VERSION ""

NS_ :

BS_:

BU_: Dummy_PCE EBOOST_OBD_PCE EOCM2cp_K2_PCE EPSb_PCE SDM_PCE EBCM_PCE EPSa_PCE CMMb_PCE CMMa_PCE CGM3b_PCE ADIMa_PCE

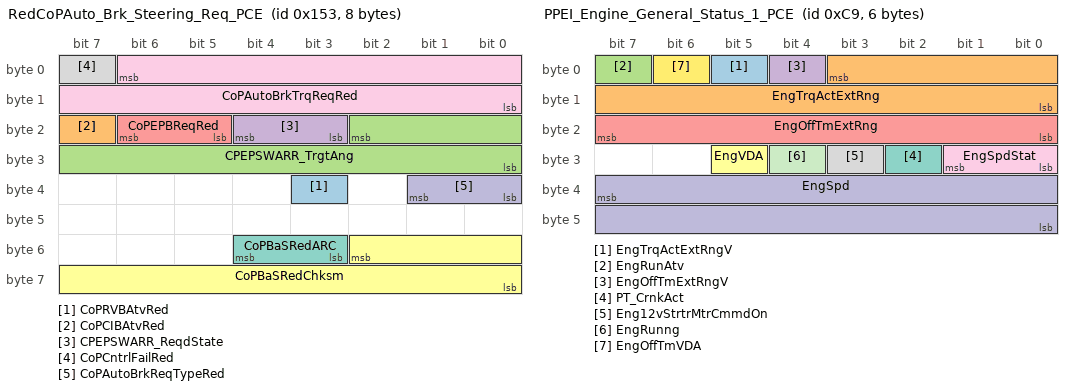
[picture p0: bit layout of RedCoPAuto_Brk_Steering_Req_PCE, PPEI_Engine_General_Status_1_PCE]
BO_ 339 RedCoPAuto_Brk_Steering_Req_PCE: 8 EOCM2cp_K2_PCE
 SG_ CoPRVBAtvRed : 35|1@0+ (1,0) [0|1] ""  ADIMa_PCE,EBOOST_OBD_PCE,EBCM_PCE
 SG_ CoPCIBAtvRed : 23|1@0+ (1,0) [0|1] ""  ADIMa_PCE,EBOOST_OBD_PCE,EBCM_PCE
 SG_ CPEPSWARR_TrgtAng : 18|11@0- (1,0) [-1024|1023] "deg"  ADIMa_PCE,EBOOST_OBD_PCE,EBCM_PCE
 SG_ CPEPSWARR_ReqdState : 20|2@0+ (1,0) [0|3] ""  ADIMa_PCE,EBOOST_OBD_PCE,EBCM_PCE
 SG_ CoPEPBReqRed : 22|2@0+ (1,0) [0|3] ""  ADIMa_PCE,EBOOST_OBD_PCE,EBCM_PCE
 SG_ CoPBaSRedChksm : 50|11@0+ (1,0) [0|2047] ""  ADIMa_PCE,EBOOST_OBD_PCE,EBCM_PCE
 SG_ CoPBaSRedARC : 52|2@0+ (1,0) [0|3] ""  ADIMa_PCE,EBOOST_OBD_PCE,EBCM_PCE
 SG_ CoPCntrlFailRed : 7|1@0+ (1,0) [0|1] ""  ADIMa_PCE,EBOOST_OBD_PCE,EBCM_PCE
 SG_ CoPAutoBrkTrqReqRed : 6|15@0+ (2,-65534) [-65534|0] "Nm"  ADIMa_PCE,EBOOST_OBD_PCE,EBCM_PCE
 SG_ CoPAutoBrkReqTypeRed : 33|2@0+ (1,0) [0|3] ""  ADIMa_PCE,EBOOST_OBD_PCE,EBCM_PCE

BO_ 201 PPEI_Engine_General_Status_1_PCE: 6 EBCM_PCE
 SG_ EngTrqActExtRngV : 5|1@0+ (1,0) [0|1] "" Vector__XXX
 SG_ EngTrqActExtRng : 3|12@0+ (0.5,-848) [-848|1199.5] "Nm" Vector__XXX
 SG_ EngRunAtv : 7|1@0+ (1,0) [0|1] ""  SDM_PCE
 SG_ EngOffTmExtRngV : 4|1@0+ (1,0) [0|1] "" Vector__XXX
 SG_ EngOffTmExtRng : 23|8@0+ (4,0) [0|1020] "min" Vector__XXX
 SG_ EngVDA : 29|1@0+ (1,0) [0|1] "" Vector__XXX
 SG_ PT_CrnkAct : 26|1@0+ (1,0) [0|1] "" Vector__XXX
 SG_ Eng12vStrtrMtrCmmdOn : 27|1@0+ (1,0) [0|1] "" Vector__XXX
 SG_ EngSpdStat : 25|2@0+ (1,0) [0|3] "" Vector__XXX
 SG_ EngSpd : 39|16@0+ (0.25,0) [0|16383.75] "rpm" Vector__XXX
 SG_ EngRunng : 28|1@0+ (1,0) [0|1] "" Vector__XXX
 SG_ EngOffTmVDA : 6|1@0+ (1,0) [0|1] "" Vector__XXX

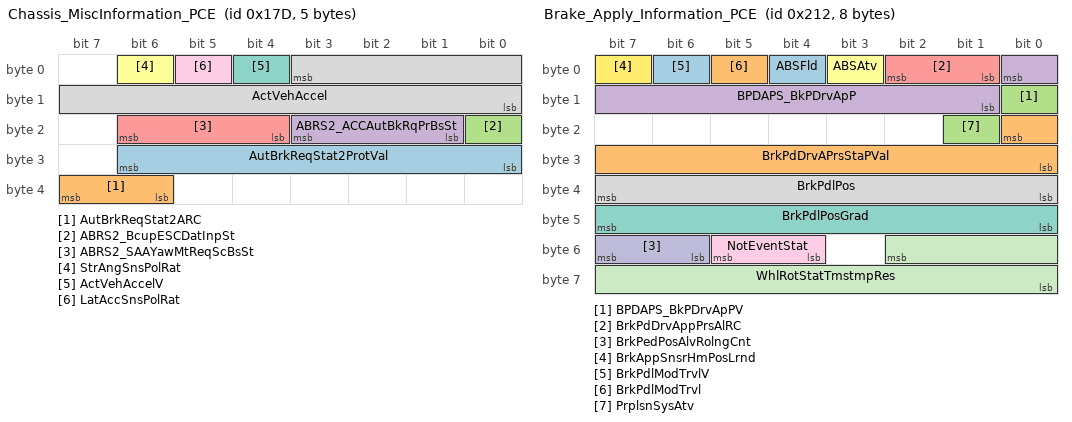
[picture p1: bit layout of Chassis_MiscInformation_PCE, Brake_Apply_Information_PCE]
BO_ 381 Chassis_MiscInformation_PCE: 5 EBCM_PCE
 SG_ AutBrkReqStat2ProtVal : 30|7@0+ (1,0) [0|127] "" Vector__XXX
 SG_ AutBrkReqStat2ARC : 39|2@0+ (1,0) [0|3] "" Vector__XXX
 SG_ ABRS2_BcupESCDatInpSt : 16|1@0+ (1,0) [0|1] "" Vector__XXX
 SG_ ABRS2_ACCAutBkRqPrBsSt : 19|3@0+ (1,0) [0|7] "" Vector__XXX
 SG_ ABRS2_SAAYawMtReqScBsSt : 22|3@0+ (1,0) [0|7] "" Vector__XXX
 SG_ StrAngSnsPolRat : 6|1@0+ (1,0) [0|1] ""  Dummy_PCE
 SG_ ActVehAccelV : 4|1@0+ (1,0) [0|1] "" Vector__XXX
 SG_ ActVehAccel : 3|12@0- (0.01,0) [-20.48|20.47] "m/s^2" Vector__XXX
 SG_ LatAccSnsPolRat : 5|1@0+ (1,0) [0|1] ""  Dummy_PCE

BO_ 530 Brake_Apply_Information_PCE: 8 EBCM_PCE
 SG_ ABSFld : 4|1@0+ (1,0) [0|1] ""  SDM_PCE,EBOOST_OBD_PCE
 SG_ BrkPdDrvAPrsStaPVal : 16|9@0+ (1,0) [0|511] ""  EBOOST_OBD_PCE
 SG_ BPDAPS_BkPDrvApPV : 8|1@0+ (1,0) [0|1] ""  EBOOST_OBD_PCE
 SG_ BPDAPS_BkPDrvApP : 0|8@0+ (75,0) [0|19125] "kPa"  EBOOST_OBD_PCE
 SG_ BrkPdDrvAppPrsAlRC : 2|2@0+ (1,0) [0|3] ""  EBOOST_OBD_PCE
 SG_ ABSAtv : 3|1@0+ (1,0) [0|1] ""  SDM_PCE,EBOOST_OBD_PCE
 SG_ BrkPdlPosGrad : 47|8@0- (40,0) [-5120|5080] "%/s"  EBOOST_OBD_PCE
 SG_ BrkPdlPos : 39|8@0+ (0.392157,0) [0|100.000035] "% full"  EBOOST_OBD_PCE
 SG_ NotEventStat : 53|2@0+ (1,0) [0|3] ""  EBOOST_OBD_PCE
 SG_ BrkPedPosAlvRolngCnt : 55|2@0+ (1,0) [0|3] ""  EBOOST_OBD_PCE
 SG_ WhlRotStatTmstmpRes : 50|11@0+ (0.002,0) [0|4.094] "uSec"  EBOOST_OBD_PCE
 SG_ BrkAppSnsrHmPosLrnd : 7|1@0+ (1,0) [0|1] ""  EBOOST_OBD_PCE
 SG_ BrkPdlModTrvlV : 6|1@0+ (1,0) [0|1] ""  EBOOST_OBD_PCE
 SG_ BrkPdlModTrvl : 5|1@0+ (1,0) [0|1] ""  EBOOST_OBD_PCE
 SG_ PrplsnSysAtv : 17|1@0+ (1,0) [0|1] ""  EBOOST_OBD_PCE,CGM3b_PCE

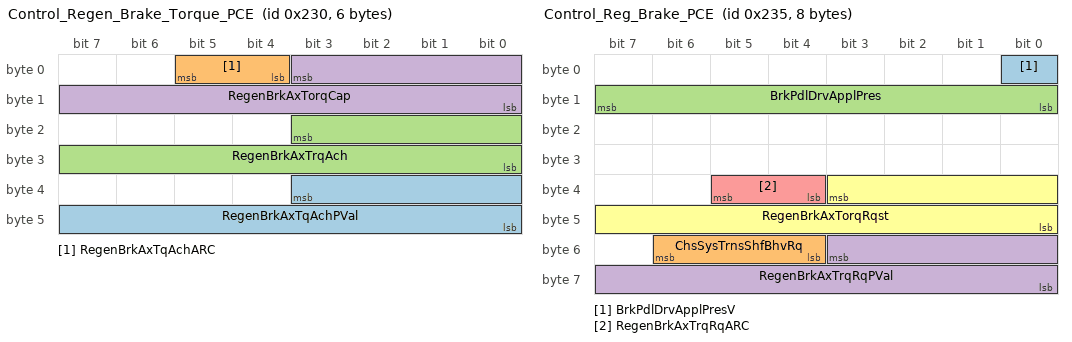
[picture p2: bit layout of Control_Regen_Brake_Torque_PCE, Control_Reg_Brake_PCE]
BO_ 560 Control_Regen_Brake_Torque_PCE: 6 CGM3b_PCE
 SG_ RegenBrkAxTqAchPVal : 35|12@0+ (1,0) [0|4095] ""  EBCM_PCE
 SG_ RegenBrkAxTqAchARC : 5|2@0+ (1,0) [0|3] ""  EBCM_PCE
 SG_ RegenBrkAxTrqAch : 19|12@0+ (2,0) [0|8190] "Nm"  EBCM_PCE
 SG_ RegenBrkAxTorqCap : 3|12@0+ (2,0) [0|8190] "Nm"  EBCM_PCE

BO_ 603 USDT_Req_to_CMM_PCE: 8 CGM3b_PCE
 SG_ DgnInf : 7|64@0+ (1,0) [0|1.84467440737096E+019] ""  CMMa_PCE

BO_ 565 Control_Reg_Brake_PCE: 8 EBCM_PCE
 SG_ BrkPdlDrvApplPresV : 0|1@0+ (1,0) [0|1] ""  ADIMa_PCE,CGM3b_PCE
 SG_ ChsSysTrnsShfBhvRq : 54|3@0+ (1,0) [0|7] ""  ADIMa_PCE,CGM3b_PCE
 SG_ BrkPdlDrvApplPres : 15|8@0+ (75,0) [0|19125] "kPa"  ADIMa_PCE,CGM3b_PCE
 SG_ RegenBrkAxTrqRqPVal : 51|12@0+ (1,0) [0|4095] ""  ADIMa_PCE,CGM3b_PCE
 SG_ RegenBrkAxTrqRqARC : 37|2@0+ (1,0) [0|3] ""  ADIMa_PCE,CGM3b_PCE
 SG_ RegenBrkAxTorqRqst : 35|12@0+ (2,0) [0|8190] "Nm"  ADIMa_PCE,CGM3b_PCE

BO_ 1347 UUDT_Resp_From_EBCM_PCE: 8 EBCM_PCE
 SG_ DgnInf_CE543 : 7|64@0+ (1,0) [0|1.84467440737096E+019] ""  CGM3b_PCE

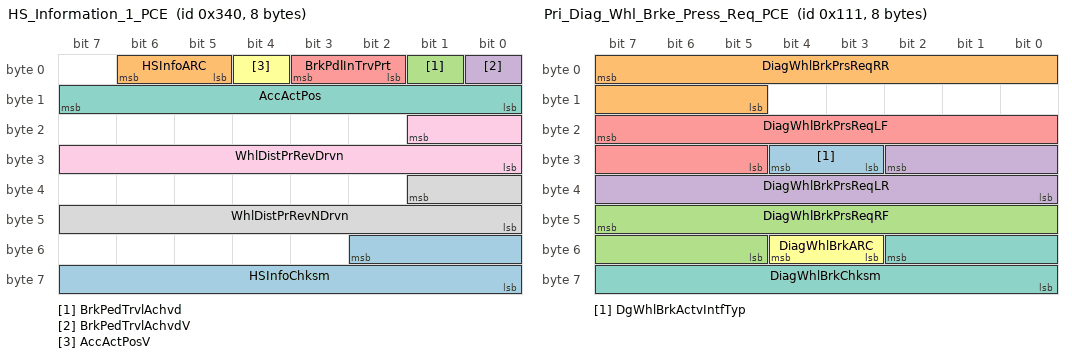
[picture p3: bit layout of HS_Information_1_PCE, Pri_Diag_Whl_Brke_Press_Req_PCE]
BO_ 832 HS_Information_1_PCE: 8 EBCM_PCE
 SG_ HSInfoChksm : 50|11@0+ (1,0) [0|2047] "" Vector__XXX
 SG_ HSInfoARC : 6|2@0+ (1,0) [0|3] "" Vector__XXX
 SG_ BrkPedTrvlAchvd : 1|1@0+ (1,0) [0|1] ""  SDM_PCE
 SG_ BrkPedTrvlAchvdV : 0|1@0+ (1,0) [0|1] ""  SDM_PCE
 SG_ BrkPdlInTrvPrt : 3|2@0+ (1,0) [0|3] "" Vector__XXX
 SG_ AccActPosV : 4|1@0+ (1,0) [0|1] "" Vector__XXX
 SG_ AccActPos : 15|8@0+ (0.392157,0) [0|100.000035] "%" Vector__XXX
 SG_ WhlDistPrRevNDrvn : 33|10@0+ (3,800) [800|3869] "mm"  SDM_PCE
 SG_ WhlDistPrRevDrvn : 17|10@0+ (3,800) [800|3869] "mm"  SDM_PCE

BO_ 1622 USDT_Resp_From_CMMb_PCE: 8 CMMb_PCE
 SG_ DgnInf : 7|64@0+ (1,0) [0|1.84467440737096E+019] ""  CGM3b_PCE

BO_ 1351 UUDT_Resp_From_SDM_PCE: 8 SDM_PCE
 SG_ DgnInf_CE547 : 7|64@0+ (1,0) [0|1.84467440737096E+019] ""  CGM3b_PCE

BO_ 1346 UUDT_Resp_From_EPSa_PCE: 8 EPSa_PCE
 SG_ DgnInf_CE542 : 7|64@0+ (1,0) [0|1.84467440737096E+019] ""  CGM3b_PCE

BO_ 1607 USDT_Resp_From_SDM_PCE: 8 SDM_PCE
 SG_ DgnInf : 7|64@0+ (1,0) [0|1.84467440737096E+019] ""  CGM3b_PCE

BO_ 1602 USDT_Resp_From_EPSa_PCE: 8 EPSa_PCE
 SG_ DgnInf : 7|64@0+ (1,0) [0|1.84467440737096E+019] ""  CGM3b_PCE

BO_ 273 Pri_Diag_Whl_Brke_Press_Req_PCE: 8 ADIMa_PCE
 SG_ DgWhlBrkActvIntfTyp : 28|2@0+ (1,0) [0|3] ""  EBCM_PCE
 SG_ DiagWhlBrkPrsReqRR : 7|11@0+ (10,0) [0|20470] "Kpa"  EBCM_PCE
 SG_ DiagWhlBrkPrsReqRF : 47|11@0+ (10,0) [0|20470] "Kpa"  EBCM_PCE
 SG_ DiagWhlBrkPrsReqLR : 26|11@0+ (10,0) [0|20470] "Kpa"  EBCM_PCE
 SG_ DiagWhlBrkPrsReqLF : 23|11@0+ (10,0) [0|20470] "Kpa"  EBCM_PCE
 SG_ DiagWhlBrkARC : 52|2@0+ (1,0) [0|3] ""  EBCM_PCE
 SG_ DiagWhlBrkChksm : 50|11@0+ (1,0) [0|2047] ""  EBCM_PCE

BO_ 598 USDT_Req_to_CMMb_PCE: 8 CGM3b_PCE
 SG_ DgnInf : 7|64@0+ (1,0) [0|1.84467440737096E+019] ""  CMMb_PCE

BO_ 1352 UUDT_Resp_From_EPSb_PCE: 8 EPSb_PCE
 SG_ DgnInf_CE548 : 7|64@0+ (1,0) [0|1.84467440737096E+019] ""  CGM3b_PCE

BO_ 578 USDT_Req_to_EPSa_PCE: 8 CGM3b_PCE
 SG_ DgnInf : 7|64@0+ (1,0) [0|1.84467440737096E+019] ""  EPSa_PCE

BO_ 579 USDT_Req_to_EBCM_PCE: 8 CGM3b_PCE
 SG_ DgnInf : 7|64@0+ (1,0) [0|1.84467440737096E+019] ""  EBCM_PCE

BO_ 1364 UUDT_Resp_From_EBoost_PCE: 8 EBOOST_OBD_PCE
 SG_ DgnInf_CE554 : 7|64@0+ (1,0) [0|1.84467440737096E+019] ""  CGM3b_PCE

BO_ 1355 UUDT_Resp_From_EOCM2cp_K2_PCE: 8 EOCM2cp_K2_PCE
 SG_ DgnInf_CE54B : 7|64@0+ (1,0) [0|1.84467440737096E+019] ""  CGM3b_PCE

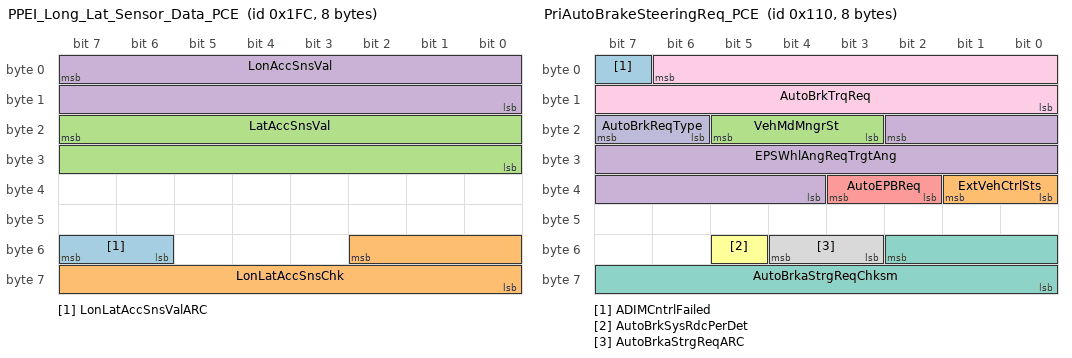
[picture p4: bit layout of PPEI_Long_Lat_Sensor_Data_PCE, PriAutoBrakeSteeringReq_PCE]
BO_ 508 PPEI_Long_Lat_Sensor_Data_PCE: 8 SDM_PCE
 SG_ LonLatAccSnsValARC : 55|2@0+ (1,0) [0|3] ""  EBCM_PCE,EBOOST_OBD_PCE
 SG_ LonLatAccSnsChk : 50|11@0+ (1,0) [0|2047] ""  EBCM_PCE,EBOOST_OBD_PCE
 SG_ LatAccSnsVal : 23|16@0- (0.00012207,0) [-3.99998976|3.99986769] "g's"  EBCM_PCE,EBOOST_OBD_PCE
 SG_ LonAccSnsVal : 7|16@0- (0.00012207,0) [-3.99998976|3.99986769] "g's"  EBCM_PCE,EBOOST_OBD_PCE

BO_ 1603 USDT_Resp_From_EBCM_PCE: 8 EBCM_PCE
 SG_ DgnInf : 7|64@0+ (1,0) [0|1.84467440737096E+019] ""  CGM3b_PCE

BO_ 272 PriAutoBrakeSteeringReq_PCE: 8 ADIMa_PCE
 SG_ ADIMCntrlFailed : 7|1@0+ (1,0) [0|1] ""  SDM_PCE,EOCM2cp_K2_PCE,EPSb_PCE,EPSa_PCE,EBOOST_OBD_PCE,EBCM_PCE
 SG_ ExtVehCtrlSts : 33|2@0+ (1,0) [0|2] ""  EBOOST_OBD_PCE,EBCM_PCE
 SG_ VehMdMngrSt : 21|3@0+ (1,0) [0|7] ""  EPSb_PCE,SDM_PCE,EOCM2cp_K2_PCE,EPSa_PCE,EBOOST_OBD_PCE,EBCM_PCE
 SG_ EPSWhlAngReqTrgtAng : 18|15@0- (0.0625,0) [-1024|1023.9375] "Deg"  EPSb_PCE,SDM_PCE,EPSa_PCE,EBOOST_OBD_PCE,EBCM_PCE
 SG_ AutoEPBReq : 35|2@0+ (1,0) [0|3] ""  EPSb_PCE,SDM_PCE,EPSa_PCE,EBOOST_OBD_PCE,EBCM_PCE
 SG_ AutoBrkSysRdcPerDet : 53|1@0+ (1,0) [0|1] ""  EBCM_PCE,EBOOST_OBD_PCE
 SG_ AutoBrkaStrgReqChksm : 50|11@0+ (1,0) [0|2047] ""  EPSb_PCE,SDM_PCE,EPSa_PCE,EBOOST_OBD_PCE,EBCM_PCE
 SG_ AutoBrkaStrgReqARC : 52|2@0+ (1,0) [0|3] ""  EPSb_PCE,SDM_PCE,EPSa_PCE,EBOOST_OBD_PCE,EBCM_PCE
 SG_ AutoBrkTrqReq : 6|15@0+ (2,-65534) [-65534|0] "Nm"  EPSb_PCE,SDM_PCE,EPSa_PCE,EBOOST_OBD_PCE,EBCM_PCE
 SG_ AutoBrkReqType : 23|2@0+ (1,0) [0|3] ""  EPSb_PCE,SDM_PCE,EPSa_PCE,EBOOST_OBD_PCE,EBCM_PCE

BO_ 583 USDT_Req_to_SDM_PCE: 8 CGM3b_PCE
 SG_ DgnInf : 7|64@0+ (1,0) [0|1.84467440737096E+019] ""  SDM_PCE

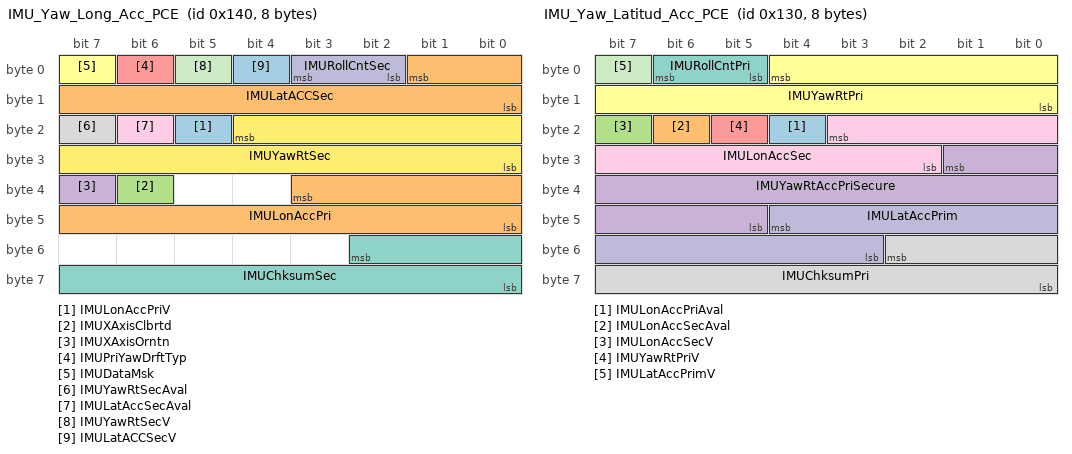
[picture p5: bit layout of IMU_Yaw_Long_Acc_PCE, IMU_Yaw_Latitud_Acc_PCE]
BO_ 320 IMU_Yaw_Long_Acc_PCE: 8 SDM_PCE
 SG_ IMULonAccPriV : 21|1@0+ (1,0) [0|1] ""  EOCM2cp_K2_PCE,CGM3b_PCE,EBCM_PCE,EBOOST_OBD_PCE
 SG_ IMULonAccPri : 35|12@0- (0.015625,0) [-32|31.984375] "m/s^2"  CGM3b_PCE,EOCM2cp_K2_PCE,EBCM_PCE,EBOOST_OBD_PCE
 SG_ IMUXAxisClbrtd : 38|1@0+ (1,0) [0|1] ""  EOCM2cp_K2_PCE,CGM3b_PCE,EBCM_PCE,EBOOST_OBD_PCE
 SG_ IMUXAxisOrntn : 39|1@0+ (1,0) [0|1] ""  EOCM2cp_K2_PCE,CGM3b_PCE,EBCM_PCE,EBOOST_OBD_PCE
 SG_ IMUPriYawDrftTyp : 6|1@0+ (1,0) [0|1] ""  EOCM2cp_K2_PCE,CGM3b_PCE,EBCM_PCE,EBOOST_OBD_PCE
 SG_ IMUDataMsk : 7|1@0+ (1,0) [0|1] ""  CGM3b_PCE,EOCM2cp_K2_PCE,EBCM_PCE,EBOOST_OBD_PCE
 SG_ IMUChksumSec : 50|11@0+ (1,0) [0|2047] ""  CGM3b_PCE,EOCM2cp_K2_PCE,EBOOST_OBD_PCE,EBCM_PCE
 SG_ IMUYawRtSecAval : 23|1@0+ (1,0) [0|1] ""  EOCM2cp_K2_PCE,CGM3b_PCE,EBOOST_OBD_PCE,EBCM_PCE
 SG_ IMULatAccSecAval : 22|1@0+ (1,0) [0|1] ""  CGM3b_PCE,EOCM2cp_K2_PCE,EBOOST_OBD_PCE,EBCM_PCE
 SG_ IMURollCntSec : 3|2@0+ (1,0) [0|3] ""  EOCM2cp_K2_PCE,CGM3b_PCE,EBOOST_OBD_PCE,EBCM_PCE
 SG_ IMUYawRtSecV : 5|1@0+ (1,0) [0|1] ""  EOCM2cp_K2_PCE,CGM3b_PCE,EBOOST_OBD_PCE,EBCM_PCE
 SG_ IMUYawRtSec : 20|13@0- (0.024,0) [-98.304|98.28] "deg/sec"  EOCM2cp_K2_PCE,CGM3b_PCE,EBOOST_OBD_PCE,EBCM_PCE
 SG_ IMULatACCSecV : 4|1@0+ (1,0) [0|1] ""  CGM3b_PCE,EOCM2cp_K2_PCE,EBOOST_OBD_PCE,EBCM_PCE
 SG_ IMULatACCSec : 1|10@0- (0.0625,0) [-32|31.9375] "m/s^2"  CGM3b_PCE,EOCM2cp_K2_PCE,EBOOST_OBD_PCE,EBCM_PCE

BO_ 304 IMU_Yaw_Latitud_Acc_PCE: 8 SDM_PCE
 SG_ IMULonAccPriAval : 20|1@0+ (1,0) [0|1] ""  CGM3b_PCE,EOCM2cp_K2_PCE,EBCM_PCE,EBOOST_OBD_PCE
 SG_ IMULonAccSecAval : 22|1@0+ (1,0) [0|1] ""  CGM3b_PCE,EOCM2cp_K2_PCE,EBCM_PCE,EBOOST_OBD_PCE
 SG_ IMULonAccSecV : 23|1@0+ (1,0) [0|1] ""  CGM3b_PCE,EOCM2cp_K2_PCE,EBCM_PCE,EBOOST_OBD_PCE
 SG_ IMUYawRtAccPriSecure : 25|13@0- (0.25,0) [-1024|1023.75] "deg/s^2"  CGM3b_PCE,EOCM2cp_K2_PCE,EBCM_PCE,EBOOST_OBD_PCE
 SG_ IMUYawRtPriV : 21|1@0+ (1,0) [0|1] ""  CGM3b_PCE,EOCM2cp_K2_PCE,EBOOST_OBD_PCE,EBCM_PCE
 SG_ IMUYawRtPri : 4|13@0- (0.024,0) [-98.304|98.28] "deg/sec"  CGM3b_PCE,EOCM2cp_K2_PCE,EBOOST_OBD_PCE,EBCM_PCE
 SG_ IMURollCntPri : 6|2@0+ (1,0) [0|3] ""  CGM3b_PCE,EOCM2cp_K2_PCE,EBOOST_OBD_PCE,EBCM_PCE
 SG_ IMUChksumPri : 50|11@0+ (1,0) [0|2047] ""  CGM3b_PCE,EOCM2cp_K2_PCE,EBOOST_OBD_PCE,EBCM_PCE
 SG_ IMULonAccSec : 19|10@0- (0.0625,0) [-32|31.9375] "m/s^2"  CGM3b_PCE,EOCM2cp_K2_PCE,EBCM_PCE,EBOOST_OBD_PCE
 SG_ IMULatAccPrim : 44|10@0- (0.0625,0) [-32|31.9375] "m/s^2"  CGM3b_PCE,EOCM2cp_K2_PCE,EBOOST_OBD_PCE,EBCM_PCE
 SG_ IMULatAccPrimV : 7|1@0+ (1,0) [0|1] ""  CGM3b_PCE,EOCM2cp_K2_PCE,EBOOST_OBD_PCE,EBCM_PCE

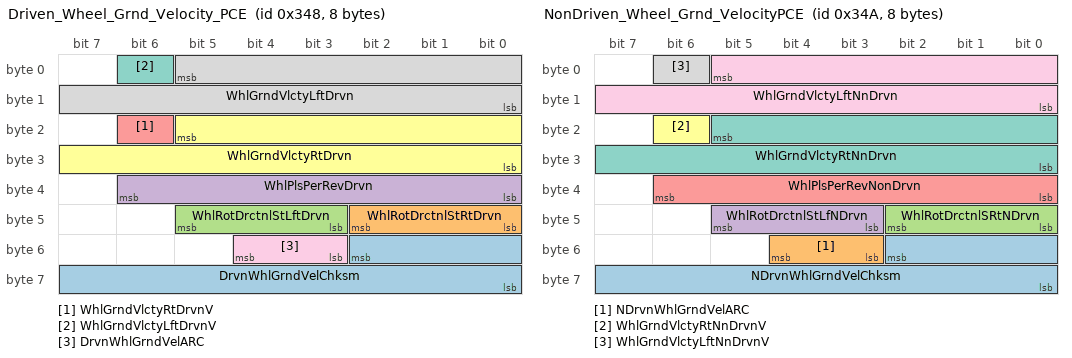
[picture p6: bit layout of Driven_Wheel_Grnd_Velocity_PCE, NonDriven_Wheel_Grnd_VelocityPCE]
BO_ 840 Driven_Wheel_Grnd_Velocity_PCE: 8 EBCM_PCE
 SG_ DrvnWhlGrndVelChksm : 50|11@0+ (1,0) [0|2047] ""  ADIMa_PCE,EPSb_PCE,EPSa_PCE,EBOOST_OBD_PCE
 SG_ WhlRotDrctnlStRtDrvn : 42|3@0+ (1,0) [0|7] ""  ADIMa_PCE,EBOOST_OBD_PCE,EOCM2cp_K2_PCE
 SG_ WhlRotDrctnlStLftDrvn : 45|3@0+ (1,0) [0|7] ""  ADIMa_PCE,EBOOST_OBD_PCE,EOCM2cp_K2_PCE
 SG_ WhlPlsPerRevDrvn : 38|7@0+ (1,0) [0|127] ""  ADIMa_PCE,EBOOST_OBD_PCE,EPSb_PCE,EPSa_PCE,EOCM2cp_K2_PCE
 SG_ WhlGrndVlctyRtDrvnV : 22|1@0+ (1,0) [0|1] ""  CGM3b_PCE,ADIMa_PCE,EBOOST_OBD_PCE,SDM_PCE,EPSb_PCE,EPSa_PCE,EOCM2cp_K2_PCE
 SG_ WhlGrndVlctyRtDrvn : 21|14@0+ (0.03125,0) [0|511.96875] "km / h"  CGM3b_PCE,ADIMa_PCE,EBOOST_OBD_PCE,SDM_PCE,EPSb_PCE,EPSa_PCE,EOCM2cp_K2_PCE
 SG_ WhlGrndVlctyLftDrvnV : 6|1@0+ (1,0) [0|1] ""  CGM3b_PCE,ADIMa_PCE,EBOOST_OBD_PCE,SDM_PCE,EPSb_PCE,EPSa_PCE,EOCM2cp_K2_PCE
 SG_ WhlGrndVlctyLftDrvn : 5|14@0+ (0.03125,0) [0|511.96875] "km / h"  CGM3b_PCE,ADIMa_PCE,EBOOST_OBD_PCE,SDM_PCE,EPSb_PCE,EPSa_PCE,EOCM2cp_K2_PCE
 SG_ DrvnWhlGrndVelARC : 52|2@0+ (1,0) [0|3] ""  ADIMa_PCE,EPSb_PCE,EPSa_PCE,EBOOST_OBD_PCE

BO_ 842 NonDriven_Wheel_Grnd_VelocityPCE: 8 EBCM_PCE
 SG_ NDrvnWhlGrndVelChksm : 50|11@0+ (1,0) [0|2047] ""  ADIMa_PCE,EPSb_PCE,EPSa_PCE,EBOOST_OBD_PCE
 SG_ NDrvnWhlGrndVelARC : 52|2@0+ (1,0) [0|3] ""  ADIMa_PCE,EPSb_PCE,EPSa_PCE,EBOOST_OBD_PCE
 SG_ WhlRotDrctnlSRtNDrvn : 42|3@0+ (1,0) [0|7] ""  ADIMa_PCE,EBOOST_OBD_PCE,EOCM2cp_K2_PCE
 SG_ WhlRotDrctnlStLfNDrvn : 45|3@0+ (1,0) [0|7] ""  ADIMa_PCE,EBOOST_OBD_PCE,EOCM2cp_K2_PCE
 SG_ WhlPlsPerRevNonDrvn : 38|7@0+ (1,0) [0|127] ""  ADIMa_PCE,EBOOST_OBD_PCE,EOCM2cp_K2_PCE,EPSb_PCE,EPSa_PCE
 SG_ WhlGrndVlctyRtNnDrvnV : 22|1@0+ (1,0) [0|1] ""  ADIMa_PCE,EBOOST_OBD_PCE,EOCM2cp_K2_PCE,SDM_PCE,EPSb_PCE,EPSa_PCE
 SG_ WhlGrndVlctyRtNnDrvn : 21|14@0+ (0.03125,0) [0|511.96875] "km / h"  ADIMa_PCE,EBOOST_OBD_PCE,EOCM2cp_K2_PCE,SDM_PCE,EPSb_PCE,EPSa_PCE
 SG_ WhlGrndVlctyLftNnDrvnV : 6|1@0+ (1,0) [0|1] ""  ADIMa_PCE,EBOOST_OBD_PCE,EOCM2cp_K2_PCE,SDM_PCE,EPSb_PCE,EPSa_PCE
 SG_ WhlGrndVlctyLftNnDrvn : 5|14@0+ (0.03125,0) [0|511.96875] "km / h"  ADIMa_PCE,EBOOST_OBD_PCE,EOCM2cp_K2_PCE,SDM_PCE,EPSb_PCE,EPSa_PCE

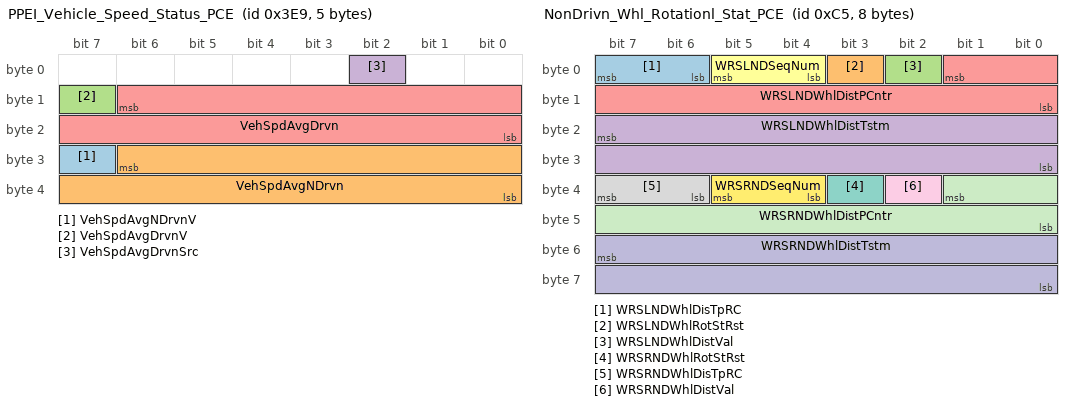
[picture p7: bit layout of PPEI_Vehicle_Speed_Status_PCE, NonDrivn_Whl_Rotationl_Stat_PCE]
BO_ 1001 PPEI_Vehicle_Speed_Status_PCE: 5 EBCM_PCE
 SG_ VehSpdAvgNDrvnV : 31|1@0+ (1,0) [0|1] ""  SDM_PCE,EPSb_PCE,EPSa_PCE
 SG_ VehSpdAvgNDrvn : 30|15@0+ (0.015625,0) [0|511.984375] "km / h"  SDM_PCE,EPSb_PCE,EPSa_PCE
 SG_ VehSpdAvgDrvnV : 15|1@0+ (1,0) [0|1] ""  SDM_PCE,EPSb_PCE,EPSa_PCE
 SG_ VehSpdAvgDrvnSrc : 2|1@0+ (1,0) [0|1] ""  EPSb_PCE,EPSa_PCE
 SG_ VehSpdAvgDrvn : 14|15@0+ (0.015625,0) [0|511.984375] "km / h"  SDM_PCE,EPSb_PCE,EPSa_PCE,CGM3b_PCE

BO_ 1608 USDT_Resp_From_EPSb_PCE: 8 EPSb_PCE
 SG_ DgnInf : 7|64@0+ (1,0) [0|1.84467440737096E+019] ""  CGM3b_PCE

BO_ 197 NonDrivn_Whl_Rotationl_Stat_PCE: 8 EBCM_PCE
 SG_ WRSLNDWhlDisTpRC : 7|2@0+ (1,0) [0|3] "counts"  ADIMa_PCE,CMMb_PCE,CMMa_PCE,CGM3b_PCE,SDM_PCE,EOCM2cp_K2_PCE
 SG_ WRSLNDWhlRotStRst : 3|1@0+ (1,0) [0|1] ""  ADIMa_PCE,CMMb_PCE,CMMa_PCE,CGM3b_PCE,SDM_PCE,EOCM2cp_K2_PCE
 SG_ WRSLNDWhlDistVal : 2|1@0+ (1,0) [0|1] ""  ADIMa_PCE,CMMb_PCE,CMMa_PCE,CGM3b_PCE,SDM_PCE,EOCM2cp_K2_PCE
 SG_ WRSLNDWhlDistTstm : 23|16@0+ (1,0) [0|65535] "counts"  ADIMa_PCE,CMMb_PCE,CMMa_PCE,CGM3b_PCE,SDM_PCE,EOCM2cp_K2_PCE
 SG_ WRSLNDWhlDistPCntr : 1|10@0+ (1,0) [0|1023] "counts"  ADIMa_PCE,CMMb_PCE,CMMa_PCE,CGM3b_PCE,SDM_PCE,EOCM2cp_K2_PCE
 SG_ WRSLNDSeqNum : 5|2@0+ (1,0) [0|3] "counts"  ADIMa_PCE,CMMb_PCE,CMMa_PCE,CGM3b_PCE,SDM_PCE,EOCM2cp_K2_PCE
 SG_ WRSRNDWhlRotStRst : 35|1@0+ (1,0) [0|1] ""  ADIMa_PCE,CMMb_PCE,CMMa_PCE,CGM3b_PCE,SDM_PCE,EOCM2cp_K2_PCE
 SG_ WRSRNDWhlDisTpRC : 39|2@0+ (1,0) [0|3] "counts"  ADIMa_PCE,CMMb_PCE,CMMa_PCE,CGM3b_PCE,SDM_PCE,EOCM2cp_K2_PCE
 SG_ WRSRNDWhlDistVal : 34|1@0+ (1,0) [0|1] ""  ADIMa_PCE,CMMb_PCE,CMMa_PCE,CGM3b_PCE,SDM_PCE,EOCM2cp_K2_PCE
 SG_ WRSRNDWhlDistTstm : 55|16@0+ (1,0) [0|65535] "counts"  ADIMa_PCE,CMMb_PCE,CMMa_PCE,CGM3b_PCE,SDM_PCE,EOCM2cp_K2_PCE
 SG_ WRSRNDWhlDistPCntr : 33|10@0+ (1,0) [0|1023] "counts"  ADIMa_PCE,CMMb_PCE,CMMa_PCE,CGM3b_PCE,SDM_PCE,EOCM2cp_K2_PCE
 SG_ WRSRNDSeqNum : 37|2@0+ (1,0) [0|3] "counts"  ADIMa_PCE,CMMb_PCE,CMMa_PCE,CGM3b_PCE,SDM_PCE,EOCM2cp_K2_PCE

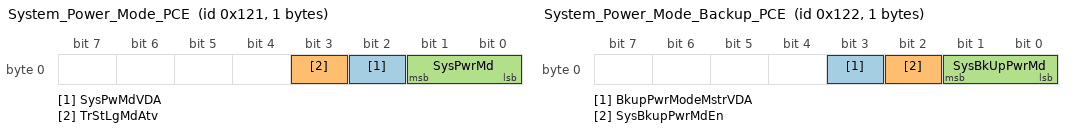
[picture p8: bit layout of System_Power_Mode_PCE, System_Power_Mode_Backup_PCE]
BO_ 289 System_Power_Mode_PCE: 1 EBCM_PCE
 SG_ SysPwMdVDA : 2|1@0+ (1,0) [0|1] ""  SDM_PCE,CGM3b_PCE,EBOOST_OBD_PCE
 SG_ TrStLgMdAtv : 3|1@0+ (1,0) [0|1] ""  EBOOST_OBD_PCE,CGM3b_PCE
 SG_ SysPwrMd : 1|2@0+ (1,0) [0|3] ""  CGM3b_PCE,EBOOST_OBD_PCE,SDM_PCE

BO_ 290 System_Power_Mode_Backup_PCE: 1 EBCM_PCE
 SG_ BkupPwrModeMstrVDA : 3|1@0+ (1,0) [0|1] ""  CGM3b_PCE,EBOOST_OBD_PCE,SDM_PCE
 SG_ SysBkupPwrMdEn : 2|1@0+ (1,0) [0|1] ""  CGM3b_PCE,EBOOST_OBD_PCE,SDM_PCE
 SG_ SysBkUpPwrMd : 1|2@0+ (1,0) [0|3] ""  EBOOST_OBD_PCE,SDM_PCE,CGM3b_PCE

BO_ 1371 UUDT_Resp_From_CMM_PCE: 8 CMMa_PCE
 SG_ DgnInf_CE55B : 7|64@0+ (1,0) [0|1.84467440737096E+019] ""  CGM3b_PCE

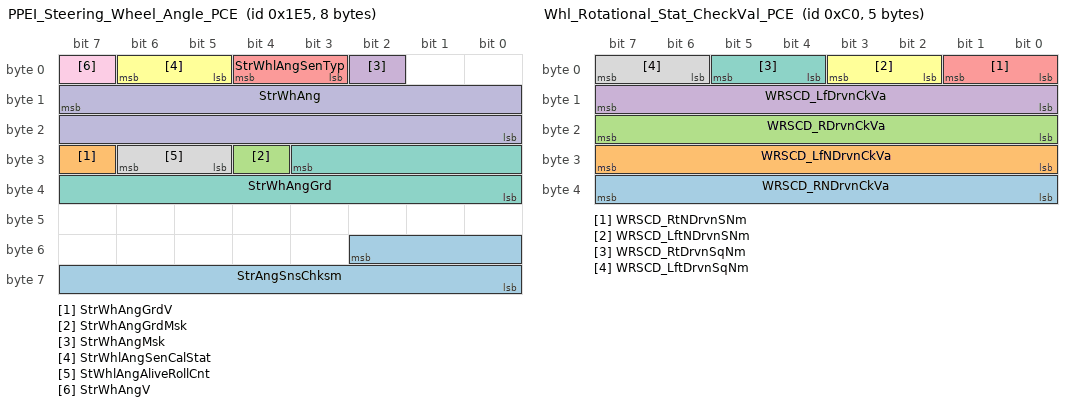
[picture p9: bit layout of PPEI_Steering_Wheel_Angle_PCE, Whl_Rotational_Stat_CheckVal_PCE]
BO_ 485 PPEI_Steering_Wheel_Angle_PCE: 8 EPSa_PCE
 SG_ StrAngSnsChksm : 50|11@0+ (1,0) [0|2047] ""  CMMb_PCE,CMMa_PCE,ADIMa_PCE,EOCM2cp_K2_PCE,CGM3b_PCE,EBCM_PCE
 SG_ StrWhAngGrdV : 31|1@0+ (1,0) [0|1] ""  CMMb_PCE,CMMa_PCE,ADIMa_PCE,SDM_PCE,EOCM2cp_K2_PCE,CGM3b_PCE,EBCM_PCE
 SG_ StrWhAngGrdMsk : 28|1@0+ (1,0) [0|1] ""  CMMb_PCE,CMMa_PCE,ADIMa_PCE,EOCM2cp_K2_PCE,CGM3b_PCE,EBCM_PCE
 SG_ StrWhAngMsk : 2|1@0+ (1,0) [0|1] ""  CMMb_PCE,CMMa_PCE,ADIMa_PCE,SDM_PCE,EOCM2cp_K2_PCE,CGM3b_PCE,EBCM_PCE
 SG_ StrWhlAngSenTyp : 4|2@0+ (1,0) [0|3] ""  CMMb_PCE,CMMa_PCE,ADIMa_PCE,EOCM2cp_K2_PCE,CGM3b_PCE,SDM_PCE,EBCM_PCE
 SG_ StrWhlAngSenCalStat : 6|2@0+ (1,0) [0|3] ""  CMMb_PCE,CMMa_PCE,ADIMa_PCE,EOCM2cp_K2_PCE,CGM3b_PCE,SDM_PCE,EBCM_PCE
 SG_ StrWhAngGrd : 27|12@0- (1,0) [-2048|2047] "deg/sec"  CMMb_PCE,CMMa_PCE,ADIMa_PCE,SDM_PCE,EOCM2cp_K2_PCE,CGM3b_PCE,EBCM_PCE
 SG_ StWhlAngAliveRollCnt : 30|2@0+ (1,0) [0|3] ""  CMMb_PCE,CMMa_PCE,ADIMa_PCE,EOCM2cp_K2_PCE,CGM3b_PCE,SDM_PCE,EBCM_PCE
 SG_ StrWhAngV : 7|1@0+ (1,0) [0|1] ""  CMMb_PCE,CMMa_PCE,ADIMa_PCE,EOCM2cp_K2_PCE,CGM3b_PCE,SDM_PCE,EBCM_PCE
 SG_ StrWhAng : 15|16@0- (0.0625,0) [-2048|2047.9375] "deg"  CMMb_PCE,CMMa_PCE,ADIMa_PCE,SDM_PCE,EOCM2cp_K2_PCE,CGM3b_PCE,EBCM_PCE

BO_ 192 Whl_Rotational_Stat_CheckVal_PCE: 5 EBCM_PCE
 SG_ WRSCD_RNDrvnCkVa : 39|8@0+ (1,0) [0|255] ""  CMMb_PCE,CMMa_PCE,EOCM2cp_K2_PCE
 SG_ WRSCD_LfNDrvnCkVa : 31|8@0+ (1,0) [0|255] ""  CMMb_PCE,CMMa_PCE,EOCM2cp_K2_PCE
 SG_ WRSCD_RDrvnCkVa : 23|8@0+ (1,0) [0|255] ""  CMMb_PCE,CMMa_PCE,EOCM2cp_K2_PCE
 SG_ WRSCD_LfDrvnCkVa : 15|8@0+ (1,0) [0|255] ""  CMMb_PCE,CMMa_PCE,EOCM2cp_K2_PCE
 SG_ WRSCD_RtNDrvnSNm : 1|2@0+ (1,0) [0|3] ""  CMMb_PCE,CMMa_PCE,EOCM2cp_K2_PCE
 SG_ WRSCD_LftNDrvnSNm : 3|2@0+ (1,0) [0|3] ""  CMMb_PCE,CMMa_PCE,EOCM2cp_K2_PCE
 SG_ WRSCD_RtDrvnSqNm : 5|2@0+ (1,0) [0|3] ""  CMMb_PCE,CMMa_PCE,EOCM2cp_K2_PCE
 SG_ WRSCD_LftDrvnSqNm : 7|2@0+ (1,0) [0|3] ""  CMMb_PCE,CMMa_PCE,EOCM2cp_K2_PCE

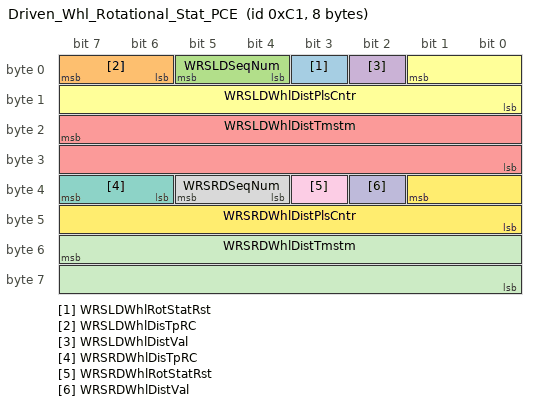
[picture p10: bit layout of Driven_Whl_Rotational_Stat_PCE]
BO_ 193 Driven_Whl_Rotational_Stat_PCE: 8 EBCM_PCE
 SG_ WRSLDWhlRotStatRst : 3|1@0+ (1,0) [0|1] ""  ADIMa_PCE,CMMb_PCE,CMMa_PCE,CGM3b_PCE,EOCM2cp_K2_PCE,SDM_PCE
 SG_ WRSLDWhlDisTpRC : 7|2@0+ (1,0) [0|3] "counts"  ADIMa_PCE,CMMb_PCE,CMMa_PCE,CGM3b_PCE,EOCM2cp_K2_PCE,SDM_PCE
 SG_ WRSLDSeqNum : 5|2@0+ (1,0) [0|3] "counts"  ADIMa_PCE,CMMb_PCE,CMMa_PCE,CGM3b_PCE,EOCM2cp_K2_PCE,SDM_PCE
 SG_ WRSLDWhlDistVal : 2|1@0+ (1,0) [0|1] ""  ADIMa_PCE,CMMb_PCE,CMMa_PCE,CGM3b_PCE,EOCM2cp_K2_PCE,SDM_PCE
 SG_ WRSLDWhlDistTmstm : 23|16@0+ (1,0) [0|65535] "counts"  ADIMa_PCE,CMMb_PCE,CMMa_PCE,CGM3b_PCE,EOCM2cp_K2_PCE,SDM_PCE
 SG_ WRSLDWhlDistPlsCntr : 1|10@0+ (1,0) [0|1023] "counts"  ADIMa_PCE,CMMb_PCE,CMMa_PCE,CGM3b_PCE,EOCM2cp_K2_PCE,SDM_PCE
 SG_ WRSRDWhlDisTpRC : 39|2@0+ (1,0) [0|3] "counts"  ADIMa_PCE,CMMb_PCE,CMMa_PCE,CGM3b_PCE,EOCM2cp_K2_PCE,SDM_PCE
 SG_ WRSRDSeqNum : 37|2@0+ (1,0) [0|3] "counts"  ADIMa_PCE,CMMb_PCE,CMMa_PCE,CGM3b_PCE,EOCM2cp_K2_PCE,SDM_PCE
 SG_ WRSRDWhlRotStatRst : 35|1@0+ (1,0) [0|1] ""  ADIMa_PCE,CMMb_PCE,CMMa_PCE,CGM3b_PCE,EOCM2cp_K2_PCE,SDM_PCE
 SG_ WRSRDWhlDistVal : 34|1@0+ (1,0) [0|1] ""  ADIMa_PCE,CMMb_PCE,CMMa_PCE,CGM3b_PCE,EOCM2cp_K2_PCE,SDM_PCE
 SG_ WRSRDWhlDistTmstm : 55|16@0+ (1,0) [0|65535] "counts"  ADIMa_PCE,CMMb_PCE,CMMa_PCE,CGM3b_PCE,EOCM2cp_K2_PCE,SDM_PCE
 SG_ WRSRDWhlDistPlsCntr : 33|10@0+ (1,0) [0|1023] "counts"  ADIMa_PCE,CMMb_PCE,CMMa_PCE,CGM3b_PCE,EOCM2cp_K2_PCE,SDM_PCE

BO_ 257 USDT_Req_to_All_PCE_ECUs_PCE: 8 CGM3b_PCE
 SG_ DgnInf : 7|64@0+ (1,0) [0|1.84467440737096E+019] ""  CMMb_PCE,EPSb_PCE,EOCM2cp_K2_PCE,EBOOST_OBD_PCE,EBCM_PCE,ADIMa_PCE,EPSa_PCE,CMMa_PCE,SDM_PCE

BO_ 1367 UUDT_Resp_From_ADIMa_PCE: 8 ADIMa_PCE
 SG_ DgnInf_CE557 : 7|64@0+ (1,0) [0|1.84467440737096E+019] ""  CGM3b_PCE

BO_ 599 USDT_Req_to_ADIMa_PCE: 8 CGM3b_PCE
 SG_ DgnInf : 7|64@0+ (1,0) [0|1.84467440737096E+019] ""  ADIMa_PCE

CM_ SG_ 201 EngRunAtv "Indication from powertrain that the engine is running (Has RPM > 0)";
CM_ SG_ 530 BrkPdlModTrvlV "Indicates that the brake pedal position has passed a threshold for brake torque management and some 2 channel Vehicle Dynamics Control systems.";
CM_ SG_ 530 BrkPdlModTrvl "Indicates that the brake pedal position has passed a threshold for brake torque management and some 2 channel Vehicle Dynamics Control systems.";
CM_ SG_ 304 IMULatAccPrim "Inertial Measurement Unit Lateral Acceleration Primary";
CM_ BO_ 197 "Application Is Tx ing this frame at the rate of 10 ms";
CM_ BO_ 485 "6443-Power Steering Indication On in this frame not used by GlobalA /JD";
CM_ BO_ 192 "Application Is Tx ing this frame at the rate of 10 ms";
CM_ BO_ 193 "Application Is Tx ing this frame at the rate of 10 ms";
BA_DEF_ SG_  "VNSigSLHSSharedDiagnostic" ENUM  "No","Yes";
BA_DEF_ SG_  "SignalType" STRING ;
BA_DEF_ SG_  "PacketOrder" INT 0 65535;
BA_DEF_ SG_  "SignalLongName" STRING ;
BA_DEF_ SG_  "GenSigStartValue" INT 0 65535;
BA_DEF_ SG_  "VNSigAllNodes" ENUM  "No","Yes";
BA_DEF_ SG_  "GenSigSendType" ENUM  "not used","not used","not used","not used","not used","not used","not used","NoSigSendType","not used","not used","OnAnyChange","OnChangeIfActive","OnDelta";
BA_DEF_ SG_  "GenSigSendOnInit" ENUM  "Not Initialized","Application","Handler";
BA_DEF_ BO_  "AppGenMsgCycleTime" INT 0 0;
BA_DEF_ BO_  "GenMsgILSupport" ENUM  "No","Yes";
BA_DEF_ BO_  "TpApplType" STRING ;
BA_DEF_ BO_  "Prio" INT 0 7;
BA_DEF_ BO_  "MessageSubnet" ENUM  "LS","HS","CE","PE","HV","FO","LE","HE2","PHS","PCE","DLCLS","DLCHS","DLCCE","DLCFO";
BA_DEF_ BO_  "GenMsgMandatoryToSupervision" ENUM  "No","Yes";
BA_DEF_ BO_  "DiagState" ENUM  "No","Yes";
BA_DEF_ BO_  "GenMsgDelayTime" INT 0 100000;
BA_DEF_ BO_  "GenMsgCycleTime" INT 0 100000;
BA_DEF_ BO_  "GenMsgSendType" ENUM  "cyclicX","spontanX","cyclicIfActiveX","spontanWithDelay","cyclicAndSpontanX","cyclicAndSpontanWithDelay","spontanWithRepitition","cyclicIfActiveAndSpontanWD";
BA_DEF_ BO_  "DiagResponse" ENUM  "No","Yes";
BA_DEF_ BO_  "DiagRequest" ENUM  "No","Yes";
BA_DEF_ BO_  "NmMessage" ENUM  "No","Yes";
BA_DEF_REL_ BU_SG_REL_  "GenSigSuprvRespComment" STRING ;
BA_DEF_REL_ BU_SG_REL_  "GenSigVBitResp" ENUM  "No","Yes";
BA_DEF_REL_ BU_SG_REL_  "GenSigVBitRespComment" STRING ;
BA_DEF_REL_ BU_SG_REL_  "GenSigVDAFailComment" STRING ;
BA_DEF_REL_ BU_SG_REL_  "GenSigVDAFailResp" ENUM  "No","Yes";
BA_DEF_REL_ BU_SG_REL_  "GenSigRxStartValue" STRING ;
BA_DEF_REL_ BU_SG_REL_  "GenSigSuprvResp" ENUM  "None","Notify App","Substitute Default";
BA_DEF_REL_ BU_SG_REL_  "GenSigTimeoutMsg" HEX 0 268435455;
BA_DEF_REL_ BU_SG_REL_  "GenSigTimeoutTime" INT 0 15000;
BA_DEF_DEF_  "VNSigSLHSSharedDiagnostic" "No";
BA_DEF_DEF_  "SignalType" "";
BA_DEF_DEF_  "PacketOrder" 0;
BA_DEF_DEF_  "SignalLongName" "";
BA_DEF_DEF_  "GenSigStartValue" 0;
BA_DEF_DEF_  "VNSigAllNodes" "No";
BA_DEF_DEF_  "GenSigSendType" "NoSigSendType";
BA_DEF_DEF_  "GenSigSendOnInit" "Not Initialized";
BA_DEF_DEF_  "AppGenMsgCycleTime" 0;
BA_DEF_DEF_  "GenMsgILSupport" "Yes";
BA_DEF_DEF_  "TpApplType" "";
BA_DEF_DEF_  "Prio" 4;
BA_DEF_DEF_  "MessageSubnet" "LS";
BA_DEF_DEF_  "GenMsgMandatoryToSupervision" "No";
BA_DEF_DEF_  "DiagState" "No";
BA_DEF_DEF_  "GenMsgDelayTime" 0;
BA_DEF_DEF_  "GenMsgCycleTime" 0;
BA_DEF_DEF_  "GenMsgSendType" "spontanX";
BA_DEF_DEF_  "DiagResponse" "No";
BA_DEF_DEF_  "DiagRequest" "No";
BA_DEF_DEF_  "NmMessage" "No";
BA_DEF_DEF_REL_ "GenSigSuprvRespComment" "";
BA_DEF_DEF_REL_ "GenSigVBitResp" "No";
BA_DEF_DEF_REL_ "GenSigVBitRespComment" "";
BA_DEF_DEF_REL_ "GenSigVDAFailComment" "";
BA_DEF_DEF_REL_ "GenSigVDAFailResp" "No";
BA_DEF_DEF_REL_ "GenSigRxStartValue" "";
BA_DEF_DEF_REL_ "GenSigSuprvResp" "None";
BA_DEF_DEF_REL_ "GenSigTimeoutMsg" 0;
BA_DEF_DEF_REL_ "GenSigTimeoutTime" 0;
BA_ "Prio" BO_ 339 0;
BA_ "MessageSubnet" BO_ 339 9;
BA_ "GenMsgCycleTime" BO_ 339 10;
BA_ "GenMsgSendType" BO_ 339 0;
BA_ "Prio" BO_ 201 0;
BA_ "MessageSubnet" BO_ 201 9;
BA_ "GenMsgCycleTime" BO_ 201 12;
BA_ "GenMsgSendType" BO_ 201 0;
BA_ "Prio" BO_ 381 0;
BA_ "MessageSubnet" BO_ 381 9;
BA_ "GenMsgCycleTime" BO_ 381 100;
BA_ "GenMsgSendType" BO_ 381 0;
BA_ "Prio" BO_ 530 0;
BA_ "MessageSubnet" BO_ 530 9;
BA_ "GenMsgCycleTime" BO_ 530 25;
BA_ "GenMsgSendType" BO_ 530 0;
BA_ "Prio" BO_ 560 0;
BA_ "MessageSubnet" BO_ 560 9;
BA_ "GenMsgCycleTime" BO_ 560 12;
BA_ "GenMsgSendType" BO_ 560 0;
BA_ "Prio" BO_ 603 0;
BA_ "MessageSubnet" BO_ 603 9;
BA_ "DiagRequest" BO_ 603 1;
BA_ "Prio" BO_ 565 0;
BA_ "MessageSubnet" BO_ 565 9;
BA_ "GenMsgCycleTime" BO_ 565 10;
BA_ "GenMsgSendType" BO_ 565 0;
BA_ "GenMsgILSupport" BO_ 1347 0;
BA_ "TpApplType" BO_ 1347 "DiagUUDTResponse";
BA_ "Prio" BO_ 1347 0;
BA_ "MessageSubnet" BO_ 1347 9;
BA_ "Prio" BO_ 832 0;
BA_ "MessageSubnet" BO_ 832 9;
BA_ "GenMsgCycleTime" BO_ 832 100;
BA_ "GenMsgSendType" BO_ 832 0;
BA_ "Prio" BO_ 1622 0;
BA_ "MessageSubnet" BO_ 1622 9;
BA_ "DiagResponse" BO_ 1622 1;
BA_ "GenMsgILSupport" BO_ 1351 0;
BA_ "TpApplType" BO_ 1351 "DiagUUDTResponse";
BA_ "Prio" BO_ 1351 0;
BA_ "MessageSubnet" BO_ 1351 9;
BA_ "GenMsgILSupport" BO_ 1346 0;
BA_ "TpApplType" BO_ 1346 "DiagUUDTResponse";
BA_ "Prio" BO_ 1346 0;
BA_ "MessageSubnet" BO_ 1346 9;
BA_ "GenMsgILSupport" BO_ 1607 0;
BA_ "Prio" BO_ 1607 0;
BA_ "MessageSubnet" BO_ 1607 9;
BA_ "DiagResponse" BO_ 1607 1;
BA_ "Prio" BO_ 1602 0;
BA_ "MessageSubnet" BO_ 1602 9;
BA_ "DiagResponse" BO_ 1602 1;
BA_ "Prio" BO_ 273 0;
BA_ "MessageSubnet" BO_ 273 9;
BA_ "GenMsgCycleTime" BO_ 273 10;
BA_ "GenMsgSendType" BO_ 273 0;
BA_ "Prio" BO_ 598 0;
BA_ "MessageSubnet" BO_ 598 9;
BA_ "DiagRequest" BO_ 598 1;
BA_ "GenMsgILSupport" BO_ 1352 0;
BA_ "TpApplType" BO_ 1352 "DiagUUDTResponse";
BA_ "Prio" BO_ 1352 0;
BA_ "MessageSubnet" BO_ 1352 9;
BA_ "Prio" BO_ 578 0;
BA_ "MessageSubnet" BO_ 578 9;
BA_ "DiagRequest" BO_ 578 1;
BA_ "Prio" BO_ 579 0;
BA_ "MessageSubnet" BO_ 579 9;
BA_ "DiagRequest" BO_ 579 1;
BA_ "GenMsgILSupport" BO_ 1364 0;
BA_ "TpApplType" BO_ 1364 "DiagUUDTResponse";
BA_ "Prio" BO_ 1364 0;
BA_ "MessageSubnet" BO_ 1364 9;
BA_ "GenMsgILSupport" BO_ 1355 0;
BA_ "TpApplType" BO_ 1355 "DiagUUDTResponse";
BA_ "Prio" BO_ 1355 0;
BA_ "MessageSubnet" BO_ 1355 9;
BA_ "Prio" BO_ 508 0;
BA_ "MessageSubnet" BO_ 508 9;
BA_ "GenMsgCycleTime" BO_ 508 50;
BA_ "GenMsgSendType" BO_ 508 0;
BA_ "Prio" BO_ 1603 0;
BA_ "MessageSubnet" BO_ 1603 9;
BA_ "DiagResponse" BO_ 1603 1;
BA_ "Prio" BO_ 272 0;
BA_ "MessageSubnet" BO_ 272 9;
BA_ "GenMsgCycleTime" BO_ 272 10;
BA_ "GenMsgSendType" BO_ 272 0;
BA_ "GenMsgILSupport" BO_ 583 0;
BA_ "Prio" BO_ 583 0;
BA_ "MessageSubnet" BO_ 583 9;
BA_ "DiagRequest" BO_ 583 1;
BA_ "Prio" BO_ 320 0;
BA_ "MessageSubnet" BO_ 320 9;
BA_ "GenMsgCycleTime" BO_ 320 10;
BA_ "GenMsgSendType" BO_ 320 0;
BA_ "Prio" BO_ 304 0;
BA_ "MessageSubnet" BO_ 304 9;
BA_ "GenMsgCycleTime" BO_ 304 10;
BA_ "GenMsgSendType" BO_ 304 0;
BA_ "Prio" BO_ 840 0;
BA_ "MessageSubnet" BO_ 840 9;
BA_ "GenMsgCycleTime" BO_ 840 50;
BA_ "GenMsgSendType" BO_ 840 0;
BA_ "Prio" BO_ 842 0;
BA_ "MessageSubnet" BO_ 842 9;
BA_ "GenMsgCycleTime" BO_ 842 50;
BA_ "GenMsgSendType" BO_ 842 0;
BA_ "Prio" BO_ 1001 0;
BA_ "MessageSubnet" BO_ 1001 9;
BA_ "GenMsgCycleTime" BO_ 1001 100;
BA_ "GenMsgSendType" BO_ 1001 0;
BA_ "Prio" BO_ 1608 0;
BA_ "MessageSubnet" BO_ 1608 9;
BA_ "DiagResponse" BO_ 1608 1;
BA_ "AppGenMsgCycleTime" BO_ 197 10;
BA_ "Prio" BO_ 197 0;
BA_ "MessageSubnet" BO_ 197 9;
BA_ "Prio" BO_ 289 0;
BA_ "MessageSubnet" BO_ 289 9;
BA_ "GenMsgCycleTime" BO_ 289 100;
BA_ "GenMsgSendType" BO_ 289 0;
BA_ "Prio" BO_ 290 0;
BA_ "MessageSubnet" BO_ 290 9;
BA_ "GenMsgMandatoryToSupervision" BO_ 290 1;
BA_ "GenMsgCycleTime" BO_ 290 100;
BA_ "GenMsgSendType" BO_ 290 0;
BA_ "GenMsgILSupport" BO_ 1371 0;
BA_ "TpApplType" BO_ 1371 "DiagUUDTResponse";
BA_ "Prio" BO_ 1371 0;
BA_ "MessageSubnet" BO_ 1371 9;
BA_ "Prio" BO_ 485 0;
BA_ "MessageSubnet" BO_ 485 9;
BA_ "GenMsgCycleTime" BO_ 485 10;
BA_ "GenMsgSendType" BO_ 485 0;
BA_ "AppGenMsgCycleTime" BO_ 192 10;
BA_ "Prio" BO_ 192 0;
BA_ "MessageSubnet" BO_ 192 9;
BA_ "AppGenMsgCycleTime" BO_ 193 10;
BA_ "Prio" BO_ 193 0;
BA_ "MessageSubnet" BO_ 193 9;
BA_ "GenMsgILSupport" BO_ 257 0;
BA_ "Prio" BO_ 257 0;
BA_ "MessageSubnet" BO_ 257 9;
BA_ "DiagState" BO_ 257 1;
BA_ "GenMsgILSupport" BO_ 1367 0;
BA_ "TpApplType" BO_ 1367 "DiagUUDTResponse";
BA_ "Prio" BO_ 1367 0;
BA_ "MessageSubnet" BO_ 1367 9;
BA_ "Prio" BO_ 599 0;
BA_ "MessageSubnet" BO_ 599 9;
BA_ "DiagRequest" BO_ 599 1;
BA_ "SignalType" SG_ 339 CoPRVBAtvRed "BLN";
BA_ "SignalLongName" SG_ 339 CoPRVBAtvRed "CoPilot Rear Virtual Bumper Active Redundant";
BA_ "VNSigAllNodes" SG_ 339 CoPRVBAtvRed 1;
BA_ "SignalType" SG_ 339 CoPCIBAtvRed "BLN";
BA_ "SignalLongName" SG_ 339 CoPCIBAtvRed "CoPilot Collision Imminent Braking Active Redundant";
BA_ "VNSigAllNodes" SG_ 339 CoPCIBAtvRed 1;
BA_ "SignalType" SG_ 339 CPEPSWARR_TrgtAng "SNM";
BA_ "SignalLongName" SG_ 339 CPEPSWARR_TrgtAng "CoPilot Electric Power Steering Wheel Angle Request Redundant: Target Angle";
BA_ "VNSigAllNodes" SG_ 339 CPEPSWARR_TrgtAng 1;
BA_ "SignalType" SG_ 339 CPEPSWARR_ReqdState "ENM";
BA_ "SignalLongName" SG_ 339 CPEPSWARR_ReqdState "CoPilot Electric Power Steering Wheel Angle Request Redundant: Requested State";
BA_ "VNSigAllNodes" SG_ 339 CPEPSWARR_ReqdState 1;
BA_ "SignalType" SG_ 339 CoPEPBReqRed "ENM";
BA_ "SignalLongName" SG_ 339 CoPEPBReqRed "CoPilot Electric Park Brake Request Redundant";
BA_ "VNSigAllNodes" SG_ 339 CoPEPBReqRed 1;
BA_ "SignalType" SG_ 339 CoPBaSRedChksm "UNM";
BA_ "SignalLongName" SG_ 339 CoPBaSRedChksm "CoPilot Brake and Steering Redundant Checksum";
BA_ "VNSigAllNodes" SG_ 339 CoPBaSRedChksm 1;
BA_ "SignalType" SG_ 339 CoPBaSRedARC "UNM";
BA_ "SignalLongName" SG_ 339 CoPBaSRedARC "CoPilot Brake and Steering Redundant Alive Rolling Count";
BA_ "VNSigAllNodes" SG_ 339 CoPBaSRedARC 1;
BA_ "SignalType" SG_ 339 CoPCntrlFailRed "BLN";
BA_ "SignalLongName" SG_ 339 CoPCntrlFailRed "CoPilot Controller Failure Redundant";
BA_ "VNSigAllNodes" SG_ 339 CoPCntrlFailRed 1;
BA_ "SignalType" SG_ 339 CoPAutoBrkTrqReqRed "UNM";
BA_ "SignalLongName" SG_ 339 CoPAutoBrkTrqReqRed "CoPilot Autonomous Brake Torque Request Redundant";
BA_ "GenSigStartValue" SG_ 339 CoPAutoBrkTrqReqRed 32767;
BA_ "VNSigAllNodes" SG_ 339 CoPAutoBrkTrqReqRed 1;
BA_ "SignalType" SG_ 339 CoPAutoBrkReqTypeRed "ENM";
BA_ "SignalLongName" SG_ 339 CoPAutoBrkReqTypeRed "CoPilot Autonomous Brake Request Type Redundant";
BA_ "VNSigAllNodes" SG_ 339 CoPAutoBrkReqTypeRed 1;
BA_ "SignalType" SG_ 201 EngTrqActExtRngV "ENM";
BA_ "SignalLongName" SG_ 201 EngTrqActExtRngV "Engine Torque Actual Extended Range Validity";
BA_ "VNSigAllNodes" SG_ 201 EngTrqActExtRngV 1;
BA_ "SignalType" SG_ 201 EngTrqActExtRng "UNM";
BA_ "SignalLongName" SG_ 201 EngTrqActExtRng "Engine Torque Actual Extended Range";
BA_ "GenSigStartValue" SG_ 201 EngTrqActExtRng 1696;
BA_ "VNSigAllNodes" SG_ 201 EngTrqActExtRng 1;
BA_ "SignalType" SG_ 201 EngRunAtv "BLN";
BA_ "SignalLongName" SG_ 201 EngRunAtv "Engine Run Active";
BA_ "VNSigAllNodes" SG_ 201 EngRunAtv 1;
BA_ "SignalType" SG_ 201 EngOffTmExtRngV "ENM";
BA_ "SignalLongName" SG_ 201 EngOffTmExtRngV "Engine Off Time Extended Range Validity";
BA_ "VNSigAllNodes" SG_ 201 EngOffTmExtRngV 1;
BA_ "SignalType" SG_ 201 EngOffTmExtRng "UNM";
BA_ "SignalLongName" SG_ 201 EngOffTmExtRng "Engine Off Time Extended Range";
BA_ "VNSigAllNodes" SG_ 201 EngOffTmExtRng 1;
BA_ "SignalType" SG_ 201 EngVDA "ENM";
BA_ "SignalLongName" SG_ 201 EngVDA "Engine Virtual Device Availability";
BA_ "GenSigStartValue" SG_ 201 EngVDA 1;
BA_ "VNSigAllNodes" SG_ 201 EngVDA 1;
BA_ "SignalType" SG_ 201 PT_CrnkAct "BLN";
BA_ "SignalLongName" SG_ 201 PT_CrnkAct "Powertrain Crank Active";
BA_ "VNSigAllNodes" SG_ 201 PT_CrnkAct 1;
BA_ "SignalType" SG_ 201 Eng12vStrtrMtrCmmdOn "BLN";
BA_ "SignalLongName" SG_ 201 Eng12vStrtrMtrCmmdOn "Engine 12 Volt Starter Motor Commanded On";
BA_ "VNSigAllNodes" SG_ 201 Eng12vStrtrMtrCmmdOn 1;
BA_ "SignalType" SG_ 201 EngSpdStat "ENM";
BA_ "SignalLongName" SG_ 201 EngSpdStat "Engine Speed Status";
BA_ "VNSigAllNodes" SG_ 201 EngSpdStat 1;
BA_ "SignalType" SG_ 201 EngSpd "UNM";
BA_ "SignalLongName" SG_ 201 EngSpd "Engine Speed";
BA_ "VNSigAllNodes" SG_ 201 EngSpd 1;
BA_ "SignalType" SG_ 201 EngRunng "BLN";
BA_ "SignalLongName" SG_ 201 EngRunng "Engine Running";
BA_ "VNSigAllNodes" SG_ 201 EngRunng 1;
BA_ "SignalType" SG_ 201 EngOffTmVDA "ENM";
BA_ "SignalLongName" SG_ 201 EngOffTmVDA "Engine Off Time Virtual Device Availability";
BA_ "GenSigStartValue" SG_ 201 EngOffTmVDA 1;
BA_ "VNSigAllNodes" SG_ 201 EngOffTmVDA 1;
BA_ "SignalType" SG_ 381 AutBrkReqStat2ProtVal "UNM";
BA_ "SignalLongName" SG_ 381 AutBrkReqStat2ProtVal "Autonomous Braking Request Status 2 Protection Value";
BA_ "VNSigAllNodes" SG_ 381 AutBrkReqStat2ProtVal 1;
BA_ "SignalType" SG_ 381 AutBrkReqStat2ARC "UNM";
BA_ "SignalLongName" SG_ 381 AutBrkReqStat2ARC "Autonomous Braking Request Status 2 Alive Rolling Count";
BA_ "VNSigAllNodes" SG_ 381 AutBrkReqStat2ARC 1;
BA_ "PacketOrder" SG_ 381 ABRS2_BcupESCDatInpSt 3;
BA_ "SignalType" SG_ 381 ABRS2_BcupESCDatInpSt "ENM";
BA_ "SignalLongName" SG_ 381 ABRS2_BcupESCDatInpSt "Autonomous Braking Request Status 2 : Backup ESC Data Input Status";
BA_ "VNSigAllNodes" SG_ 381 ABRS2_BcupESCDatInpSt 1;
BA_ "PacketOrder" SG_ 381 ABRS2_ACCAutBkRqPrBsSt 2;
BA_ "SignalType" SG_ 381 ABRS2_ACCAutBkRqPrBsSt "ENM";
BA_ "SignalLongName" SG_ 381 ABRS2_ACCAutBkRqPrBsSt "Autonomous Braking Request Status 2 : ACC Autonomous Braking Request Primary Bus Status";
BA_ "VNSigAllNodes" SG_ 381 ABRS2_ACCAutBkRqPrBsSt 1;
BA_ "PacketOrder" SG_ 381 ABRS2_SAAYawMtReqScBsSt 1;
BA_ "SignalType" SG_ 381 ABRS2_SAAYawMtReqScBsSt "ENM";
BA_ "SignalLongName" SG_ 381 ABRS2_SAAYawMtReqScBsSt "Autonomous Braking Request Status 2 : Steering Angle Assist Yaw Movement Request Secondary Bus Status";
BA_ "VNSigAllNodes" SG_ 381 ABRS2_SAAYawMtReqScBsSt 1;
BA_ "SignalType" SG_ 381 StrAngSnsPolRat "ENM";
BA_ "SignalLongName" SG_ 381 StrAngSnsPolRat "Steering Angle Sensor Polarity Rationality";
BA_ "VNSigAllNodes" SG_ 381 StrAngSnsPolRat 1;
BA_ "SignalType" SG_ 381 ActVehAccelV "ENM";
BA_ "SignalLongName" SG_ 381 ActVehAccelV "Actual Vehicle Acceleration Validity";
BA_ "VNSigAllNodes" SG_ 381 ActVehAccelV 1;
BA_ "SignalType" SG_ 381 ActVehAccel "SNM";
BA_ "SignalLongName" SG_ 381 ActVehAccel "Actual Vehicle Acceleration";
BA_ "VNSigAllNodes" SG_ 381 ActVehAccel 1;
BA_ "SignalType" SG_ 381 LatAccSnsPolRat "ENM";
BA_ "SignalLongName" SG_ 381 LatAccSnsPolRat "Lateral Acceleration Sensor Polarity Rationality";
BA_ "VNSigAllNodes" SG_ 381 LatAccSnsPolRat 1;
BA_ "SignalType" SG_ 530 ABSFld "BLN";
BA_ "SignalLongName" SG_ 530 ABSFld "Antilock Brake System Failed";
BA_ "VNSigAllNodes" SG_ 530 ABSFld 1;
BA_ "SignalType" SG_ 530 BrkPdDrvAPrsStaPVal "UNM";
BA_ "SignalLongName" SG_ 530 BrkPdDrvAPrsStaPVal "Brake Pedal Driver Applied Pressure Status Protection Value";
BA_ "VNSigAllNodes" SG_ 530 BrkPdDrvAPrsStaPVal 1;
BA_ "SignalType" SG_ 530 BPDAPS_BkPDrvApPV "ENM";
BA_ "PacketOrder" SG_ 530 BPDAPS_BkPDrvApPV 2;
BA_ "SignalLongName" SG_ 530 BPDAPS_BkPDrvApPV "Brake Pedal Driver Applied Pressure Status : Brake Pedal Driver Applied Pressure Validity";
BA_ "VNSigAllNodes" SG_ 530 BPDAPS_BkPDrvApPV 1;
BA_ "SignalType" SG_ 530 BPDAPS_BkPDrvApP "UNM";
BA_ "PacketOrder" SG_ 530 BPDAPS_BkPDrvApP 1;
BA_ "SignalLongName" SG_ 530 BPDAPS_BkPDrvApP "Brake Pedal Driver Applied Pressure Status : Brake Pedal Driver Applied Pressure";
BA_ "VNSigAllNodes" SG_ 530 BPDAPS_BkPDrvApP 1;
BA_ "SignalType" SG_ 530 BrkPdDrvAppPrsAlRC "UNM";
BA_ "SignalLongName" SG_ 530 BrkPdDrvAppPrsAlRC "Brake Pedal Driver Applied Pressure Alive Rolling Count";
BA_ "VNSigAllNodes" SG_ 530 BrkPdDrvAppPrsAlRC 1;
BA_ "SignalType" SG_ 530 ABSAtv "BLN";
BA_ "SignalLongName" SG_ 530 ABSAtv "Antilock Brake System Active";
BA_ "VNSigAllNodes" SG_ 530 ABSAtv 1;
BA_ "SignalType" SG_ 530 BrkPdlPosGrad "SNM";
BA_ "SignalLongName" SG_ 530 BrkPdlPosGrad "Brake Pedal Position Gradient";
BA_ "VNSigAllNodes" SG_ 530 BrkPdlPosGrad 1;
BA_ "SignalType" SG_ 530 BrkPdlPos "UNM";
BA_ "SignalLongName" SG_ 530 BrkPdlPos "Brake Pedal Position";
BA_ "VNSigAllNodes" SG_ 530 BrkPdlPos 1;
BA_ "SignalType" SG_ 530 NotEventStat "ENM";
BA_ "SignalLongName" SG_ 530 NotEventStat "Notification Event Status";
BA_ "VNSigAllNodes" SG_ 530 NotEventStat 1;
BA_ "SignalType" SG_ 530 BrkPedPosAlvRolngCnt "UNM";
BA_ "SignalLongName" SG_ 530 BrkPedPosAlvRolngCnt "Brake Pedal Position Alive Rolling Count";
BA_ "VNSigAllNodes" SG_ 530 BrkPedPosAlvRolngCnt 1;
BA_ "SignalType" SG_ 530 WhlRotStatTmstmpRes "UNM";
BA_ "SignalLongName" SG_ 530 WhlRotStatTmstmpRes "Wheel Rotational Status Timestamp Resolution";
BA_ "VNSigAllNodes" SG_ 530 WhlRotStatTmstmpRes 1;
BA_ "SignalType" SG_ 530 BrkAppSnsrHmPosLrnd "BLN";
BA_ "SignalLongName" SG_ 530 BrkAppSnsrHmPosLrnd "Brake Apply Sensor Home Position Learned";
BA_ "VNSigAllNodes" SG_ 530 BrkAppSnsrHmPosLrnd 1;
BA_ "SignalType" SG_ 530 BrkPdlModTrvlV "ENM";
BA_ "SignalLongName" SG_ 530 BrkPdlModTrvlV "Brake Pedal Moderate Travel Achieved Validity";
BA_ "VNSigAllNodes" SG_ 530 BrkPdlModTrvlV 1;
BA_ "SignalType" SG_ 530 BrkPdlModTrvl "BLN";
BA_ "SignalLongName" SG_ 530 BrkPdlModTrvl "Brake Pedal Moderate Travel Achieved";
BA_ "VNSigAllNodes" SG_ 530 BrkPdlModTrvl 1;
BA_ "SignalType" SG_ 530 PrplsnSysAtv "BLN";
BA_ "SignalLongName" SG_ 530 PrplsnSysAtv "Propulsion System Active";
BA_ "VNSigAllNodes" SG_ 530 PrplsnSysAtv 1;
BA_ "SignalType" SG_ 560 RegenBrkAxTqAchPVal "UNM";
BA_ "SignalLongName" SG_ 560 RegenBrkAxTqAchPVal "Regenerative Braking Axle Torque Achieved Protection Value";
BA_ "VNSigAllNodes" SG_ 560 RegenBrkAxTqAchPVal 1;
BA_ "SignalType" SG_ 560 RegenBrkAxTqAchARC "UNM";
BA_ "SignalLongName" SG_ 560 RegenBrkAxTqAchARC "Regenerative Braking Axle Torque Achieved Alive Rolling Count";
BA_ "VNSigAllNodes" SG_ 560 RegenBrkAxTqAchARC 1;
BA_ "SignalType" SG_ 560 RegenBrkAxTrqAch "UNM";
BA_ "SignalLongName" SG_ 560 RegenBrkAxTrqAch "Regenerative Braking Axle Torque Achieved";
BA_ "VNSigAllNodes" SG_ 560 RegenBrkAxTrqAch 1;
BA_ "SignalType" SG_ 560 RegenBrkAxTorqCap "UNM";
BA_ "SignalLongName" SG_ 560 RegenBrkAxTorqCap "Regenerative Braking Axle Torque Capability";
BA_ "VNSigAllNodes" SG_ 560 RegenBrkAxTorqCap 1;
BA_ "VNSigSLHSSharedDiagnostic" SG_ 603 DgnInf 1;
BA_ "SignalType" SG_ 603 DgnInf "UNM";
BA_ "SignalLongName" SG_ 603 DgnInf "Diagnostic Information";
BA_ "VNSigAllNodes" SG_ 603 DgnInf 1;
BA_ "SignalType" SG_ 565 BrkPdlDrvApplPresV "ENM";
BA_ "SignalLongName" SG_ 565 BrkPdlDrvApplPresV "Brake Pedal Driver Applied Pressure Validity";
BA_ "VNSigAllNodes" SG_ 565 BrkPdlDrvApplPresV 1;
BA_ "SignalType" SG_ 565 ChsSysTrnsShfBhvRq "ENM";
BA_ "SignalLongName" SG_ 565 ChsSysTrnsShfBhvRq "Chassis System Transmission Shift Behavior Request";
BA_ "VNSigAllNodes" SG_ 565 ChsSysTrnsShfBhvRq 1;
BA_ "SignalType" SG_ 565 BrkPdlDrvApplPres "UNM";
BA_ "SignalLongName" SG_ 565 BrkPdlDrvApplPres "Brake Pedal Driver Applied Pressure";
BA_ "VNSigAllNodes" SG_ 565 BrkPdlDrvApplPres 1;
BA_ "SignalType" SG_ 565 RegenBrkAxTrqRqPVal "UNM";
BA_ "SignalLongName" SG_ 565 RegenBrkAxTrqRqPVal "Regenerative Braking Axle Torque Request Protection Value";
BA_ "VNSigAllNodes" SG_ 565 RegenBrkAxTrqRqPVal 1;
BA_ "SignalType" SG_ 565 RegenBrkAxTrqRqARC "UNM";
BA_ "SignalLongName" SG_ 565 RegenBrkAxTrqRqARC "Regenerative Braking Axle Torque Request Alive Rolling Count";
BA_ "VNSigAllNodes" SG_ 565 RegenBrkAxTrqRqARC 1;
BA_ "SignalType" SG_ 565 RegenBrkAxTorqRqst "UNM";
BA_ "SignalLongName" SG_ 565 RegenBrkAxTorqRqst "Regenerative Braking Axle Torque Request";
BA_ "VNSigAllNodes" SG_ 565 RegenBrkAxTorqRqst 1;
BA_ "VNSigSLHSSharedDiagnostic" SG_ 1347 DgnInf_CE543 1;
BA_ "SignalType" SG_ 1347 DgnInf_CE543 "UNM";
BA_ "SignalLongName" SG_ 1347 DgnInf_CE543 "Diagnostic Information CE543";
BA_ "VNSigAllNodes" SG_ 1347 DgnInf_CE543 1;
BA_ "SignalType" SG_ 832 HSInfoChksm "UNM";
BA_ "SignalLongName" SG_ 832 HSInfoChksm "High Speed Information Checksum";
BA_ "VNSigAllNodes" SG_ 832 HSInfoChksm 1;
BA_ "SignalType" SG_ 832 HSInfoARC "UNM";
BA_ "SignalLongName" SG_ 832 HSInfoARC "High Speed Information Alive Rolling Count";
BA_ "VNSigAllNodes" SG_ 832 HSInfoARC 1;
BA_ "SignalType" SG_ 832 BrkPedTrvlAchvd "BLN";
BA_ "PacketOrder" SG_ 832 BrkPedTrvlAchvd 1;
BA_ "SignalLongName" SG_ 832 BrkPedTrvlAchvd "Brake Pedal Initial Travel Achieved Status : Brake Pedal Initial Travel Achieved";
BA_ "VNSigAllNodes" SG_ 832 BrkPedTrvlAchvd 1;
BA_ "SignalType" SG_ 832 BrkPedTrvlAchvdV "ENM";
BA_ "PacketOrder" SG_ 832 BrkPedTrvlAchvdV 2;
BA_ "SignalLongName" SG_ 832 BrkPedTrvlAchvdV "Brake Pedal Initial Travel Achieved Status : Brake Pedal Initial Travel Achieved Validity";
BA_ "VNSigAllNodes" SG_ 832 BrkPedTrvlAchvdV 1;
BA_ "SignalType" SG_ 832 BrkPdlInTrvPrt "UNM";
BA_ "SignalLongName" SG_ 832 BrkPdlInTrvPrt "Brake Pedal Initial Travel Achieved Protection";
BA_ "VNSigAllNodes" SG_ 832 BrkPdlInTrvPrt 1;
BA_ "SignalType" SG_ 832 AccActPosV "ENM";
BA_ "SignalLongName" SG_ 832 AccActPosV "Accelerator Actual Position Validity";
BA_ "VNSigAllNodes" SG_ 832 AccActPosV 1;
BA_ "SignalType" SG_ 832 AccActPos "UNM";
BA_ "SignalLongName" SG_ 832 AccActPos "Accelerator Actual Position";
BA_ "VNSigAllNodes" SG_ 832 AccActPos 1;
BA_ "SignalType" SG_ 832 WhlDistPrRevNDrvn "UNM";
BA_ "SignalLongName" SG_ 832 WhlDistPrRevNDrvn "Wheel Distance Per Revolution Non Driven";
BA_ "VNSigAllNodes" SG_ 832 WhlDistPrRevNDrvn 1;
BA_ "SignalType" SG_ 832 WhlDistPrRevDrvn "UNM";
BA_ "SignalLongName" SG_ 832 WhlDistPrRevDrvn "Wheel Distance Per Revolution Driven";
BA_ "VNSigAllNodes" SG_ 832 WhlDistPrRevDrvn 1;
BA_ "VNSigSLHSSharedDiagnostic" SG_ 1622 DgnInf 1;
BA_ "SignalType" SG_ 1622 DgnInf "UNM";
BA_ "SignalLongName" SG_ 1622 DgnInf "Diagnostic Information";
BA_ "VNSigAllNodes" SG_ 1622 DgnInf 1;
BA_ "VNSigSLHSSharedDiagnostic" SG_ 1351 DgnInf_CE547 1;
BA_ "SignalType" SG_ 1351 DgnInf_CE547 "UNM";
BA_ "SignalLongName" SG_ 1351 DgnInf_CE547 "Diagnostic Information CE547";
BA_ "VNSigAllNodes" SG_ 1351 DgnInf_CE547 1;
BA_ "VNSigSLHSSharedDiagnostic" SG_ 1346 DgnInf_CE542 1;
BA_ "SignalType" SG_ 1346 DgnInf_CE542 "UNM";
BA_ "SignalLongName" SG_ 1346 DgnInf_CE542 "Diagnostic Information CE542";
BA_ "VNSigAllNodes" SG_ 1346 DgnInf_CE542 1;
BA_ "VNSigSLHSSharedDiagnostic" SG_ 1607 DgnInf 1;
BA_ "SignalType" SG_ 1607 DgnInf "UNM";
BA_ "SignalLongName" SG_ 1607 DgnInf "Diagnostic Information";
BA_ "VNSigAllNodes" SG_ 1607 DgnInf 1;
BA_ "VNSigSLHSSharedDiagnostic" SG_ 1602 DgnInf 1;
BA_ "SignalType" SG_ 1602 DgnInf "UNM";
BA_ "SignalLongName" SG_ 1602 DgnInf "Diagnostic Information";
BA_ "VNSigAllNodes" SG_ 1602 DgnInf 1;
BA_ "SignalType" SG_ 273 DgWhlBrkActvIntfTyp "ENM";
BA_ "SignalLongName" SG_ 273 DgWhlBrkActvIntfTyp "Diagnostic Wheel Brake Active Interface Type";
BA_ "VNSigAllNodes" SG_ 273 DgWhlBrkActvIntfTyp 1;
BA_ "SignalType" SG_ 273 DiagWhlBrkPrsReqRR "UNM";
BA_ "SignalLongName" SG_ 273 DiagWhlBrkPrsReqRR "Diagnostic Wheel Brake Pressure Request RR";
BA_ "VNSigAllNodes" SG_ 273 DiagWhlBrkPrsReqRR 1;
BA_ "SignalType" SG_ 273 DiagWhlBrkPrsReqRF "UNM";
BA_ "SignalLongName" SG_ 273 DiagWhlBrkPrsReqRF "Diagnostic Wheel Brake Pressure Request RF";
BA_ "VNSigAllNodes" SG_ 273 DiagWhlBrkPrsReqRF 1;
BA_ "SignalType" SG_ 273 DiagWhlBrkPrsReqLR "UNM";
BA_ "SignalLongName" SG_ 273 DiagWhlBrkPrsReqLR "Diagnostic Wheel Brake Pressure Request LR";
BA_ "VNSigAllNodes" SG_ 273 DiagWhlBrkPrsReqLR 1;
BA_ "SignalType" SG_ 273 DiagWhlBrkPrsReqLF "UNM";
BA_ "SignalLongName" SG_ 273 DiagWhlBrkPrsReqLF "Diagnostic Wheel Brake Pressure Request LF";
BA_ "VNSigAllNodes" SG_ 273 DiagWhlBrkPrsReqLF 1;
BA_ "SignalType" SG_ 273 DiagWhlBrkARC "UNM";
BA_ "SignalLongName" SG_ 273 DiagWhlBrkARC "Diagnostic Wheel Brake Alive Rolling Count";
BA_ "VNSigAllNodes" SG_ 273 DiagWhlBrkARC 1;
BA_ "SignalType" SG_ 273 DiagWhlBrkChksm "UNM";
BA_ "SignalLongName" SG_ 273 DiagWhlBrkChksm "Diagnostic Wheel Brake Checksum";
BA_ "VNSigAllNodes" SG_ 273 DiagWhlBrkChksm 1;
BA_ "VNSigSLHSSharedDiagnostic" SG_ 598 DgnInf 1;
BA_ "SignalType" SG_ 598 DgnInf "UNM";
BA_ "SignalLongName" SG_ 598 DgnInf "Diagnostic Information";
BA_ "VNSigAllNodes" SG_ 598 DgnInf 1;
BA_ "VNSigSLHSSharedDiagnostic" SG_ 1352 DgnInf_CE548 1;
BA_ "SignalType" SG_ 1352 DgnInf_CE548 "UNM";
BA_ "SignalLongName" SG_ 1352 DgnInf_CE548 "Diagnostic Information CE548";
BA_ "VNSigAllNodes" SG_ 1352 DgnInf_CE548 1;
BA_ "VNSigSLHSSharedDiagnostic" SG_ 578 DgnInf 1;
BA_ "SignalType" SG_ 578 DgnInf "UNM";
BA_ "SignalLongName" SG_ 578 DgnInf "Diagnostic Information";
BA_ "VNSigAllNodes" SG_ 578 DgnInf 1;
BA_ "VNSigSLHSSharedDiagnostic" SG_ 579 DgnInf 1;
BA_ "SignalType" SG_ 579 DgnInf "UNM";
BA_ "SignalLongName" SG_ 579 DgnInf "Diagnostic Information";
BA_ "VNSigAllNodes" SG_ 579 DgnInf 1;
BA_ "SignalType" SG_ 1364 DgnInf_CE554 "UNM";
BA_ "SignalLongName" SG_ 1364 DgnInf_CE554 "Diagnostic Information CE554";
BA_ "VNSigAllNodes" SG_ 1364 DgnInf_CE554 1;
BA_ "VNSigSLHSSharedDiagnostic" SG_ 1355 DgnInf_CE54B 1;
BA_ "SignalType" SG_ 1355 DgnInf_CE54B "UNM";
BA_ "SignalLongName" SG_ 1355 DgnInf_CE54B "Diagnostic Information CE54B";
BA_ "VNSigAllNodes" SG_ 1355 DgnInf_CE54B 1;
BA_ "SignalType" SG_ 508 LonLatAccSnsValARC "UNM";
BA_ "SignalLongName" SG_ 508 LonLatAccSnsValARC "Longitudinal/Lateral Acceleration Sensor Value Alive Rolling Count";
BA_ "VNSigAllNodes" SG_ 508 LonLatAccSnsValARC 1;
BA_ "SignalType" SG_ 508 LonLatAccSnsChk "UNM";
BA_ "SignalLongName" SG_ 508 LonLatAccSnsChk "Longitudinal/Lateral Acceleration Sensor Checksum";
BA_ "VNSigAllNodes" SG_ 508 LonLatAccSnsChk 1;
BA_ "SignalType" SG_ 508 LatAccSnsVal "SNM";
BA_ "SignalLongName" SG_ 508 LatAccSnsVal "Lateral Acceleration Sensor Value";
BA_ "VNSigAllNodes" SG_ 508 LatAccSnsVal 1;
BA_ "SignalType" SG_ 508 LonAccSnsVal "SNM";
BA_ "SignalLongName" SG_ 508 LonAccSnsVal "Longitudinal Acceleration Sensor Value";
BA_ "VNSigAllNodes" SG_ 508 LonAccSnsVal 1;
BA_ "VNSigSLHSSharedDiagnostic" SG_ 1603 DgnInf 1;
BA_ "SignalType" SG_ 1603 DgnInf "UNM";
BA_ "SignalLongName" SG_ 1603 DgnInf "Diagnostic Information";
BA_ "VNSigAllNodes" SG_ 1603 DgnInf 1;
BA_ "SignalType" SG_ 272 ADIMCntrlFailed "BLN";
BA_ "SignalLongName" SG_ 272 ADIMCntrlFailed "Autonomous Drive Interface Module Controller Failed";
BA_ "VNSigAllNodes" SG_ 272 ADIMCntrlFailed 1;
BA_ "SignalType" SG_ 272 ExtVehCtrlSts "ENM";
BA_ "SignalLongName" SG_ 272 ExtVehCtrlSts "External Vehicle Control Status";
BA_ "VNSigAllNodes" SG_ 272 ExtVehCtrlSts 1;
BA_ "SignalType" SG_ 272 VehMdMngrSt "ENM";
BA_ "SignalLongName" SG_ 272 VehMdMngrSt "Vehicle Mode Manager State";
BA_ "VNSigAllNodes" SG_ 272 VehMdMngrSt 1;
BA_ "SignalType" SG_ 272 EPSWhlAngReqTrgtAng "UNM";
BA_ "SignalLongName" SG_ 272 EPSWhlAngReqTrgtAng "Electric Power Steering Wheel Angle Request Target Angle";
BA_ "VNSigAllNodes" SG_ 272 EPSWhlAngReqTrgtAng 1;
BA_ "SignalType" SG_ 272 AutoEPBReq "ENM";
BA_ "SignalLongName" SG_ 272 AutoEPBReq "Autonomous Electric Park Brake Request";
BA_ "VNSigAllNodes" SG_ 272 AutoEPBReq 1;
BA_ "SignalType" SG_ 272 AutoBrkSysRdcPerDet "BLN";
BA_ "SignalLongName" SG_ 272 AutoBrkSysRdcPerDet "Brake System Reduced Performance Detected";
BA_ "VNSigAllNodes" SG_ 272 AutoBrkSysRdcPerDet 1;
BA_ "SignalType" SG_ 272 AutoBrkaStrgReqChksm "UNM";
BA_ "SignalLongName" SG_ 272 AutoBrkaStrgReqChksm "Autonomous Brake and Steering Request Checksum";
BA_ "VNSigAllNodes" SG_ 272 AutoBrkaStrgReqChksm 1;
BA_ "SignalType" SG_ 272 AutoBrkaStrgReqARC "UNM";
BA_ "SignalLongName" SG_ 272 AutoBrkaStrgReqARC "Autonomous Brake and Steering Request Alive Rolling Count";
BA_ "VNSigAllNodes" SG_ 272 AutoBrkaStrgReqARC 1;
BA_ "SignalType" SG_ 272 AutoBrkTrqReq "UNM";
BA_ "SignalLongName" SG_ 272 AutoBrkTrqReq "Autonomous Brake Torque Request";
BA_ "GenSigStartValue" SG_ 272 AutoBrkTrqReq 32767;
BA_ "VNSigAllNodes" SG_ 272 AutoBrkTrqReq 1;
BA_ "SignalType" SG_ 272 AutoBrkReqType "ENM";
BA_ "SignalLongName" SG_ 272 AutoBrkReqType "Autonomous Brake Request Type";
BA_ "VNSigAllNodes" SG_ 272 AutoBrkReqType 1;
BA_ "VNSigSLHSSharedDiagnostic" SG_ 583 DgnInf 1;
BA_ "SignalType" SG_ 583 DgnInf "UNM";
BA_ "SignalLongName" SG_ 583 DgnInf "Diagnostic Information";
BA_ "VNSigAllNodes" SG_ 583 DgnInf 1;
BA_ "SignalType" SG_ 320 IMULonAccPriV "ENM";
BA_ "SignalLongName" SG_ 320 IMULonAccPriV "Inertial Measurement Unit Longitudinal Acceleration Primary Validity";
BA_ "VNSigAllNodes" SG_ 320 IMULonAccPriV 1;
BA_ "SignalType" SG_ 320 IMULonAccPri "SNM";
BA_ "SignalLongName" SG_ 320 IMULonAccPri "Inertial Measurement Unit Longitudinal Acceleration Primary";
BA_ "VNSigAllNodes" SG_ 320 IMULonAccPri 1;
BA_ "SignalType" SG_ 320 IMUXAxisClbrtd "ENM";
BA_ "SignalLongName" SG_ 320 IMUXAxisClbrtd "Inertial Measurement Unit X Axis Calibrated";
BA_ "VNSigAllNodes" SG_ 320 IMUXAxisClbrtd 1;
BA_ "SignalType" SG_ 320 IMUXAxisOrntn "ENM";
BA_ "SignalLongName" SG_ 320 IMUXAxisOrntn "Inertial Measurement Unit X Axis Orientation";
BA_ "VNSigAllNodes" SG_ 320 IMUXAxisOrntn 1;
BA_ "SignalType" SG_ 320 IMUPriYawDrftTyp "ENM";
BA_ "SignalLongName" SG_ 320 IMUPriYawDrftTyp "Inertial Measurement Unit Primary Yaw Drift Type";
BA_ "VNSigAllNodes" SG_ 320 IMUPriYawDrftTyp 1;
BA_ "SignalType" SG_ 320 IMUDataMsk "BLN";
BA_ "SignalLongName" SG_ 320 IMUDataMsk "Inertial Measurement Unit Data Mask";
BA_ "VNSigAllNodes" SG_ 320 IMUDataMsk 1;
BA_ "SignalType" SG_ 320 IMUChksumSec "UNM";
BA_ "SignalLongName" SG_ 320 IMUChksumSec "Inertial Measurement Unit Checksum Secondary";
BA_ "VNSigAllNodes" SG_ 320 IMUChksumSec 1;
BA_ "SignalType" SG_ 320 IMUYawRtSecAval "BLN";
BA_ "SignalLongName" SG_ 320 IMUYawRtSecAval "Inertial Measurement Unit Yaw Rate Secondary Available";
BA_ "VNSigAllNodes" SG_ 320 IMUYawRtSecAval 1;
BA_ "SignalType" SG_ 320 IMULatAccSecAval "BLN";
BA_ "SignalLongName" SG_ 320 IMULatAccSecAval "Inertial Measurement Unit Lateral Acceleration Secondary Available";
BA_ "VNSigAllNodes" SG_ 320 IMULatAccSecAval 1;
BA_ "SignalType" SG_ 320 IMURollCntSec "UNM";
BA_ "SignalLongName" SG_ 320 IMURollCntSec "Inertial Measurement Unit Rolling Count Secondary";
BA_ "VNSigAllNodes" SG_ 320 IMURollCntSec 1;
BA_ "SignalType" SG_ 320 IMUYawRtSecV "ENM";
BA_ "SignalLongName" SG_ 320 IMUYawRtSecV "Inertial Measurement Unit Yaw Rate Secondary Validity";
BA_ "VNSigAllNodes" SG_ 320 IMUYawRtSecV 1;
BA_ "SignalType" SG_ 320 IMUYawRtSec "SNM";
BA_ "SignalLongName" SG_ 320 IMUYawRtSec "Inertial Measurement Unit Yaw Rate Secondary";
BA_ "VNSigAllNodes" SG_ 320 IMUYawRtSec 1;
BA_ "SignalType" SG_ 320 IMULatACCSecV "ENM";
BA_ "SignalLongName" SG_ 320 IMULatACCSecV "Inertial Measurement Unit Lateral Acceleration Secondary Validity";
BA_ "VNSigAllNodes" SG_ 320 IMULatACCSecV 1;
BA_ "SignalType" SG_ 320 IMULatACCSec "SNM";
BA_ "SignalLongName" SG_ 320 IMULatACCSec "Inertial Measurement Unit Lateral Acceleration Secondary";
BA_ "VNSigAllNodes" SG_ 320 IMULatACCSec 1;
BA_ "SignalType" SG_ 304 IMULonAccPriAval "BLN";
BA_ "SignalLongName" SG_ 304 IMULonAccPriAval "Inertial Measurement Unit Longitudinal Acceleration Primary Available";
BA_ "VNSigAllNodes" SG_ 304 IMULonAccPriAval 1;
BA_ "SignalType" SG_ 304 IMULonAccSecAval "BLN";
BA_ "SignalLongName" SG_ 304 IMULonAccSecAval "Inertial Measurement Unit Longitudinal Acceleration Secondary Available";
BA_ "VNSigAllNodes" SG_ 304 IMULonAccSecAval 1;
BA_ "SignalType" SG_ 304 IMULonAccSecV "ENM";
BA_ "SignalLongName" SG_ 304 IMULonAccSecV "Inertial Measurement Unit Longitudinal Acceleration Secondary Validity";
BA_ "VNSigAllNodes" SG_ 304 IMULonAccSecV 1;
BA_ "SignalType" SG_ 304 IMUYawRtAccPriSecure "SNM";
BA_ "SignalLongName" SG_ 304 IMUYawRtAccPriSecure "Inertial Measurement Unit Yaw Rate Acceleration Primary Secure";
BA_ "VNSigAllNodes" SG_ 304 IMUYawRtAccPriSecure 1;
BA_ "SignalType" SG_ 304 IMUYawRtPriV "ENM";
BA_ "SignalLongName" SG_ 304 IMUYawRtPriV "Inertial Measurement Unit Yaw Rate Primary Validity";
BA_ "VNSigAllNodes" SG_ 304 IMUYawRtPriV 1;
BA_ "SignalType" SG_ 304 IMUYawRtPri "SNM";
BA_ "SignalLongName" SG_ 304 IMUYawRtPri "Inertial Measurement Unit Yaw Rate Primary";
BA_ "VNSigAllNodes" SG_ 304 IMUYawRtPri 1;
BA_ "SignalType" SG_ 304 IMURollCntPri "UNM";
BA_ "SignalLongName" SG_ 304 IMURollCntPri "Inertial Measurement Unit Rolling Count Primary";
BA_ "VNSigAllNodes" SG_ 304 IMURollCntPri 1;
BA_ "SignalType" SG_ 304 IMUChksumPri "UNM";
BA_ "SignalLongName" SG_ 304 IMUChksumPri "Inertial Measurement Unit Checksum Primary";
BA_ "VNSigAllNodes" SG_ 304 IMUChksumPri 1;
BA_ "SignalType" SG_ 304 IMULonAccSec "SNM";
BA_ "SignalLongName" SG_ 304 IMULonAccSec "Inertial Measurement Unit Longitudinal Acceleration Secondary";
BA_ "VNSigAllNodes" SG_ 304 IMULonAccSec 1;
BA_ "SignalType" SG_ 304 IMULatAccPrim "SNM";
BA_ "SignalLongName" SG_ 304 IMULatAccPrim "Inertial Measurement Unit Lateral Acceleration Primary";
BA_ "VNSigAllNodes" SG_ 304 IMULatAccPrim 1;
BA_ "SignalType" SG_ 304 IMULatAccPrimV "ENM";
BA_ "SignalLongName" SG_ 304 IMULatAccPrimV "Inertial Measurement Unit Lateral Acceleration Primary Validity";
BA_ "VNSigAllNodes" SG_ 304 IMULatAccPrimV 1;
BA_ "SignalType" SG_ 840 DrvnWhlGrndVelChksm "UNM";
BA_ "SignalLongName" SG_ 840 DrvnWhlGrndVelChksm "Driven Wheel Ground Velocity Checksum";
BA_ "VNSigAllNodes" SG_ 840 DrvnWhlGrndVelChksm 1;
BA_ "SignalType" SG_ 840 WhlRotDrctnlStRtDrvn "ENM";
BA_ "SignalLongName" SG_ 840 WhlRotDrctnlStRtDrvn "Wheel Rotational Directional Status Right Driven";
BA_ "VNSigAllNodes" SG_ 840 WhlRotDrctnlStRtDrvn 1;
BA_ "SignalType" SG_ 840 WhlRotDrctnlStLftDrvn "ENM";
BA_ "SignalLongName" SG_ 840 WhlRotDrctnlStLftDrvn "Wheel Rotational Directional Status Left Driven";
BA_ "VNSigAllNodes" SG_ 840 WhlRotDrctnlStLftDrvn 1;
BA_ "SignalType" SG_ 840 WhlPlsPerRevDrvn "UNM";
BA_ "SignalLongName" SG_ 840 WhlPlsPerRevDrvn "Wheel Pulses Per Revolution Driven";
BA_ "VNSigAllNodes" SG_ 840 WhlPlsPerRevDrvn 1;
BA_ "SignalType" SG_ 840 WhlGrndVlctyRtDrvnV "ENM";
BA_ "SignalLongName" SG_ 840 WhlGrndVlctyRtDrvnV "Wheel Ground Velocity Right Driven Validity";
BA_ "VNSigAllNodes" SG_ 840 WhlGrndVlctyRtDrvnV 1;
BA_ "SignalType" SG_ 840 WhlGrndVlctyRtDrvn "UNM";
BA_ "SignalLongName" SG_ 840 WhlGrndVlctyRtDrvn "Wheel Ground Velocity Right Driven";
BA_ "VNSigAllNodes" SG_ 840 WhlGrndVlctyRtDrvn 1;
BA_ "SignalType" SG_ 840 WhlGrndVlctyLftDrvnV "ENM";
BA_ "SignalLongName" SG_ 840 WhlGrndVlctyLftDrvnV "Wheel Ground Velocity Left Driven Validity";
BA_ "VNSigAllNodes" SG_ 840 WhlGrndVlctyLftDrvnV 1;
BA_ "SignalType" SG_ 840 WhlGrndVlctyLftDrvn "UNM";
BA_ "SignalLongName" SG_ 840 WhlGrndVlctyLftDrvn "Wheel Ground Velocity Left Driven";
BA_ "VNSigAllNodes" SG_ 840 WhlGrndVlctyLftDrvn 1;
BA_ "SignalType" SG_ 840 DrvnWhlGrndVelARC "UNM";
BA_ "SignalLongName" SG_ 840 DrvnWhlGrndVelARC "Driven Wheel Ground Velocity Alive Rolling Count";
BA_ "VNSigAllNodes" SG_ 840 DrvnWhlGrndVelARC 1;
BA_ "SignalType" SG_ 842 NDrvnWhlGrndVelChksm "UNM";
BA_ "SignalLongName" SG_ 842 NDrvnWhlGrndVelChksm "Non Driven Wheel Ground Velocity Checksum";
BA_ "VNSigAllNodes" SG_ 842 NDrvnWhlGrndVelChksm 1;
BA_ "SignalType" SG_ 842 NDrvnWhlGrndVelARC "UNM";
BA_ "SignalLongName" SG_ 842 NDrvnWhlGrndVelARC "Non Driven Wheel Ground Velocity Alive Rolling Count";
BA_ "VNSigAllNodes" SG_ 842 NDrvnWhlGrndVelARC 1;
BA_ "SignalType" SG_ 842 WhlRotDrctnlSRtNDrvn "ENM";
BA_ "SignalLongName" SG_ 842 WhlRotDrctnlSRtNDrvn "Wheel Rotational Directional Status Right Non Driven";
BA_ "VNSigAllNodes" SG_ 842 WhlRotDrctnlSRtNDrvn 1;
BA_ "SignalType" SG_ 842 WhlRotDrctnlStLfNDrvn "ENM";
BA_ "SignalLongName" SG_ 842 WhlRotDrctnlStLfNDrvn "Wheel Rotational Directional Status Left Non Driven";
BA_ "VNSigAllNodes" SG_ 842 WhlRotDrctnlStLfNDrvn 1;
BA_ "SignalType" SG_ 842 WhlPlsPerRevNonDrvn "UNM";
BA_ "SignalLongName" SG_ 842 WhlPlsPerRevNonDrvn "Wheel Pulses Per Revolution Non Driven";
BA_ "VNSigAllNodes" SG_ 842 WhlPlsPerRevNonDrvn 1;
BA_ "SignalType" SG_ 842 WhlGrndVlctyRtNnDrvnV "ENM";
BA_ "SignalLongName" SG_ 842 WhlGrndVlctyRtNnDrvnV "Wheel Ground Velocity Right Non Driven Validity";
BA_ "VNSigAllNodes" SG_ 842 WhlGrndVlctyRtNnDrvnV 1;
BA_ "SignalType" SG_ 842 WhlGrndVlctyRtNnDrvn "UNM";
BA_ "SignalLongName" SG_ 842 WhlGrndVlctyRtNnDrvn "Wheel Ground Velocity Right Non Driven";
BA_ "VNSigAllNodes" SG_ 842 WhlGrndVlctyRtNnDrvn 1;
BA_ "SignalType" SG_ 842 WhlGrndVlctyLftNnDrvnV "ENM";
BA_ "SignalLongName" SG_ 842 WhlGrndVlctyLftNnDrvnV "Wheel Ground Velocity Left Non Driven Validity";
BA_ "VNSigAllNodes" SG_ 842 WhlGrndVlctyLftNnDrvnV 1;
BA_ "SignalType" SG_ 842 WhlGrndVlctyLftNnDrvn "UNM";
BA_ "SignalLongName" SG_ 842 WhlGrndVlctyLftNnDrvn "Wheel Ground Velocity Left Non Driven";
BA_ "VNSigAllNodes" SG_ 842 WhlGrndVlctyLftNnDrvn 1;
BA_ "SignalType" SG_ 1001 VehSpdAvgNDrvnV "ENM";
BA_ "SignalLongName" SG_ 1001 VehSpdAvgNDrvnV "Vehicle Speed Average Non Driven Validity";
BA_ "VNSigAllNodes" SG_ 1001 VehSpdAvgNDrvnV 1;
BA_ "SignalType" SG_ 1001 VehSpdAvgNDrvn "UNM";
BA_ "SignalLongName" SG_ 1001 VehSpdAvgNDrvn "Vehicle Speed Average Non Driven";
BA_ "VNSigAllNodes" SG_ 1001 VehSpdAvgNDrvn 1;
BA_ "SignalType" SG_ 1001 VehSpdAvgDrvnV "ENM";
BA_ "SignalLongName" SG_ 1001 VehSpdAvgDrvnV "Vehicle Speed Average Driven Validity";
BA_ "VNSigAllNodes" SG_ 1001 VehSpdAvgDrvnV 1;
BA_ "SignalType" SG_ 1001 VehSpdAvgDrvnSrc "ENM";
BA_ "SignalLongName" SG_ 1001 VehSpdAvgDrvnSrc "Vehicle Speed Average Driven Source";
BA_ "VNSigAllNodes" SG_ 1001 VehSpdAvgDrvnSrc 1;
BA_ "SignalType" SG_ 1001 VehSpdAvgDrvn "UNM";
BA_ "SignalLongName" SG_ 1001 VehSpdAvgDrvn "Vehicle Speed Average Driven";
BA_ "VNSigAllNodes" SG_ 1001 VehSpdAvgDrvn 1;
BA_ "VNSigSLHSSharedDiagnostic" SG_ 1608 DgnInf 1;
BA_ "SignalType" SG_ 1608 DgnInf "UNM";
BA_ "SignalLongName" SG_ 1608 DgnInf "Diagnostic Information";
BA_ "VNSigAllNodes" SG_ 1608 DgnInf 1;
BA_ "SignalType" SG_ 197 WRSLNDWhlDisTpRC "UNM";
BA_ "PacketOrder" SG_ 197 WRSLNDWhlDisTpRC 1;
BA_ "SignalLongName" SG_ 197 WRSLNDWhlDisTpRC "Wheel Rotational Status Left Non Driven : Wheel Distance Timestamp Rollover Counter";
BA_ "VNSigAllNodes" SG_ 197 WRSLNDWhlDisTpRC 1;
BA_ "SignalType" SG_ 197 WRSLNDWhlRotStRst "BLN";
BA_ "PacketOrder" SG_ 197 WRSLNDWhlRotStRst 3;
BA_ "SignalLongName" SG_ 197 WRSLNDWhlRotStRst "Wheel Rotational Status Left Non Driven : Wheel Rotational Status Reset Occurred";
BA_ "VNSigAllNodes" SG_ 197 WRSLNDWhlRotStRst 1;
BA_ "SignalType" SG_ 197 WRSLNDWhlDistVal "ENM";
BA_ "PacketOrder" SG_ 197 WRSLNDWhlDistVal 4;
BA_ "SignalLongName" SG_ 197 WRSLNDWhlDistVal "Wheel Rotational Status Left Non Driven : Wheel Distance Validity";
BA_ "VNSigAllNodes" SG_ 197 WRSLNDWhlDistVal 1;
BA_ "SignalType" SG_ 197 WRSLNDWhlDistTstm "UNM";
BA_ "PacketOrder" SG_ 197 WRSLNDWhlDistTstm 6;
BA_ "SignalLongName" SG_ 197 WRSLNDWhlDistTstm "Wheel Rotational Status Left Non Driven : Wheel Distance Timestamp";
BA_ "VNSigAllNodes" SG_ 197 WRSLNDWhlDistTstm 1;
BA_ "SignalType" SG_ 197 WRSLNDWhlDistPCntr "UNM";
BA_ "PacketOrder" SG_ 197 WRSLNDWhlDistPCntr 5;
BA_ "SignalLongName" SG_ 197 WRSLNDWhlDistPCntr "Wheel Rotational Status Left Non Driven : Wheel Distance Pulse Counter";
BA_ "VNSigAllNodes" SG_ 197 WRSLNDWhlDistPCntr 1;
BA_ "SignalType" SG_ 197 WRSLNDSeqNum "UNM";
BA_ "PacketOrder" SG_ 197 WRSLNDSeqNum 2;
BA_ "SignalLongName" SG_ 197 WRSLNDSeqNum "Wheel Rotational Status Left Non Driven : Sequence Number";
BA_ "VNSigAllNodes" SG_ 197 WRSLNDSeqNum 1;
BA_ "SignalType" SG_ 197 WRSRNDWhlRotStRst "BLN";
BA_ "PacketOrder" SG_ 197 WRSRNDWhlRotStRst 3;
BA_ "SignalLongName" SG_ 197 WRSRNDWhlRotStRst "Wheel Rotational Status Right Non Driven : Wheel Rotational Status Reset Occurred";
BA_ "VNSigAllNodes" SG_ 197 WRSRNDWhlRotStRst 1;
BA_ "SignalType" SG_ 197 WRSRNDWhlDisTpRC "UNM";
BA_ "PacketOrder" SG_ 197 WRSRNDWhlDisTpRC 1;
BA_ "SignalLongName" SG_ 197 WRSRNDWhlDisTpRC "Wheel Rotational Status Right Non Driven : Wheel Distance Timestamp Rollover Counter";
BA_ "VNSigAllNodes" SG_ 197 WRSRNDWhlDisTpRC 1;
BA_ "SignalType" SG_ 197 WRSRNDWhlDistVal "ENM";
BA_ "PacketOrder" SG_ 197 WRSRNDWhlDistVal 4;
BA_ "SignalLongName" SG_ 197 WRSRNDWhlDistVal "Wheel Rotational Status Right Non Driven : Wheel Distance Validity";
BA_ "VNSigAllNodes" SG_ 197 WRSRNDWhlDistVal 1;
BA_ "SignalType" SG_ 197 WRSRNDWhlDistTstm "UNM";
BA_ "PacketOrder" SG_ 197 WRSRNDWhlDistTstm 6;
BA_ "SignalLongName" SG_ 197 WRSRNDWhlDistTstm "Wheel Rotational Status Right Non Driven : Wheel Distance Timestamp";
BA_ "VNSigAllNodes" SG_ 197 WRSRNDWhlDistTstm 1;
BA_ "SignalType" SG_ 197 WRSRNDWhlDistPCntr "UNM";
BA_ "PacketOrder" SG_ 197 WRSRNDWhlDistPCntr 5;
BA_ "SignalLongName" SG_ 197 WRSRNDWhlDistPCntr "Wheel Rotational Status Right Non Driven : Wheel Distance Pulse Counter";
BA_ "VNSigAllNodes" SG_ 197 WRSRNDWhlDistPCntr 1;
BA_ "SignalType" SG_ 197 WRSRNDSeqNum "UNM";
BA_ "PacketOrder" SG_ 197 WRSRNDSeqNum 2;
BA_ "SignalLongName" SG_ 197 WRSRNDSeqNum "Wheel Rotational Status Right Non Driven : Sequence Number";
BA_ "VNSigAllNodes" SG_ 197 WRSRNDSeqNum 1;
BA_ "SignalType" SG_ 289 SysPwMdVDA "ENM";
BA_ "SignalLongName" SG_ 289 SysPwMdVDA "System Power Mode Virtual Device Availability";
BA_ "GenSigStartValue" SG_ 289 SysPwMdVDA 1;
BA_ "VNSigAllNodes" SG_ 289 SysPwMdVDA 1;
BA_ "SignalType" SG_ 289 TrStLgMdAtv "BLN";
BA_ "SignalLongName" SG_ 289 TrStLgMdAtv "Transport Storage Logistic Mode Active";
BA_ "VNSigAllNodes" SG_ 289 TrStLgMdAtv 1;
BA_ "SignalType" SG_ 289 SysPwrMd "ENM";
BA_ "SignalLongName" SG_ 289 SysPwrMd "System Power Mode";
BA_ "VNSigAllNodes" SG_ 289 SysPwrMd 1;
BA_ "SignalType" SG_ 290 BkupPwrModeMstrVDA "ENM";
BA_ "SignalLongName" SG_ 290 BkupPwrModeMstrVDA "Backup Power Mode Master Virtual Device Availability";
BA_ "GenSigStartValue" SG_ 290 BkupPwrModeMstrVDA 1;
BA_ "VNSigAllNodes" SG_ 290 BkupPwrModeMstrVDA 1;
BA_ "SignalType" SG_ 290 SysBkupPwrMdEn "BLN";
BA_ "SignalLongName" SG_ 290 SysBkupPwrMdEn "System Backup Power Mode Enabled";
BA_ "VNSigAllNodes" SG_ 290 SysBkupPwrMdEn 1;
BA_ "SignalType" SG_ 290 SysBkUpPwrMd "ENM";
BA_ "SignalLongName" SG_ 290 SysBkUpPwrMd "System Backup Power Mode";
BA_ "VNSigAllNodes" SG_ 290 SysBkUpPwrMd 1;
BA_ "VNSigSLHSSharedDiagnostic" SG_ 1371 DgnInf_CE55B 1;
BA_ "SignalType" SG_ 1371 DgnInf_CE55B "UNM";
BA_ "SignalLongName" SG_ 1371 DgnInf_CE55B "Diagnostic Information CE55B";
BA_ "VNSigAllNodes" SG_ 1371 DgnInf_CE55B 1;
BA_ "SignalType" SG_ 485 StrAngSnsChksm "UNM";
BA_ "SignalLongName" SG_ 485 StrAngSnsChksm "Steering Angle Sensor Checksum";
BA_ "VNSigAllNodes" SG_ 485 StrAngSnsChksm 1;
BA_ "SignalType" SG_ 485 StrWhAngGrdV "ENM";
BA_ "SignalLongName" SG_ 485 StrWhAngGrdV "Steering Wheel Angle Gradient Validity";
BA_ "VNSigAllNodes" SG_ 485 StrWhAngGrdV 1;
BA_ "SignalType" SG_ 485 StrWhAngGrdMsk "ENM";
BA_ "SignalLongName" SG_ 485 StrWhAngGrdMsk "Steering Wheel Angle Gradient Mask";
BA_ "VNSigAllNodes" SG_ 485 StrWhAngGrdMsk 1;
BA_ "SignalType" SG_ 485 StrWhAngMsk "ENM";
BA_ "SignalLongName" SG_ 485 StrWhAngMsk "Steering Wheel Angle Mask";
BA_ "VNSigAllNodes" SG_ 485 StrWhAngMsk 1;
BA_ "SignalType" SG_ 485 StrWhlAngSenTyp "ENM";
BA_ "SignalLongName" SG_ 485 StrWhlAngSenTyp "Steering Wheel Angle Sensor Type";
BA_ "VNSigAllNodes" SG_ 485 StrWhlAngSenTyp 1;
BA_ "SignalType" SG_ 485 StrWhlAngSenCalStat "ENM";
BA_ "SignalLongName" SG_ 485 StrWhlAngSenCalStat "Steering Wheel Angle Sensor Calibration Status";
BA_ "VNSigAllNodes" SG_ 485 StrWhlAngSenCalStat 1;
BA_ "SignalType" SG_ 485 StrWhAngGrd "SNM";
BA_ "SignalLongName" SG_ 485 StrWhAngGrd "Steering Wheel Angle Gradient";
BA_ "VNSigAllNodes" SG_ 485 StrWhAngGrd 1;
BA_ "SignalType" SG_ 485 StWhlAngAliveRollCnt "UNM";
BA_ "SignalLongName" SG_ 485 StWhlAngAliveRollCnt "Steering Wheel Angle Alive Rolling Count";
BA_ "VNSigAllNodes" SG_ 485 StWhlAngAliveRollCnt 1;
BA_ "SignalType" SG_ 485 StrWhAngV "ENM";
BA_ "SignalLongName" SG_ 485 StrWhAngV "Steering Wheel Angle Validity";
BA_ "VNSigAllNodes" SG_ 485 StrWhAngV 1;
BA_ "SignalType" SG_ 485 StrWhAng "SNM";
BA_ "SignalLongName" SG_ 485 StrWhAng "Steering Wheel Angle";
BA_ "VNSigAllNodes" SG_ 485 StrWhAng 1;
BA_ "SignalType" SG_ 192 WRSCD_RNDrvnCkVa "UNM";
BA_ "PacketOrder" SG_ 192 WRSCD_RNDrvnCkVa 8;
BA_ "SignalLongName" SG_ 192 WRSCD_RNDrvnCkVa "Wheel Rotational Status Check Data : Right Non Driven Check Value";
BA_ "VNSigAllNodes" SG_ 192 WRSCD_RNDrvnCkVa 1;
BA_ "SignalType" SG_ 192 WRSCD_LfNDrvnCkVa "UNM";
BA_ "PacketOrder" SG_ 192 WRSCD_LfNDrvnCkVa 7;
BA_ "SignalLongName" SG_ 192 WRSCD_LfNDrvnCkVa "Wheel Rotational Status Check Data : Left Non Driven Check Value";
BA_ "VNSigAllNodes" SG_ 192 WRSCD_LfNDrvnCkVa 1;
BA_ "SignalType" SG_ 192 WRSCD_RDrvnCkVa "UNM";
BA_ "PacketOrder" SG_ 192 WRSCD_RDrvnCkVa 6;
BA_ "SignalLongName" SG_ 192 WRSCD_RDrvnCkVa "Wheel Rotational Status Check Data : Right Driven Check Value";
BA_ "VNSigAllNodes" SG_ 192 WRSCD_RDrvnCkVa 1;
BA_ "SignalType" SG_ 192 WRSCD_LfDrvnCkVa "UNM";
BA_ "PacketOrder" SG_ 192 WRSCD_LfDrvnCkVa 5;
BA_ "SignalLongName" SG_ 192 WRSCD_LfDrvnCkVa "Wheel Rotational Status Check Data : Left Driven Check Value";
BA_ "VNSigAllNodes" SG_ 192 WRSCD_LfDrvnCkVa 1;
BA_ "SignalType" SG_ 192 WRSCD_RtNDrvnSNm "UNM";
BA_ "PacketOrder" SG_ 192 WRSCD_RtNDrvnSNm 4;
BA_ "SignalLongName" SG_ 192 WRSCD_RtNDrvnSNm "Wheel Rotational Status Check Data : Right Non Driven Sequence Number";
BA_ "VNSigAllNodes" SG_ 192 WRSCD_RtNDrvnSNm 1;
BA_ "SignalType" SG_ 192 WRSCD_LftNDrvnSNm "UNM";
BA_ "PacketOrder" SG_ 192 WRSCD_LftNDrvnSNm 3;
BA_ "SignalLongName" SG_ 192 WRSCD_LftNDrvnSNm "Wheel Rotational Status Check Data : Left Non Driven Sequence Number";
BA_ "VNSigAllNodes" SG_ 192 WRSCD_LftNDrvnSNm 1;
BA_ "SignalType" SG_ 192 WRSCD_RtDrvnSqNm "UNM";
BA_ "PacketOrder" SG_ 192 WRSCD_RtDrvnSqNm 2;
BA_ "SignalLongName" SG_ 192 WRSCD_RtDrvnSqNm "Wheel Rotational Status Check Data : Right Driven Sequence Number";
BA_ "VNSigAllNodes" SG_ 192 WRSCD_RtDrvnSqNm 1;
BA_ "SignalType" SG_ 192 WRSCD_LftDrvnSqNm "UNM";
BA_ "PacketOrder" SG_ 192 WRSCD_LftDrvnSqNm 1;
BA_ "SignalLongName" SG_ 192 WRSCD_LftDrvnSqNm "Wheel Rotational Status Check Data : Left Driven Sequence Number";
BA_ "VNSigAllNodes" SG_ 192 WRSCD_LftDrvnSqNm 1;
BA_ "SignalType" SG_ 193 WRSLDWhlRotStatRst "BLN";
BA_ "PacketOrder" SG_ 193 WRSLDWhlRotStatRst 3;
BA_ "SignalLongName" SG_ 193 WRSLDWhlRotStatRst "Wheel Rotational Status Left Driven : Wheel Rotational Status Reset Occurred";
BA_ "VNSigAllNodes" SG_ 193 WRSLDWhlRotStatRst 1;
BA_ "SignalType" SG_ 193 WRSLDWhlDisTpRC "UNM";
BA_ "PacketOrder" SG_ 193 WRSLDWhlDisTpRC 1;
BA_ "SignalLongName" SG_ 193 WRSLDWhlDisTpRC "Wheel Rotational Status Left Driven : Wheel Distance Timestamp Rollover Counter";
BA_ "VNSigAllNodes" SG_ 193 WRSLDWhlDisTpRC 1;
BA_ "SignalType" SG_ 193 WRSLDSeqNum "UNM";
BA_ "PacketOrder" SG_ 193 WRSLDSeqNum 2;
BA_ "SignalLongName" SG_ 193 WRSLDSeqNum "Wheel Rotational Status Left Driven : Sequence Number";
BA_ "VNSigAllNodes" SG_ 193 WRSLDSeqNum 1;
BA_ "SignalType" SG_ 193 WRSLDWhlDistVal "ENM";
BA_ "PacketOrder" SG_ 193 WRSLDWhlDistVal 4;
BA_ "SignalLongName" SG_ 193 WRSLDWhlDistVal "Wheel Rotational Status Left Driven : Wheel Distance Validity";
BA_ "VNSigAllNodes" SG_ 193 WRSLDWhlDistVal 1;
BA_ "SignalType" SG_ 193 WRSLDWhlDistTmstm "UNM";
BA_ "PacketOrder" SG_ 193 WRSLDWhlDistTmstm 6;
BA_ "SignalLongName" SG_ 193 WRSLDWhlDistTmstm "Wheel Rotational Status Left Driven : Wheel Distance Timestamp";
BA_ "VNSigAllNodes" SG_ 193 WRSLDWhlDistTmstm 1;
BA_ "SignalType" SG_ 193 WRSLDWhlDistPlsCntr "UNM";
BA_ "PacketOrder" SG_ 193 WRSLDWhlDistPlsCntr 5;
BA_ "SignalLongName" SG_ 193 WRSLDWhlDistPlsCntr "Wheel Rotational Status Left Driven : Wheel Distance Pulse Counter";
BA_ "VNSigAllNodes" SG_ 193 WRSLDWhlDistPlsCntr 1;
BA_ "SignalType" SG_ 193 WRSRDWhlDisTpRC "UNM";
BA_ "PacketOrder" SG_ 193 WRSRDWhlDisTpRC 1;
BA_ "SignalLongName" SG_ 193 WRSRDWhlDisTpRC "Wheel Rotational Status Right Driven : Wheel Distance Timestamp Rollover Counter";
BA_ "VNSigAllNodes" SG_ 193 WRSRDWhlDisTpRC 1;
BA_ "SignalType" SG_ 193 WRSRDSeqNum "UNM";
BA_ "PacketOrder" SG_ 193 WRSRDSeqNum 2;
BA_ "SignalLongName" SG_ 193 WRSRDSeqNum "Wheel Rotational Status Right Driven : Sequence Number";
BA_ "VNSigAllNodes" SG_ 193 WRSRDSeqNum 1;
BA_ "SignalType" SG_ 193 WRSRDWhlRotStatRst "BLN";
BA_ "PacketOrder" SG_ 193 WRSRDWhlRotStatRst 3;
BA_ "SignalLongName" SG_ 193 WRSRDWhlRotStatRst "Wheel Rotational Status Right Driven : Wheel Rotational Status Reset Occurred";
BA_ "VNSigAllNodes" SG_ 193 WRSRDWhlRotStatRst 1;
BA_ "SignalType" SG_ 193 WRSRDWhlDistVal "ENM";
BA_ "PacketOrder" SG_ 193 WRSRDWhlDistVal 4;
BA_ "SignalLongName" SG_ 193 WRSRDWhlDistVal "Wheel Rotational Status Right Driven : Wheel Distance Validity";
BA_ "VNSigAllNodes" SG_ 193 WRSRDWhlDistVal 1;
BA_ "SignalType" SG_ 193 WRSRDWhlDistTmstm "UNM";
BA_ "PacketOrder" SG_ 193 WRSRDWhlDistTmstm 6;
BA_ "SignalLongName" SG_ 193 WRSRDWhlDistTmstm "Wheel Rotational Status Right Driven : Wheel Distance Timestamp";
BA_ "VNSigAllNodes" SG_ 193 WRSRDWhlDistTmstm 1;
BA_ "SignalType" SG_ 193 WRSRDWhlDistPlsCntr "UNM";
BA_ "PacketOrder" SG_ 193 WRSRDWhlDistPlsCntr 5;
BA_ "SignalLongName" SG_ 193 WRSRDWhlDistPlsCntr "Wheel Rotational Status Right Driven : Wheel Distance Pulse Counter";
BA_ "VNSigAllNodes" SG_ 193 WRSRDWhlDistPlsCntr 1;
BA_ "VNSigSLHSSharedDiagnostic" SG_ 257 DgnInf 1;
BA_ "SignalType" SG_ 257 DgnInf "UNM";
BA_ "SignalLongName" SG_ 257 DgnInf "Diagnostic Information";
BA_ "VNSigAllNodes" SG_ 257 DgnInf 1;
BA_ "VNSigSLHSSharedDiagnostic" SG_ 1367 DgnInf_CE557 1;
BA_ "SignalType" SG_ 1367 DgnInf_CE557 "UNM";
BA_ "SignalLongName" SG_ 1367 DgnInf_CE557 "Diagnostic Information CE557";
BA_ "VNSigAllNodes" SG_ 1367 DgnInf_CE557 1;
BA_ "VNSigSLHSSharedDiagnostic" SG_ 599 DgnInf 1;
BA_ "SignalType" SG_ 599 DgnInf "UNM";
BA_ "SignalLongName" SG_ 599 DgnInf "Diagnostic Information";
BA_ "VNSigAllNodes" SG_ 599 DgnInf 1;
BA_REL_ "GenSigRxStartValue" BU_SG_REL_ EBOOST_OBD_PCE SG_ 339 CoPRVBAtvRed "False";
BA_REL_ "GenSigSuprvResp" BU_SG_REL_ EBOOST_OBD_PCE SG_ 339 CoPRVBAtvRed 1;
BA_REL_ "GenSigTimeoutMsg" BU_SG_REL_ EBOOST_OBD_PCE SG_ 339 CoPRVBAtvRed 339;
BA_REL_ "GenSigTimeoutTime" BU_SG_REL_ EBOOST_OBD_PCE SG_ 339 CoPRVBAtvRed 25;
BA_REL_ "GenSigRxStartValue" BU_SG_REL_ EBCM_PCE SG_ 339 CoPRVBAtvRed "False";
BA_REL_ "GenSigSuprvResp" BU_SG_REL_ EBCM_PCE SG_ 339 CoPRVBAtvRed 1;
BA_REL_ "GenSigTimeoutMsg" BU_SG_REL_ EBCM_PCE SG_ 339 CoPRVBAtvRed 339;
BA_REL_ "GenSigTimeoutTime" BU_SG_REL_ EBCM_PCE SG_ 339 CoPRVBAtvRed 25;
BA_REL_ "GenSigRxStartValue" BU_SG_REL_ EBOOST_OBD_PCE SG_ 339 CoPCIBAtvRed "False";
BA_REL_ "GenSigSuprvResp" BU_SG_REL_ EBOOST_OBD_PCE SG_ 339 CoPCIBAtvRed 1;
BA_REL_ "GenSigTimeoutMsg" BU_SG_REL_ EBOOST_OBD_PCE SG_ 339 CoPCIBAtvRed 339;
BA_REL_ "GenSigTimeoutTime" BU_SG_REL_ EBOOST_OBD_PCE SG_ 339 CoPCIBAtvRed 25;
BA_REL_ "GenSigRxStartValue" BU_SG_REL_ EBCM_PCE SG_ 339 CoPCIBAtvRed "False";
BA_REL_ "GenSigSuprvResp" BU_SG_REL_ EBCM_PCE SG_ 339 CoPCIBAtvRed 1;
BA_REL_ "GenSigTimeoutMsg" BU_SG_REL_ EBCM_PCE SG_ 339 CoPCIBAtvRed 339;
BA_REL_ "GenSigTimeoutTime" BU_SG_REL_ EBCM_PCE SG_ 339 CoPCIBAtvRed 25;
BA_REL_ "GenSigRxStartValue" BU_SG_REL_ EBOOST_OBD_PCE SG_ 339 CPEPSWARR_TrgtAng "0";
BA_REL_ "GenSigSuprvResp" BU_SG_REL_ EBOOST_OBD_PCE SG_ 339 CPEPSWARR_TrgtAng 1;
BA_REL_ "GenSigTimeoutMsg" BU_SG_REL_ EBOOST_OBD_PCE SG_ 339 CPEPSWARR_TrgtAng 339;
BA_REL_ "GenSigTimeoutTime" BU_SG_REL_ EBOOST_OBD_PCE SG_ 339 CPEPSWARR_TrgtAng 25;
BA_REL_ "GenSigRxStartValue" BU_SG_REL_ EBCM_PCE SG_ 339 CPEPSWARR_TrgtAng "0";
BA_REL_ "GenSigSuprvResp" BU_SG_REL_ EBCM_PCE SG_ 339 CPEPSWARR_TrgtAng 1;
BA_REL_ "GenSigTimeoutMsg" BU_SG_REL_ EBCM_PCE SG_ 339 CPEPSWARR_TrgtAng 339;
BA_REL_ "GenSigTimeoutTime" BU_SG_REL_ EBCM_PCE SG_ 339 CPEPSWARR_TrgtAng 25;
BA_REL_ "GenSigRxStartValue" BU_SG_REL_ EBOOST_OBD_PCE SG_ 339 CPEPSWARR_ReqdState "0";
BA_REL_ "GenSigSuprvResp" BU_SG_REL_ EBOOST_OBD_PCE SG_ 339 CPEPSWARR_ReqdState 1;
BA_REL_ "GenSigTimeoutMsg" BU_SG_REL_ EBOOST_OBD_PCE SG_ 339 CPEPSWARR_ReqdState 339;
BA_REL_ "GenSigTimeoutTime" BU_SG_REL_ EBOOST_OBD_PCE SG_ 339 CPEPSWARR_ReqdState 25;
BA_REL_ "GenSigRxStartValue" BU_SG_REL_ EBCM_PCE SG_ 339 CPEPSWARR_ReqdState "0";
BA_REL_ "GenSigSuprvResp" BU_SG_REL_ EBCM_PCE SG_ 339 CPEPSWARR_ReqdState 1;
BA_REL_ "GenSigTimeoutMsg" BU_SG_REL_ EBCM_PCE SG_ 339 CPEPSWARR_ReqdState 339;
BA_REL_ "GenSigTimeoutTime" BU_SG_REL_ EBCM_PCE SG_ 339 CPEPSWARR_ReqdState 25;
BA_REL_ "GenSigRxStartValue" BU_SG_REL_ EBOOST_OBD_PCE SG_ 339 CoPEPBReqRed "0";
BA_REL_ "GenSigSuprvResp" BU_SG_REL_ EBOOST_OBD_PCE SG_ 339 CoPEPBReqRed 1;
BA_REL_ "GenSigTimeoutMsg" BU_SG_REL_ EBOOST_OBD_PCE SG_ 339 CoPEPBReqRed 339;
BA_REL_ "GenSigTimeoutTime" BU_SG_REL_ EBOOST_OBD_PCE SG_ 339 CoPEPBReqRed 25;
BA_REL_ "GenSigRxStartValue" BU_SG_REL_ EBCM_PCE SG_ 339 CoPEPBReqRed "0";
BA_REL_ "GenSigSuprvResp" BU_SG_REL_ EBCM_PCE SG_ 339 CoPEPBReqRed 1;
BA_REL_ "GenSigTimeoutMsg" BU_SG_REL_ EBCM_PCE SG_ 339 CoPEPBReqRed 339;
BA_REL_ "GenSigTimeoutTime" BU_SG_REL_ EBCM_PCE SG_ 339 CoPEPBReqRed 25;
BA_REL_ "GenSigRxStartValue" BU_SG_REL_ EBOOST_OBD_PCE SG_ 339 CoPBaSRedChksm "0";
BA_REL_ "GenSigRxStartValue" BU_SG_REL_ EBCM_PCE SG_ 339 CoPBaSRedChksm "0";
BA_REL_ "GenSigRxStartValue" BU_SG_REL_ EBOOST_OBD_PCE SG_ 339 CoPBaSRedARC "0";
BA_REL_ "GenSigRxStartValue" BU_SG_REL_ EBCM_PCE SG_ 339 CoPBaSRedARC "0";
BA_REL_ "GenSigRxStartValue" BU_SG_REL_ EBOOST_OBD_PCE SG_ 339 CoPCntrlFailRed "False";
BA_REL_ "GenSigSuprvResp" BU_SG_REL_ EBOOST_OBD_PCE SG_ 339 CoPCntrlFailRed 1;
BA_REL_ "GenSigTimeoutMsg" BU_SG_REL_ EBOOST_OBD_PCE SG_ 339 CoPCntrlFailRed 339;
BA_REL_ "GenSigTimeoutTime" BU_SG_REL_ EBOOST_OBD_PCE SG_ 339 CoPCntrlFailRed 25;
BA_REL_ "GenSigRxStartValue" BU_SG_REL_ EBCM_PCE SG_ 339 CoPCntrlFailRed "False";
BA_REL_ "GenSigSuprvResp" BU_SG_REL_ EBCM_PCE SG_ 339 CoPCntrlFailRed 1;
BA_REL_ "GenSigTimeoutMsg" BU_SG_REL_ EBCM_PCE SG_ 339 CoPCntrlFailRed 339;
BA_REL_ "GenSigTimeoutTime" BU_SG_REL_ EBCM_PCE SG_ 339 CoPCntrlFailRed 25;
BA_REL_ "GenSigRxStartValue" BU_SG_REL_ EBOOST_OBD_PCE SG_ 339 CoPAutoBrkTrqReqRed "0";
BA_REL_ "GenSigSuprvResp" BU_SG_REL_ EBOOST_OBD_PCE SG_ 339 CoPAutoBrkTrqReqRed 1;
BA_REL_ "GenSigTimeoutMsg" BU_SG_REL_ EBOOST_OBD_PCE SG_ 339 CoPAutoBrkTrqReqRed 339;
BA_REL_ "GenSigTimeoutTime" BU_SG_REL_ EBOOST_OBD_PCE SG_ 339 CoPAutoBrkTrqReqRed 25;
BA_REL_ "GenSigRxStartValue" BU_SG_REL_ EBCM_PCE SG_ 339 CoPAutoBrkTrqReqRed "0";
BA_REL_ "GenSigSuprvResp" BU_SG_REL_ EBCM_PCE SG_ 339 CoPAutoBrkTrqReqRed 1;
BA_REL_ "GenSigTimeoutMsg" BU_SG_REL_ EBCM_PCE SG_ 339 CoPAutoBrkTrqReqRed 339;
BA_REL_ "GenSigTimeoutTime" BU_SG_REL_ EBCM_PCE SG_ 339 CoPAutoBrkTrqReqRed 25;
BA_REL_ "GenSigRxStartValue" BU_SG_REL_ EBOOST_OBD_PCE SG_ 339 CoPAutoBrkReqTypeRed "0";
BA_REL_ "GenSigSuprvResp" BU_SG_REL_ EBOOST_OBD_PCE SG_ 339 CoPAutoBrkReqTypeRed 1;
BA_REL_ "GenSigTimeoutMsg" BU_SG_REL_ EBOOST_OBD_PCE SG_ 339 CoPAutoBrkReqTypeRed 339;
BA_REL_ "GenSigTimeoutTime" BU_SG_REL_ EBOOST_OBD_PCE SG_ 339 CoPAutoBrkReqTypeRed 25;
BA_REL_ "GenSigRxStartValue" BU_SG_REL_ EBCM_PCE SG_ 339 CoPAutoBrkReqTypeRed "0";
BA_REL_ "GenSigSuprvResp" BU_SG_REL_ EBCM_PCE SG_ 339 CoPAutoBrkReqTypeRed 1;
BA_REL_ "GenSigTimeoutMsg" BU_SG_REL_ EBCM_PCE SG_ 339 CoPAutoBrkReqTypeRed 339;
BA_REL_ "GenSigTimeoutTime" BU_SG_REL_ EBCM_PCE SG_ 339 CoPAutoBrkReqTypeRed 25;
BA_REL_ "GenSigSuprvResp" BU_SG_REL_ SDM_PCE SG_ 201 EngRunAtv 1;
BA_REL_ "GenSigTimeoutMsg" BU_SG_REL_ SDM_PCE SG_ 201 EngRunAtv 201;
BA_REL_ "GenSigTimeoutTime" BU_SG_REL_ SDM_PCE SG_ 201 EngRunAtv 250;
BA_REL_ "GenSigSuprvResp" BU_SG_REL_ SDM_PCE SG_ 530 ABSFld 1;
BA_REL_ "GenSigTimeoutMsg" BU_SG_REL_ SDM_PCE SG_ 530 ABSFld 530;
BA_REL_ "GenSigTimeoutTime" BU_SG_REL_ SDM_PCE SG_ 530 ABSFld 250;
BA_REL_ "GenSigSuprvResp" BU_SG_REL_ SDM_PCE SG_ 530 ABSAtv 1;
BA_REL_ "GenSigTimeoutMsg" BU_SG_REL_ SDM_PCE SG_ 530 ABSAtv 530;
BA_REL_ "GenSigTimeoutTime" BU_SG_REL_ SDM_PCE SG_ 530 ABSAtv 250;
BA_REL_ "GenSigSuprvResp" BU_SG_REL_ EBOOST_OBD_PCE SG_ 530 WhlRotStatTmstmpRes 1;
BA_REL_ "GenSigTimeoutMsg" BU_SG_REL_ EBOOST_OBD_PCE SG_ 530 WhlRotStatTmstmpRes 530;
BA_REL_ "GenSigTimeoutTime" BU_SG_REL_ EBOOST_OBD_PCE SG_ 530 WhlRotStatTmstmpRes 250;
BA_REL_ "GenSigSuprvResp" BU_SG_REL_ EBOOST_OBD_PCE SG_ 530 PrplsnSysAtv 1;
BA_REL_ "GenSigTimeoutMsg" BU_SG_REL_ EBOOST_OBD_PCE SG_ 530 PrplsnSysAtv 530;
BA_REL_ "GenSigTimeoutTime" BU_SG_REL_ EBOOST_OBD_PCE SG_ 530 PrplsnSysAtv 250;
BA_REL_ "GenSigSuprvResp" BU_SG_REL_ EBCM_PCE SG_ 560 RegenBrkAxTrqAch 1;
BA_REL_ "GenSigTimeoutMsg" BU_SG_REL_ EBCM_PCE SG_ 560 RegenBrkAxTrqAch 560;
BA_REL_ "GenSigTimeoutTime" BU_SG_REL_ EBCM_PCE SG_ 560 RegenBrkAxTrqAch 250;
BA_REL_ "GenSigSuprvResp" BU_SG_REL_ EBCM_PCE SG_ 560 RegenBrkAxTorqCap 1;
BA_REL_ "GenSigTimeoutMsg" BU_SG_REL_ EBCM_PCE SG_ 560 RegenBrkAxTorqCap 560;
BA_REL_ "GenSigTimeoutTime" BU_SG_REL_ EBCM_PCE SG_ 560 RegenBrkAxTorqCap 250;
BA_REL_ "GenSigSuprvResp" BU_SG_REL_ SDM_PCE SG_ 832 BrkPedTrvlAchvd 1;
BA_REL_ "GenSigTimeoutMsg" BU_SG_REL_ SDM_PCE SG_ 832 BrkPedTrvlAchvd 832;
BA_REL_ "GenSigTimeoutTime" BU_SG_REL_ SDM_PCE SG_ 832 BrkPedTrvlAchvd 250;
BA_REL_ "GenSigSuprvResp" BU_SG_REL_ SDM_PCE SG_ 832 BrkPedTrvlAchvdV 1;
BA_REL_ "GenSigTimeoutMsg" BU_SG_REL_ SDM_PCE SG_ 832 BrkPedTrvlAchvdV 832;
BA_REL_ "GenSigTimeoutTime" BU_SG_REL_ SDM_PCE SG_ 832 BrkPedTrvlAchvdV 250;
BA_REL_ "GenSigSuprvResp" BU_SG_REL_ EBCM_PCE SG_ 273 DgWhlBrkActvIntfTyp 1;
BA_REL_ "GenSigTimeoutMsg" BU_SG_REL_ EBCM_PCE SG_ 273 DgWhlBrkActvIntfTyp 273;
BA_REL_ "GenSigTimeoutTime" BU_SG_REL_ EBCM_PCE SG_ 273 DgWhlBrkActvIntfTyp 50;
BA_REL_ "GenSigSuprvResp" BU_SG_REL_ EBCM_PCE SG_ 273 DiagWhlBrkPrsReqRR 1;
BA_REL_ "GenSigTimeoutMsg" BU_SG_REL_ EBCM_PCE SG_ 273 DiagWhlBrkPrsReqRR 273;
BA_REL_ "GenSigTimeoutTime" BU_SG_REL_ EBCM_PCE SG_ 273 DiagWhlBrkPrsReqRR 50;
BA_REL_ "GenSigSuprvResp" BU_SG_REL_ EBCM_PCE SG_ 273 DiagWhlBrkPrsReqRF 1;
BA_REL_ "GenSigTimeoutMsg" BU_SG_REL_ EBCM_PCE SG_ 273 DiagWhlBrkPrsReqRF 273;
BA_REL_ "GenSigTimeoutTime" BU_SG_REL_ EBCM_PCE SG_ 273 DiagWhlBrkPrsReqRF 50;
BA_REL_ "GenSigSuprvResp" BU_SG_REL_ EBCM_PCE SG_ 273 DiagWhlBrkPrsReqLR 1;
BA_REL_ "GenSigTimeoutMsg" BU_SG_REL_ EBCM_PCE SG_ 273 DiagWhlBrkPrsReqLR 273;
BA_REL_ "GenSigTimeoutTime" BU_SG_REL_ EBCM_PCE SG_ 273 DiagWhlBrkPrsReqLR 50;
BA_REL_ "GenSigSuprvResp" BU_SG_REL_ EBCM_PCE SG_ 273 DiagWhlBrkPrsReqLF 1;
BA_REL_ "GenSigTimeoutMsg" BU_SG_REL_ EBCM_PCE SG_ 273 DiagWhlBrkPrsReqLF 273;
BA_REL_ "GenSigTimeoutTime" BU_SG_REL_ EBCM_PCE SG_ 273 DiagWhlBrkPrsReqLF 50;
BA_REL_ "GenSigTimeoutMsg" BU_SG_REL_ EBCM_PCE SG_ 273 DiagWhlBrkARC 273;
BA_REL_ "GenSigTimeoutMsg" BU_SG_REL_ EBCM_PCE SG_ 273 DiagWhlBrkChksm 273;
BA_REL_ "GenSigRxStartValue" BU_SG_REL_ EBOOST_OBD_PCE SG_ 508 LonLatAccSnsValARC "0";
BA_REL_ "GenSigRxStartValue" BU_SG_REL_ EBOOST_OBD_PCE SG_ 508 LonLatAccSnsChk "0";
BA_REL_ "GenSigSuprvResp" BU_SG_REL_ EBCM_PCE SG_ 508 LatAccSnsVal 1;
BA_REL_ "GenSigTimeoutMsg" BU_SG_REL_ EBCM_PCE SG_ 508 LatAccSnsVal 508;
BA_REL_ "GenSigTimeoutTime" BU_SG_REL_ EBCM_PCE SG_ 508 LatAccSnsVal 125;
BA_REL_ "GenSigRxStartValue" BU_SG_REL_ EBOOST_OBD_PCE SG_ 508 LatAccSnsVal "0";
BA_REL_ "GenSigSuprvResp" BU_SG_REL_ EBOOST_OBD_PCE SG_ 508 LatAccSnsVal 1;
BA_REL_ "GenSigTimeoutMsg" BU_SG_REL_ EBOOST_OBD_PCE SG_ 508 LatAccSnsVal 508;
BA_REL_ "GenSigTimeoutTime" BU_SG_REL_ EBOOST_OBD_PCE SG_ 508 LatAccSnsVal 125;
BA_REL_ "GenSigSuprvResp" BU_SG_REL_ EBCM_PCE SG_ 508 LonAccSnsVal 1;
BA_REL_ "GenSigTimeoutMsg" BU_SG_REL_ EBCM_PCE SG_ 508 LonAccSnsVal 508;
BA_REL_ "GenSigTimeoutTime" BU_SG_REL_ EBCM_PCE SG_ 508 LonAccSnsVal 125;
BA_REL_ "GenSigRxStartValue" BU_SG_REL_ EBOOST_OBD_PCE SG_ 508 LonAccSnsVal "0";
BA_REL_ "GenSigSuprvResp" BU_SG_REL_ EBOOST_OBD_PCE SG_ 508 LonAccSnsVal 1;
BA_REL_ "GenSigTimeoutMsg" BU_SG_REL_ EBOOST_OBD_PCE SG_ 508 LonAccSnsVal 508;
BA_REL_ "GenSigTimeoutTime" BU_SG_REL_ EBOOST_OBD_PCE SG_ 508 LonAccSnsVal 125;
BA_REL_ "GenSigRxStartValue" BU_SG_REL_ SDM_PCE SG_ 272 ADIMCntrlFailed "False";
BA_REL_ "GenSigSuprvResp" BU_SG_REL_ SDM_PCE SG_ 272 ADIMCntrlFailed 1;
BA_REL_ "GenSigTimeoutMsg" BU_SG_REL_ SDM_PCE SG_ 272 ADIMCntrlFailed 272;
BA_REL_ "GenSigTimeoutTime" BU_SG_REL_ SDM_PCE SG_ 272 ADIMCntrlFailed 25;
BA_REL_ "GenSigRxStartValue" BU_SG_REL_ EOCM2cp_K2_PCE SG_ 272 ADIMCntrlFailed "False";
BA_REL_ "GenSigSuprvResp" BU_SG_REL_ EOCM2cp_K2_PCE SG_ 272 ADIMCntrlFailed 1;
BA_REL_ "GenSigTimeoutMsg" BU_SG_REL_ EOCM2cp_K2_PCE SG_ 272 ADIMCntrlFailed 272;
BA_REL_ "GenSigTimeoutTime" BU_SG_REL_ EOCM2cp_K2_PCE SG_ 272 ADIMCntrlFailed 25;
BA_REL_ "GenSigRxStartValue" BU_SG_REL_ EPSb_PCE SG_ 272 ADIMCntrlFailed "False";
BA_REL_ "GenSigSuprvResp" BU_SG_REL_ EPSb_PCE SG_ 272 ADIMCntrlFailed 1;
BA_REL_ "GenSigTimeoutMsg" BU_SG_REL_ EPSb_PCE SG_ 272 ADIMCntrlFailed 272;
BA_REL_ "GenSigTimeoutTime" BU_SG_REL_ EPSb_PCE SG_ 272 ADIMCntrlFailed 25;
BA_REL_ "GenSigRxStartValue" BU_SG_REL_ EPSa_PCE SG_ 272 ADIMCntrlFailed "False";
BA_REL_ "GenSigSuprvResp" BU_SG_REL_ EPSa_PCE SG_ 272 ADIMCntrlFailed 1;
BA_REL_ "GenSigTimeoutMsg" BU_SG_REL_ EPSa_PCE SG_ 272 ADIMCntrlFailed 272;
BA_REL_ "GenSigTimeoutTime" BU_SG_REL_ EPSa_PCE SG_ 272 ADIMCntrlFailed 25;
BA_REL_ "GenSigRxStartValue" BU_SG_REL_ EBOOST_OBD_PCE SG_ 272 ADIMCntrlFailed "False";
BA_REL_ "GenSigSuprvResp" BU_SG_REL_ EBOOST_OBD_PCE SG_ 272 ADIMCntrlFailed 1;
BA_REL_ "GenSigTimeoutMsg" BU_SG_REL_ EBOOST_OBD_PCE SG_ 272 ADIMCntrlFailed 272;
BA_REL_ "GenSigTimeoutTime" BU_SG_REL_ EBOOST_OBD_PCE SG_ 272 ADIMCntrlFailed 25;
BA_REL_ "GenSigRxStartValue" BU_SG_REL_ EBCM_PCE SG_ 272 ADIMCntrlFailed "False";
BA_REL_ "GenSigSuprvResp" BU_SG_REL_ EBCM_PCE SG_ 272 ADIMCntrlFailed 1;
BA_REL_ "GenSigTimeoutMsg" BU_SG_REL_ EBCM_PCE SG_ 272 ADIMCntrlFailed 272;
BA_REL_ "GenSigTimeoutTime" BU_SG_REL_ EBCM_PCE SG_ 272 ADIMCntrlFailed 25;
BA_REL_ "GenSigSuprvResp" BU_SG_REL_ EBOOST_OBD_PCE SG_ 272 ExtVehCtrlSts 1;
BA_REL_ "GenSigTimeoutMsg" BU_SG_REL_ EBOOST_OBD_PCE SG_ 272 ExtVehCtrlSts 272;
BA_REL_ "GenSigTimeoutTime" BU_SG_REL_ EBOOST_OBD_PCE SG_ 272 ExtVehCtrlSts 250;
BA_REL_ "GenSigSuprvResp" BU_SG_REL_ EBCM_PCE SG_ 272 ExtVehCtrlSts 1;
BA_REL_ "GenSigTimeoutMsg" BU_SG_REL_ EBCM_PCE SG_ 272 ExtVehCtrlSts 272;
BA_REL_ "GenSigTimeoutTime" BU_SG_REL_ EBCM_PCE SG_ 272 ExtVehCtrlSts 250;
BA_REL_ "GenSigRxStartValue" BU_SG_REL_ EPSb_PCE SG_ 272 VehMdMngrSt "0";
BA_REL_ "GenSigSuprvResp" BU_SG_REL_ EPSb_PCE SG_ 272 VehMdMngrSt 1;
BA_REL_ "GenSigTimeoutMsg" BU_SG_REL_ EPSb_PCE SG_ 272 VehMdMngrSt 272;
BA_REL_ "GenSigTimeoutTime" BU_SG_REL_ EPSb_PCE SG_ 272 VehMdMngrSt 25;
BA_REL_ "GenSigRxStartValue" BU_SG_REL_ SDM_PCE SG_ 272 VehMdMngrSt "0";
BA_REL_ "GenSigSuprvResp" BU_SG_REL_ SDM_PCE SG_ 272 VehMdMngrSt 1;
BA_REL_ "GenSigTimeoutMsg" BU_SG_REL_ SDM_PCE SG_ 272 VehMdMngrSt 272;
BA_REL_ "GenSigTimeoutTime" BU_SG_REL_ SDM_PCE SG_ 272 VehMdMngrSt 25;
BA_REL_ "GenSigRxStartValue" BU_SG_REL_ EOCM2cp_K2_PCE SG_ 272 VehMdMngrSt "0";
BA_REL_ "GenSigSuprvResp" BU_SG_REL_ EOCM2cp_K2_PCE SG_ 272 VehMdMngrSt 1;
BA_REL_ "GenSigTimeoutMsg" BU_SG_REL_ EOCM2cp_K2_PCE SG_ 272 VehMdMngrSt 272;
BA_REL_ "GenSigTimeoutTime" BU_SG_REL_ EOCM2cp_K2_PCE SG_ 272 VehMdMngrSt 25;
BA_REL_ "GenSigRxStartValue" BU_SG_REL_ EPSa_PCE SG_ 272 VehMdMngrSt "0";
BA_REL_ "GenSigSuprvResp" BU_SG_REL_ EPSa_PCE SG_ 272 VehMdMngrSt 1;
BA_REL_ "GenSigTimeoutMsg" BU_SG_REL_ EPSa_PCE SG_ 272 VehMdMngrSt 272;
BA_REL_ "GenSigTimeoutTime" BU_SG_REL_ EPSa_PCE SG_ 272 VehMdMngrSt 25;
BA_REL_ "GenSigRxStartValue" BU_SG_REL_ EBOOST_OBD_PCE SG_ 272 VehMdMngrSt "0";
BA_REL_ "GenSigSuprvResp" BU_SG_REL_ EBOOST_OBD_PCE SG_ 272 VehMdMngrSt 1;
BA_REL_ "GenSigTimeoutMsg" BU_SG_REL_ EBOOST_OBD_PCE SG_ 272 VehMdMngrSt 272;
BA_REL_ "GenSigTimeoutTime" BU_SG_REL_ EBOOST_OBD_PCE SG_ 272 VehMdMngrSt 25;
BA_REL_ "GenSigRxStartValue" BU_SG_REL_ EBCM_PCE SG_ 272 VehMdMngrSt "0";
BA_REL_ "GenSigSuprvResp" BU_SG_REL_ EBCM_PCE SG_ 272 VehMdMngrSt 1;
BA_REL_ "GenSigTimeoutMsg" BU_SG_REL_ EBCM_PCE SG_ 272 VehMdMngrSt 272;
BA_REL_ "GenSigTimeoutTime" BU_SG_REL_ EBCM_PCE SG_ 272 VehMdMngrSt 25;
BA_REL_ "GenSigRxStartValue" BU_SG_REL_ EPSb_PCE SG_ 272 EPSWhlAngReqTrgtAng "0";
BA_REL_ "GenSigSuprvResp" BU_SG_REL_ EPSb_PCE SG_ 272 EPSWhlAngReqTrgtAng 1;
BA_REL_ "GenSigTimeoutMsg" BU_SG_REL_ EPSb_PCE SG_ 272 EPSWhlAngReqTrgtAng 272;
BA_REL_ "GenSigTimeoutTime" BU_SG_REL_ EPSb_PCE SG_ 272 EPSWhlAngReqTrgtAng 25;
BA_REL_ "GenSigRxStartValue" BU_SG_REL_ SDM_PCE SG_ 272 EPSWhlAngReqTrgtAng "0";
BA_REL_ "GenSigSuprvResp" BU_SG_REL_ SDM_PCE SG_ 272 EPSWhlAngReqTrgtAng 1;
BA_REL_ "GenSigTimeoutMsg" BU_SG_REL_ SDM_PCE SG_ 272 EPSWhlAngReqTrgtAng 272;
BA_REL_ "GenSigTimeoutTime" BU_SG_REL_ SDM_PCE SG_ 272 EPSWhlAngReqTrgtAng 25;
BA_REL_ "GenSigRxStartValue" BU_SG_REL_ EPSa_PCE SG_ 272 EPSWhlAngReqTrgtAng "0";
BA_REL_ "GenSigSuprvResp" BU_SG_REL_ EPSa_PCE SG_ 272 EPSWhlAngReqTrgtAng 1;
BA_REL_ "GenSigTimeoutMsg" BU_SG_REL_ EPSa_PCE SG_ 272 EPSWhlAngReqTrgtAng 272;
BA_REL_ "GenSigTimeoutTime" BU_SG_REL_ EPSa_PCE SG_ 272 EPSWhlAngReqTrgtAng 25;
BA_REL_ "GenSigRxStartValue" BU_SG_REL_ EBOOST_OBD_PCE SG_ 272 EPSWhlAngReqTrgtAng "0";
BA_REL_ "GenSigSuprvResp" BU_SG_REL_ EBOOST_OBD_PCE SG_ 272 EPSWhlAngReqTrgtAng 1;
BA_REL_ "GenSigTimeoutMsg" BU_SG_REL_ EBOOST_OBD_PCE SG_ 272 EPSWhlAngReqTrgtAng 272;
BA_REL_ "GenSigTimeoutTime" BU_SG_REL_ EBOOST_OBD_PCE SG_ 272 EPSWhlAngReqTrgtAng 25;
BA_REL_ "GenSigRxStartValue" BU_SG_REL_ EBCM_PCE SG_ 272 EPSWhlAngReqTrgtAng "0";
BA_REL_ "GenSigSuprvResp" BU_SG_REL_ EBCM_PCE SG_ 272 EPSWhlAngReqTrgtAng 1;
BA_REL_ "GenSigTimeoutMsg" BU_SG_REL_ EBCM_PCE SG_ 272 EPSWhlAngReqTrgtAng 272;
BA_REL_ "GenSigTimeoutTime" BU_SG_REL_ EBCM_PCE SG_ 272 EPSWhlAngReqTrgtAng 25;
BA_REL_ "GenSigRxStartValue" BU_SG_REL_ EPSb_PCE SG_ 272 AutoEPBReq "0";
BA_REL_ "GenSigSuprvResp" BU_SG_REL_ EPSb_PCE SG_ 272 AutoEPBReq 1;
BA_REL_ "GenSigTimeoutMsg" BU_SG_REL_ EPSb_PCE SG_ 272 AutoEPBReq 272;
BA_REL_ "GenSigTimeoutTime" BU_SG_REL_ EPSb_PCE SG_ 272 AutoEPBReq 25;
BA_REL_ "GenSigRxStartValue" BU_SG_REL_ SDM_PCE SG_ 272 AutoEPBReq "No Request";
BA_REL_ "GenSigSuprvResp" BU_SG_REL_ SDM_PCE SG_ 272 AutoEPBReq 1;
BA_REL_ "GenSigTimeoutMsg" BU_SG_REL_ SDM_PCE SG_ 272 AutoEPBReq 272;
BA_REL_ "GenSigTimeoutTime" BU_SG_REL_ SDM_PCE SG_ 272 AutoEPBReq 25;
BA_REL_ "GenSigRxStartValue" BU_SG_REL_ EPSa_PCE SG_ 272 AutoEPBReq "0";
BA_REL_ "GenSigSuprvResp" BU_SG_REL_ EPSa_PCE SG_ 272 AutoEPBReq 1;
BA_REL_ "GenSigTimeoutMsg" BU_SG_REL_ EPSa_PCE SG_ 272 AutoEPBReq 272;
BA_REL_ "GenSigTimeoutTime" BU_SG_REL_ EPSa_PCE SG_ 272 AutoEPBReq 25;
BA_REL_ "GenSigRxStartValue" BU_SG_REL_ EBOOST_OBD_PCE SG_ 272 AutoEPBReq "0";
BA_REL_ "GenSigSuprvResp" BU_SG_REL_ EBOOST_OBD_PCE SG_ 272 AutoEPBReq 1;
BA_REL_ "GenSigTimeoutMsg" BU_SG_REL_ EBOOST_OBD_PCE SG_ 272 AutoEPBReq 272;
BA_REL_ "GenSigTimeoutTime" BU_SG_REL_ EBOOST_OBD_PCE SG_ 272 AutoEPBReq 25;
BA_REL_ "GenSigRxStartValue" BU_SG_REL_ EBCM_PCE SG_ 272 AutoEPBReq "0";
BA_REL_ "GenSigSuprvResp" BU_SG_REL_ EBCM_PCE SG_ 272 AutoEPBReq 1;
BA_REL_ "GenSigTimeoutMsg" BU_SG_REL_ EBCM_PCE SG_ 272 AutoEPBReq 272;
BA_REL_ "GenSigTimeoutTime" BU_SG_REL_ EBCM_PCE SG_ 272 AutoEPBReq 25;
BA_REL_ "GenSigSuprvResp" BU_SG_REL_ EBCM_PCE SG_ 272 AutoBrkSysRdcPerDet 1;
BA_REL_ "GenSigTimeoutMsg" BU_SG_REL_ EBCM_PCE SG_ 272 AutoBrkSysRdcPerDet 272;
BA_REL_ "GenSigTimeoutTime" BU_SG_REL_ EBCM_PCE SG_ 272 AutoBrkSysRdcPerDet 250;
BA_REL_ "GenSigSuprvResp" BU_SG_REL_ EBOOST_OBD_PCE SG_ 272 AutoBrkSysRdcPerDet 1;
BA_REL_ "GenSigTimeoutMsg" BU_SG_REL_ EBOOST_OBD_PCE SG_ 272 AutoBrkSysRdcPerDet 272;
BA_REL_ "GenSigTimeoutTime" BU_SG_REL_ EBOOST_OBD_PCE SG_ 272 AutoBrkSysRdcPerDet 250;
BA_REL_ "GenSigRxStartValue" BU_SG_REL_ EPSb_PCE SG_ 272 AutoBrkaStrgReqChksm "0";
BA_REL_ "GenSigRxStartValue" BU_SG_REL_ SDM_PCE SG_ 272 AutoBrkaStrgReqChksm "0";
BA_REL_ "GenSigRxStartValue" BU_SG_REL_ EPSa_PCE SG_ 272 AutoBrkaStrgReqChksm "0";
BA_REL_ "GenSigRxStartValue" BU_SG_REL_ EBOOST_OBD_PCE SG_ 272 AutoBrkaStrgReqChksm "0";
BA_REL_ "GenSigRxStartValue" BU_SG_REL_ EBCM_PCE SG_ 272 AutoBrkaStrgReqChksm "0";
BA_REL_ "GenSigRxStartValue" BU_SG_REL_ EPSb_PCE SG_ 272 AutoBrkaStrgReqARC "0";
BA_REL_ "GenSigRxStartValue" BU_SG_REL_ SDM_PCE SG_ 272 AutoBrkaStrgReqARC "0";
BA_REL_ "GenSigRxStartValue" BU_SG_REL_ EPSa_PCE SG_ 272 AutoBrkaStrgReqARC "0";
BA_REL_ "GenSigRxStartValue" BU_SG_REL_ EBOOST_OBD_PCE SG_ 272 AutoBrkaStrgReqARC "0";
BA_REL_ "GenSigRxStartValue" BU_SG_REL_ EBCM_PCE SG_ 272 AutoBrkaStrgReqARC "0";
BA_REL_ "GenSigRxStartValue" BU_SG_REL_ EPSb_PCE SG_ 272 AutoBrkTrqReq "0";
BA_REL_ "GenSigSuprvResp" BU_SG_REL_ EPSb_PCE SG_ 272 AutoBrkTrqReq 1;
BA_REL_ "GenSigTimeoutMsg" BU_SG_REL_ EPSb_PCE SG_ 272 AutoBrkTrqReq 272;
BA_REL_ "GenSigTimeoutTime" BU_SG_REL_ EPSb_PCE SG_ 272 AutoBrkTrqReq 25;
BA_REL_ "GenSigRxStartValue" BU_SG_REL_ SDM_PCE SG_ 272 AutoBrkTrqReq "0";
BA_REL_ "GenSigSuprvResp" BU_SG_REL_ SDM_PCE SG_ 272 AutoBrkTrqReq 1;
BA_REL_ "GenSigTimeoutMsg" BU_SG_REL_ SDM_PCE SG_ 272 AutoBrkTrqReq 272;
BA_REL_ "GenSigTimeoutTime" BU_SG_REL_ SDM_PCE SG_ 272 AutoBrkTrqReq 25;
BA_REL_ "GenSigRxStartValue" BU_SG_REL_ EPSa_PCE SG_ 272 AutoBrkTrqReq "0";
BA_REL_ "GenSigSuprvResp" BU_SG_REL_ EPSa_PCE SG_ 272 AutoBrkTrqReq 1;
BA_REL_ "GenSigTimeoutMsg" BU_SG_REL_ EPSa_PCE SG_ 272 AutoBrkTrqReq 272;
BA_REL_ "GenSigTimeoutTime" BU_SG_REL_ EPSa_PCE SG_ 272 AutoBrkTrqReq 25;
BA_REL_ "GenSigRxStartValue" BU_SG_REL_ EBOOST_OBD_PCE SG_ 272 AutoBrkTrqReq "0";
BA_REL_ "GenSigSuprvResp" BU_SG_REL_ EBOOST_OBD_PCE SG_ 272 AutoBrkTrqReq 1;
BA_REL_ "GenSigTimeoutMsg" BU_SG_REL_ EBOOST_OBD_PCE SG_ 272 AutoBrkTrqReq 272;
BA_REL_ "GenSigTimeoutTime" BU_SG_REL_ EBOOST_OBD_PCE SG_ 272 AutoBrkTrqReq 25;
BA_REL_ "GenSigRxStartValue" BU_SG_REL_ EBCM_PCE SG_ 272 AutoBrkTrqReq "0";
BA_REL_ "GenSigSuprvResp" BU_SG_REL_ EBCM_PCE SG_ 272 AutoBrkTrqReq 1;
BA_REL_ "GenSigTimeoutMsg" BU_SG_REL_ EBCM_PCE SG_ 272 AutoBrkTrqReq 272;
BA_REL_ "GenSigTimeoutTime" BU_SG_REL_ EBCM_PCE SG_ 272 AutoBrkTrqReq 25;
BA_REL_ "GenSigRxStartValue" BU_SG_REL_ EPSb_PCE SG_ 272 AutoBrkReqType "0";
BA_REL_ "GenSigSuprvResp" BU_SG_REL_ EPSb_PCE SG_ 272 AutoBrkReqType 1;
BA_REL_ "GenSigTimeoutMsg" BU_SG_REL_ EPSb_PCE SG_ 272 AutoBrkReqType 272;
BA_REL_ "GenSigTimeoutTime" BU_SG_REL_ EPSb_PCE SG_ 272 AutoBrkReqType 25;
BA_REL_ "GenSigRxStartValue" BU_SG_REL_ SDM_PCE SG_ 272 AutoBrkReqType "No Request";
BA_REL_ "GenSigSuprvResp" BU_SG_REL_ SDM_PCE SG_ 272 AutoBrkReqType 1;
BA_REL_ "GenSigTimeoutMsg" BU_SG_REL_ SDM_PCE SG_ 272 AutoBrkReqType 272;
BA_REL_ "GenSigTimeoutTime" BU_SG_REL_ SDM_PCE SG_ 272 AutoBrkReqType 25;
BA_REL_ "GenSigRxStartValue" BU_SG_REL_ EPSa_PCE SG_ 272 AutoBrkReqType "0";
BA_REL_ "GenSigSuprvResp" BU_SG_REL_ EPSa_PCE SG_ 272 AutoBrkReqType 1;
BA_REL_ "GenSigTimeoutMsg" BU_SG_REL_ EPSa_PCE SG_ 272 AutoBrkReqType 272;
BA_REL_ "GenSigTimeoutTime" BU_SG_REL_ EPSa_PCE SG_ 272 AutoBrkReqType 25;
BA_REL_ "GenSigRxStartValue" BU_SG_REL_ EBOOST_OBD_PCE SG_ 272 AutoBrkReqType "0";
BA_REL_ "GenSigSuprvResp" BU_SG_REL_ EBOOST_OBD_PCE SG_ 272 AutoBrkReqType 1;
BA_REL_ "GenSigTimeoutMsg" BU_SG_REL_ EBOOST_OBD_PCE SG_ 272 AutoBrkReqType 272;
BA_REL_ "GenSigTimeoutTime" BU_SG_REL_ EBOOST_OBD_PCE SG_ 272 AutoBrkReqType 25;
BA_REL_ "GenSigRxStartValue" BU_SG_REL_ EBCM_PCE SG_ 272 AutoBrkReqType "0";
BA_REL_ "GenSigSuprvResp" BU_SG_REL_ EBCM_PCE SG_ 272 AutoBrkReqType 1;
BA_REL_ "GenSigTimeoutMsg" BU_SG_REL_ EBCM_PCE SG_ 272 AutoBrkReqType 272;
BA_REL_ "GenSigTimeoutTime" BU_SG_REL_ EBCM_PCE SG_ 272 AutoBrkReqType 25;
BA_REL_ "GenSigRxStartValue" BU_SG_REL_ EBCM_PCE SG_ 320 IMULonAccPriV "Valid";
BA_REL_ "GenSigRxStartValue" BU_SG_REL_ EBOOST_OBD_PCE SG_ 320 IMULonAccPriV "Valid";
BA_REL_ "GenSigVBitResp" BU_SG_REL_ EOCM2cp_K2_PCE SG_ 320 IMULonAccPri 1;
BA_REL_ "GenSigVBitResp" BU_SG_REL_ EBCM_PCE SG_ 320 IMULonAccPri 1;
BA_REL_ "GenSigRxStartValue" BU_SG_REL_ EBCM_PCE SG_ 320 IMULonAccPri "0";
BA_REL_ "GenSigSuprvResp" BU_SG_REL_ EBCM_PCE SG_ 320 IMULonAccPri 1;
BA_REL_ "GenSigTimeoutTime" BU_SG_REL_ EBCM_PCE SG_ 320 IMULonAccPri 100;
BA_REL_ "GenSigSuprvResp" BU_SG_REL_ EBCM_PCE SG_ 320 IMULonAccPri 1;
BA_REL_ "GenSigTimeoutMsg" BU_SG_REL_ EBCM_PCE SG_ 320 IMULonAccPri 320;
BA_REL_ "GenSigTimeoutTime" BU_SG_REL_ EBCM_PCE SG_ 320 IMULonAccPri 100;
BA_REL_ "GenSigSuprvResp" BU_SG_REL_ EBCM_PCE SG_ 320 IMULonAccPri 1;
BA_REL_ "GenSigTimeoutTime" BU_SG_REL_ EBCM_PCE SG_ 320 IMULonAccPri 100;
BA_REL_ "GenSigVBitResp" BU_SG_REL_ EBOOST_OBD_PCE SG_ 320 IMULonAccPri 1;
BA_REL_ "GenSigRxStartValue" BU_SG_REL_ EBOOST_OBD_PCE SG_ 320 IMULonAccPri "0";
BA_REL_ "GenSigSuprvResp" BU_SG_REL_ EBOOST_OBD_PCE SG_ 320 IMULonAccPri 1;
BA_REL_ "GenSigTimeoutMsg" BU_SG_REL_ EBOOST_OBD_PCE SG_ 320 IMULonAccPri 320;
BA_REL_ "GenSigTimeoutTime" BU_SG_REL_ EBOOST_OBD_PCE SG_ 320 IMULonAccPri 100;
BA_REL_ "GenSigRxStartValue" BU_SG_REL_ EBCM_PCE SG_ 320 IMUXAxisClbrtd "Not Calibrated";
BA_REL_ "GenSigSuprvResp" BU_SG_REL_ EBCM_PCE SG_ 320 IMUXAxisClbrtd 1;
BA_REL_ "GenSigTimeoutTime" BU_SG_REL_ EBCM_PCE SG_ 320 IMUXAxisClbrtd 100;
BA_REL_ "GenSigRxStartValue" BU_SG_REL_ EBOOST_OBD_PCE SG_ 320 IMUXAxisClbrtd "Not Calibrated";
BA_REL_ "GenSigRxStartValue" BU_SG_REL_ EBCM_PCE SG_ 320 IMUXAxisOrntn "Connector Forward";
BA_REL_ "GenSigSuprvResp" BU_SG_REL_ EBCM_PCE SG_ 320 IMUXAxisOrntn 1;
BA_REL_ "GenSigTimeoutTime" BU_SG_REL_ EBCM_PCE SG_ 320 IMUXAxisOrntn 100;
BA_REL_ "GenSigRxStartValue" BU_SG_REL_ EBOOST_OBD_PCE SG_ 320 IMUXAxisOrntn "Connector Forward";
BA_REL_ "GenSigRxStartValue" BU_SG_REL_ EBCM_PCE SG_ 320 IMUPriYawDrftTyp "Base";
BA_REL_ "GenSigSuprvResp" BU_SG_REL_ EBCM_PCE SG_ 320 IMUPriYawDrftTyp 1;
BA_REL_ "GenSigTimeoutTime" BU_SG_REL_ EBCM_PCE SG_ 320 IMUPriYawDrftTyp 100;
BA_REL_ "GenSigRxStartValue" BU_SG_REL_ EBOOST_OBD_PCE SG_ 320 IMUPriYawDrftTyp "Base";
BA_REL_ "GenSigRxStartValue" BU_SG_REL_ EBCM_PCE SG_ 320 IMUDataMsk "Don't Use Data";
BA_REL_ "GenSigRxStartValue" BU_SG_REL_ EBOOST_OBD_PCE SG_ 320 IMUDataMsk "Don't Use Data";
BA_REL_ "GenSigRxStartValue" BU_SG_REL_ EBOOST_OBD_PCE SG_ 320 IMUChksumSec "0";
BA_REL_ "GenSigRxStartValue" BU_SG_REL_ EBCM_PCE SG_ 320 IMUChksumSec "0";
BA_REL_ "GenSigRxStartValue" BU_SG_REL_ EBOOST_OBD_PCE SG_ 320 IMUYawRtSecAval "False";
BA_REL_ "GenSigRxStartValue" BU_SG_REL_ EBCM_PCE SG_ 320 IMUYawRtSecAval "False";
BA_REL_ "GenSigSuprvResp" BU_SG_REL_ EBCM_PCE SG_ 320 IMUYawRtSecAval 1;
BA_REL_ "GenSigTimeoutTime" BU_SG_REL_ EBCM_PCE SG_ 320 IMUYawRtSecAval 100;
BA_REL_ "GenSigRxStartValue" BU_SG_REL_ EBOOST_OBD_PCE SG_ 320 IMULatAccSecAval "False";
BA_REL_ "GenSigRxStartValue" BU_SG_REL_ EBCM_PCE SG_ 320 IMULatAccSecAval "False";
BA_REL_ "GenSigRxStartValue" BU_SG_REL_ EBOOST_OBD_PCE SG_ 320 IMURollCntSec "0";
BA_REL_ "GenSigRxStartValue" BU_SG_REL_ EBCM_PCE SG_ 320 IMURollCntSec "0";
BA_REL_ "GenSigSuprvResp" BU_SG_REL_ EBCM_PCE SG_ 320 IMURollCntSec 1;
BA_REL_ "GenSigTimeoutTime" BU_SG_REL_ EBCM_PCE SG_ 320 IMURollCntSec 100;
BA_REL_ "GenSigRxStartValue" BU_SG_REL_ EBOOST_OBD_PCE SG_ 320 IMUYawRtSecV "Valid";
BA_REL_ "GenSigRxStartValue" BU_SG_REL_ EBCM_PCE SG_ 320 IMUYawRtSecV "Valid";
BA_REL_ "GenSigVBitResp" BU_SG_REL_ EOCM2cp_K2_PCE SG_ 320 IMUYawRtSec 1;
BA_REL_ "GenSigVBitResp" BU_SG_REL_ EBOOST_OBD_PCE SG_ 320 IMUYawRtSec 1;
BA_REL_ "GenSigRxStartValue" BU_SG_REL_ EBOOST_OBD_PCE SG_ 320 IMUYawRtSec "0";
BA_REL_ "GenSigVBitResp" BU_SG_REL_ EBCM_PCE SG_ 320 IMUYawRtSec 1;
BA_REL_ "GenSigRxStartValue" BU_SG_REL_ EBCM_PCE SG_ 320 IMUYawRtSec "0";
BA_REL_ "GenSigSuprvResp" BU_SG_REL_ EBCM_PCE SG_ 320 IMUYawRtSec 1;
BA_REL_ "GenSigTimeoutTime" BU_SG_REL_ EBCM_PCE SG_ 320 IMUYawRtSec 100;
BA_REL_ "GenSigRxStartValue" BU_SG_REL_ EBOOST_OBD_PCE SG_ 320 IMULatACCSecV "Valid";
BA_REL_ "GenSigRxStartValue" BU_SG_REL_ EBCM_PCE SG_ 320 IMULatACCSecV "Valid";
BA_REL_ "GenSigVBitResp" BU_SG_REL_ EOCM2cp_K2_PCE SG_ 320 IMULatACCSec 1;
BA_REL_ "GenSigVBitResp" BU_SG_REL_ EBOOST_OBD_PCE SG_ 320 IMULatACCSec 1;
BA_REL_ "GenSigRxStartValue" BU_SG_REL_ EBOOST_OBD_PCE SG_ 320 IMULatACCSec "0";
BA_REL_ "GenSigSuprvResp" BU_SG_REL_ EBOOST_OBD_PCE SG_ 320 IMULatACCSec 1;
BA_REL_ "GenSigTimeoutMsg" BU_SG_REL_ EBOOST_OBD_PCE SG_ 320 IMULatACCSec 320;
BA_REL_ "GenSigTimeoutTime" BU_SG_REL_ EBOOST_OBD_PCE SG_ 320 IMULatACCSec 100;
BA_REL_ "GenSigVBitResp" BU_SG_REL_ EBCM_PCE SG_ 320 IMULatACCSec 1;
BA_REL_ "GenSigRxStartValue" BU_SG_REL_ EBCM_PCE SG_ 320 IMULatACCSec "0";
BA_REL_ "GenSigSuprvResp" BU_SG_REL_ EBCM_PCE SG_ 320 IMULatACCSec 1;
BA_REL_ "GenSigTimeoutMsg" BU_SG_REL_ EBCM_PCE SG_ 320 IMULatACCSec 320;
BA_REL_ "GenSigTimeoutTime" BU_SG_REL_ EBCM_PCE SG_ 320 IMULatACCSec 100;
BA_REL_ "GenSigSuprvResp" BU_SG_REL_ EBCM_PCE SG_ 304 IMULonAccPriAval 1;
BA_REL_ "GenSigTimeoutTime" BU_SG_REL_ EBCM_PCE SG_ 304 IMULonAccPriAval 100;
BA_REL_ "GenSigRxStartValue" BU_SG_REL_ EBCM_PCE SG_ 304 IMULonAccPriAval "False";
BA_REL_ "GenSigSuprvResp" BU_SG_REL_ EBCM_PCE SG_ 304 IMULonAccPriAval 1;
BA_REL_ "GenSigTimeoutTime" BU_SG_REL_ EBCM_PCE SG_ 304 IMULonAccPriAval 100;
BA_REL_ "GenSigRxStartValue" BU_SG_REL_ EBOOST_OBD_PCE SG_ 304 IMULonAccPriAval "False";
BA_REL_ "GenSigRxStartValue" BU_SG_REL_ EBCM_PCE SG_ 304 IMULonAccSecAval "False";
BA_REL_ "GenSigSuprvResp" BU_SG_REL_ EBCM_PCE SG_ 304 IMULonAccSecAval 1;
BA_REL_ "GenSigTimeoutTime" BU_SG_REL_ EBCM_PCE SG_ 304 IMULonAccSecAval 100;
BA_REL_ "GenSigRxStartValue" BU_SG_REL_ EBOOST_OBD_PCE SG_ 304 IMULonAccSecAval "False";
BA_REL_ "GenSigRxStartValue" BU_SG_REL_ EBCM_PCE SG_ 304 IMULonAccSecV "Valid";
BA_REL_ "GenSigRxStartValue" BU_SG_REL_ EBOOST_OBD_PCE SG_ 304 IMULonAccSecV "Valid";
BA_REL_ "GenSigRxStartValue" BU_SG_REL_ EBCM_PCE SG_ 304 IMUYawRtAccPriSecure "0";
BA_REL_ "GenSigSuprvResp" BU_SG_REL_ EBCM_PCE SG_ 304 IMUYawRtAccPriSecure 1;
BA_REL_ "GenSigTimeoutTime" BU_SG_REL_ EBCM_PCE SG_ 304 IMUYawRtAccPriSecure 100;
BA_REL_ "GenSigSuprvResp" BU_SG_REL_ EBCM_PCE SG_ 304 IMUYawRtAccPriSecure 1;
BA_REL_ "GenSigTimeoutTime" BU_SG_REL_ EBCM_PCE SG_ 304 IMUYawRtAccPriSecure 100;
BA_REL_ "GenSigRxStartValue" BU_SG_REL_ EBOOST_OBD_PCE SG_ 304 IMUYawRtAccPriSecure "0";
BA_REL_ "GenSigRxStartValue" BU_SG_REL_ EBOOST_OBD_PCE SG_ 304 IMUYawRtPriV "Valid";
BA_REL_ "GenSigRxStartValue" BU_SG_REL_ EBCM_PCE SG_ 304 IMUYawRtPriV "Valid";
BA_REL_ "GenSigVBitResp" BU_SG_REL_ EOCM2cp_K2_PCE SG_ 304 IMUYawRtPri 1;
BA_REL_ "GenSigVBitResp" BU_SG_REL_ EBOOST_OBD_PCE SG_ 304 IMUYawRtPri 1;
BA_REL_ "GenSigRxStartValue" BU_SG_REL_ EBOOST_OBD_PCE SG_ 304 IMUYawRtPri "0";
BA_REL_ "GenSigVBitResp" BU_SG_REL_ EBCM_PCE SG_ 304 IMUYawRtPri 1;
BA_REL_ "GenSigRxStartValue" BU_SG_REL_ EBCM_PCE SG_ 304 IMUYawRtPri "0";
BA_REL_ "GenSigSuprvResp" BU_SG_REL_ EBCM_PCE SG_ 304 IMUYawRtPri 1;
BA_REL_ "GenSigTimeoutTime" BU_SG_REL_ EBCM_PCE SG_ 304 IMUYawRtPri 100;
BA_REL_ "GenSigRxStartValue" BU_SG_REL_ EBOOST_OBD_PCE SG_ 304 IMURollCntPri "0";
BA_REL_ "GenSigRxStartValue" BU_SG_REL_ EBCM_PCE SG_ 304 IMURollCntPri "0";
BA_REL_ "GenSigSuprvResp" BU_SG_REL_ EBCM_PCE SG_ 304 IMURollCntPri 1;
BA_REL_ "GenSigTimeoutTime" BU_SG_REL_ EBCM_PCE SG_ 304 IMURollCntPri 100;
BA_REL_ "GenSigRxStartValue" BU_SG_REL_ EBOOST_OBD_PCE SG_ 304 IMUChksumPri "0";
BA_REL_ "GenSigRxStartValue" BU_SG_REL_ EBCM_PCE SG_ 304 IMUChksumPri "0";
BA_REL_ "GenSigVBitResp" BU_SG_REL_ EOCM2cp_K2_PCE SG_ 304 IMULonAccSec 1;
BA_REL_ "GenSigVBitResp" BU_SG_REL_ EBCM_PCE SG_ 304 IMULonAccSec 1;
BA_REL_ "GenSigRxStartValue" BU_SG_REL_ EBCM_PCE SG_ 304 IMULonAccSec "0";
BA_REL_ "GenSigSuprvResp" BU_SG_REL_ EBCM_PCE SG_ 304 IMULonAccSec 1;
BA_REL_ "GenSigTimeoutTime" BU_SG_REL_ EBCM_PCE SG_ 304 IMULonAccSec 100;
BA_REL_ "GenSigVBitResp" BU_SG_REL_ EBOOST_OBD_PCE SG_ 304 IMULonAccSec 1;
BA_REL_ "GenSigRxStartValue" BU_SG_REL_ EBOOST_OBD_PCE SG_ 304 IMULonAccSec "0";
BA_REL_ "GenSigVBitResp" BU_SG_REL_ EOCM2cp_K2_PCE SG_ 304 IMULatAccPrim 1;
BA_REL_ "GenSigVBitResp" BU_SG_REL_ EBOOST_OBD_PCE SG_ 304 IMULatAccPrim 1;
BA_REL_ "GenSigRxStartValue" BU_SG_REL_ EBOOST_OBD_PCE SG_ 304 IMULatAccPrim "0";
BA_REL_ "GenSigSuprvResp" BU_SG_REL_ EBOOST_OBD_PCE SG_ 304 IMULatAccPrim 1;
BA_REL_ "GenSigTimeoutMsg" BU_SG_REL_ EBOOST_OBD_PCE SG_ 304 IMULatAccPrim 304;
BA_REL_ "GenSigTimeoutTime" BU_SG_REL_ EBOOST_OBD_PCE SG_ 304 IMULatAccPrim 100;
BA_REL_ "GenSigVBitResp" BU_SG_REL_ EBCM_PCE SG_ 304 IMULatAccPrim 1;
BA_REL_ "GenSigRxStartValue" BU_SG_REL_ EBCM_PCE SG_ 304 IMULatAccPrim "0";
BA_REL_ "GenSigSuprvResp" BU_SG_REL_ EBCM_PCE SG_ 304 IMULatAccPrim 1;
BA_REL_ "GenSigTimeoutMsg" BU_SG_REL_ EBCM_PCE SG_ 304 IMULatAccPrim 304;
BA_REL_ "GenSigTimeoutTime" BU_SG_REL_ EBCM_PCE SG_ 304 IMULatAccPrim 100;
BA_REL_ "GenSigRxStartValue" BU_SG_REL_ EBOOST_OBD_PCE SG_ 304 IMULatAccPrimV "Valid";
BA_REL_ "GenSigRxStartValue" BU_SG_REL_ EBCM_PCE SG_ 304 IMULatAccPrimV "Valid";
BA_REL_ "GenSigRxStartValue" BU_SG_REL_ EPSb_PCE SG_ 840 DrvnWhlGrndVelChksm "0";
BA_REL_ "GenSigRxStartValue" BU_SG_REL_ EPSa_PCE SG_ 840 DrvnWhlGrndVelChksm "0";
BA_REL_ "GenSigRxStartValue" BU_SG_REL_ EBOOST_OBD_PCE SG_ 840 DrvnWhlGrndVelChksm "0";
BA_REL_ "GenSigRxStartValue" BU_SG_REL_ EBOOST_OBD_PCE SG_ 840 WhlRotDrctnlStRtDrvn "Unknown";
BA_REL_ "GenSigSuprvResp" BU_SG_REL_ EBOOST_OBD_PCE SG_ 840 WhlRotDrctnlStRtDrvn 1;
BA_REL_ "GenSigTimeoutMsg" BU_SG_REL_ EBOOST_OBD_PCE SG_ 840 WhlRotDrctnlStRtDrvn 840;
BA_REL_ "GenSigTimeoutTime" BU_SG_REL_ EBOOST_OBD_PCE SG_ 840 WhlRotDrctnlStRtDrvn 125;
BA_REL_ "GenSigRxStartValue" BU_SG_REL_ EBOOST_OBD_PCE SG_ 840 WhlRotDrctnlStLftDrvn "Unknown";
BA_REL_ "GenSigSuprvResp" BU_SG_REL_ EBOOST_OBD_PCE SG_ 840 WhlRotDrctnlStLftDrvn 1;
BA_REL_ "GenSigTimeoutMsg" BU_SG_REL_ EBOOST_OBD_PCE SG_ 840 WhlRotDrctnlStLftDrvn 840;
BA_REL_ "GenSigTimeoutTime" BU_SG_REL_ EBOOST_OBD_PCE SG_ 840 WhlRotDrctnlStLftDrvn 125;
BA_REL_ "GenSigRxStartValue" BU_SG_REL_ EBOOST_OBD_PCE SG_ 840 WhlPlsPerRevDrvn "0";
BA_REL_ "GenSigSuprvResp" BU_SG_REL_ EBOOST_OBD_PCE SG_ 840 WhlPlsPerRevDrvn 1;
BA_REL_ "GenSigTimeoutMsg" BU_SG_REL_ EBOOST_OBD_PCE SG_ 840 WhlPlsPerRevDrvn 840;
BA_REL_ "GenSigTimeoutTime" BU_SG_REL_ EBOOST_OBD_PCE SG_ 840 WhlPlsPerRevDrvn 125;
BA_REL_ "GenSigSuprvResp" BU_SG_REL_ EPSb_PCE SG_ 840 WhlPlsPerRevDrvn 1;
BA_REL_ "GenSigTimeoutMsg" BU_SG_REL_ EPSb_PCE SG_ 840 WhlPlsPerRevDrvn 840;
BA_REL_ "GenSigTimeoutTime" BU_SG_REL_ EPSb_PCE SG_ 840 WhlPlsPerRevDrvn 250;
BA_REL_ "GenSigSuprvResp" BU_SG_REL_ EPSa_PCE SG_ 840 WhlPlsPerRevDrvn 1;
BA_REL_ "GenSigTimeoutMsg" BU_SG_REL_ EPSa_PCE SG_ 840 WhlPlsPerRevDrvn 840;
BA_REL_ "GenSigTimeoutTime" BU_SG_REL_ EPSa_PCE SG_ 840 WhlPlsPerRevDrvn 250;
BA_REL_ "GenSigRxStartValue" BU_SG_REL_ EBOOST_OBD_PCE SG_ 840 WhlGrndVlctyRtDrvnV "Valid";
BA_REL_ "GenSigVBitResp" BU_SG_REL_ EBOOST_OBD_PCE SG_ 840 WhlGrndVlctyRtDrvn 1;
BA_REL_ "GenSigRxStartValue" BU_SG_REL_ EBOOST_OBD_PCE SG_ 840 WhlGrndVlctyRtDrvn "0";
BA_REL_ "GenSigSuprvResp" BU_SG_REL_ EBOOST_OBD_PCE SG_ 840 WhlGrndVlctyRtDrvn 1;
BA_REL_ "GenSigTimeoutMsg" BU_SG_REL_ EBOOST_OBD_PCE SG_ 840 WhlGrndVlctyRtDrvn 840;
BA_REL_ "GenSigTimeoutTime" BU_SG_REL_ EBOOST_OBD_PCE SG_ 840 WhlGrndVlctyRtDrvn 125;
BA_REL_ "GenSigVBitResp" BU_SG_REL_ SDM_PCE SG_ 840 WhlGrndVlctyRtDrvn 1;
BA_REL_ "GenSigSuprvResp" BU_SG_REL_ SDM_PCE SG_ 840 WhlGrndVlctyRtDrvn 1;
BA_REL_ "GenSigTimeoutTime" BU_SG_REL_ SDM_PCE SG_ 840 WhlGrndVlctyRtDrvn 250;
BA_REL_ "GenSigVBitResp" BU_SG_REL_ EPSb_PCE SG_ 840 WhlGrndVlctyRtDrvn 1;
BA_REL_ "GenSigSuprvResp" BU_SG_REL_ EPSb_PCE SG_ 840 WhlGrndVlctyRtDrvn 1;
BA_REL_ "GenSigTimeoutMsg" BU_SG_REL_ EPSb_PCE SG_ 840 WhlGrndVlctyRtDrvn 840;
BA_REL_ "GenSigTimeoutTime" BU_SG_REL_ EPSb_PCE SG_ 840 WhlGrndVlctyRtDrvn 250;
BA_REL_ "GenSigVBitResp" BU_SG_REL_ EPSa_PCE SG_ 840 WhlGrndVlctyRtDrvn 1;
BA_REL_ "GenSigSuprvResp" BU_SG_REL_ EPSa_PCE SG_ 840 WhlGrndVlctyRtDrvn 1;
BA_REL_ "GenSigTimeoutMsg" BU_SG_REL_ EPSa_PCE SG_ 840 WhlGrndVlctyRtDrvn 840;
BA_REL_ "GenSigTimeoutTime" BU_SG_REL_ EPSa_PCE SG_ 840 WhlGrndVlctyRtDrvn 250;
BA_REL_ "GenSigRxStartValue" BU_SG_REL_ EBOOST_OBD_PCE SG_ 840 WhlGrndVlctyLftDrvnV "Valid";
BA_REL_ "GenSigVBitResp" BU_SG_REL_ EBOOST_OBD_PCE SG_ 840 WhlGrndVlctyLftDrvn 1;
BA_REL_ "GenSigRxStartValue" BU_SG_REL_ EBOOST_OBD_PCE SG_ 840 WhlGrndVlctyLftDrvn "0";
BA_REL_ "GenSigSuprvResp" BU_SG_REL_ EBOOST_OBD_PCE SG_ 840 WhlGrndVlctyLftDrvn 1;
BA_REL_ "GenSigTimeoutMsg" BU_SG_REL_ EBOOST_OBD_PCE SG_ 840 WhlGrndVlctyLftDrvn 840;
BA_REL_ "GenSigTimeoutTime" BU_SG_REL_ EBOOST_OBD_PCE SG_ 840 WhlGrndVlctyLftDrvn 125;
BA_REL_ "GenSigVBitResp" BU_SG_REL_ SDM_PCE SG_ 840 WhlGrndVlctyLftDrvn 1;
BA_REL_ "GenSigSuprvResp" BU_SG_REL_ SDM_PCE SG_ 840 WhlGrndVlctyLftDrvn 1;
BA_REL_ "GenSigTimeoutMsg" BU_SG_REL_ SDM_PCE SG_ 840 WhlGrndVlctyLftDrvn 840;
BA_REL_ "GenSigTimeoutTime" BU_SG_REL_ SDM_PCE SG_ 840 WhlGrndVlctyLftDrvn 250;
BA_REL_ "GenSigVBitResp" BU_SG_REL_ EPSb_PCE SG_ 840 WhlGrndVlctyLftDrvn 1;
BA_REL_ "GenSigSuprvResp" BU_SG_REL_ EPSb_PCE SG_ 840 WhlGrndVlctyLftDrvn 1;
BA_REL_ "GenSigTimeoutMsg" BU_SG_REL_ EPSb_PCE SG_ 840 WhlGrndVlctyLftDrvn 840;
BA_REL_ "GenSigTimeoutTime" BU_SG_REL_ EPSb_PCE SG_ 840 WhlGrndVlctyLftDrvn 250;
BA_REL_ "GenSigVBitResp" BU_SG_REL_ EPSa_PCE SG_ 840 WhlGrndVlctyLftDrvn 1;
BA_REL_ "GenSigSuprvResp" BU_SG_REL_ EPSa_PCE SG_ 840 WhlGrndVlctyLftDrvn 1;
BA_REL_ "GenSigTimeoutMsg" BU_SG_REL_ EPSa_PCE SG_ 840 WhlGrndVlctyLftDrvn 840;
BA_REL_ "GenSigTimeoutTime" BU_SG_REL_ EPSa_PCE SG_ 840 WhlGrndVlctyLftDrvn 250;
BA_REL_ "GenSigRxStartValue" BU_SG_REL_ EPSb_PCE SG_ 840 DrvnWhlGrndVelARC "0";
BA_REL_ "GenSigRxStartValue" BU_SG_REL_ EPSa_PCE SG_ 840 DrvnWhlGrndVelARC "0";
BA_REL_ "GenSigRxStartValue" BU_SG_REL_ EBOOST_OBD_PCE SG_ 840 DrvnWhlGrndVelARC "0";
BA_REL_ "GenSigRxStartValue" BU_SG_REL_ EPSb_PCE SG_ 842 NDrvnWhlGrndVelChksm "0";
BA_REL_ "GenSigRxStartValue" BU_SG_REL_ EPSa_PCE SG_ 842 NDrvnWhlGrndVelChksm "0";
BA_REL_ "GenSigRxStartValue" BU_SG_REL_ EBOOST_OBD_PCE SG_ 842 NDrvnWhlGrndVelChksm "0";
BA_REL_ "GenSigRxStartValue" BU_SG_REL_ EPSb_PCE SG_ 842 NDrvnWhlGrndVelARC "0";
BA_REL_ "GenSigRxStartValue" BU_SG_REL_ EPSa_PCE SG_ 842 NDrvnWhlGrndVelARC "0";
BA_REL_ "GenSigRxStartValue" BU_SG_REL_ EBOOST_OBD_PCE SG_ 842 NDrvnWhlGrndVelARC "0";
BA_REL_ "GenSigRxStartValue" BU_SG_REL_ EBOOST_OBD_PCE SG_ 842 WhlRotDrctnlSRtNDrvn "Unknown";
BA_REL_ "GenSigSuprvResp" BU_SG_REL_ EBOOST_OBD_PCE SG_ 842 WhlRotDrctnlSRtNDrvn 1;
BA_REL_ "GenSigTimeoutMsg" BU_SG_REL_ EBOOST_OBD_PCE SG_ 842 WhlRotDrctnlSRtNDrvn 842;
BA_REL_ "GenSigTimeoutTime" BU_SG_REL_ EBOOST_OBD_PCE SG_ 842 WhlRotDrctnlSRtNDrvn 125;
BA_REL_ "GenSigRxStartValue" BU_SG_REL_ EBOOST_OBD_PCE SG_ 842 WhlRotDrctnlStLfNDrvn "Unknown";
BA_REL_ "GenSigSuprvResp" BU_SG_REL_ EBOOST_OBD_PCE SG_ 842 WhlRotDrctnlStLfNDrvn 1;
BA_REL_ "GenSigTimeoutMsg" BU_SG_REL_ EBOOST_OBD_PCE SG_ 842 WhlRotDrctnlStLfNDrvn 842;
BA_REL_ "GenSigTimeoutTime" BU_SG_REL_ EBOOST_OBD_PCE SG_ 842 WhlRotDrctnlStLfNDrvn 125;
BA_REL_ "GenSigRxStartValue" BU_SG_REL_ EBOOST_OBD_PCE SG_ 842 WhlPlsPerRevNonDrvn "0";
BA_REL_ "GenSigSuprvResp" BU_SG_REL_ EBOOST_OBD_PCE SG_ 842 WhlPlsPerRevNonDrvn 1;
BA_REL_ "GenSigTimeoutMsg" BU_SG_REL_ EBOOST_OBD_PCE SG_ 842 WhlPlsPerRevNonDrvn 842;
BA_REL_ "GenSigTimeoutTime" BU_SG_REL_ EBOOST_OBD_PCE SG_ 842 WhlPlsPerRevNonDrvn 125;
BA_REL_ "GenSigSuprvResp" BU_SG_REL_ EPSb_PCE SG_ 842 WhlPlsPerRevNonDrvn 1;
BA_REL_ "GenSigTimeoutMsg" BU_SG_REL_ EPSb_PCE SG_ 842 WhlPlsPerRevNonDrvn 842;
BA_REL_ "GenSigTimeoutTime" BU_SG_REL_ EPSb_PCE SG_ 842 WhlPlsPerRevNonDrvn 250;
BA_REL_ "GenSigSuprvResp" BU_SG_REL_ EPSa_PCE SG_ 842 WhlPlsPerRevNonDrvn 1;
BA_REL_ "GenSigTimeoutMsg" BU_SG_REL_ EPSa_PCE SG_ 842 WhlPlsPerRevNonDrvn 842;
BA_REL_ "GenSigTimeoutTime" BU_SG_REL_ EPSa_PCE SG_ 842 WhlPlsPerRevNonDrvn 250;
BA_REL_ "GenSigRxStartValue" BU_SG_REL_ EBOOST_OBD_PCE SG_ 842 WhlGrndVlctyRtNnDrvnV "Valid";
BA_REL_ "GenSigVBitResp" BU_SG_REL_ EBOOST_OBD_PCE SG_ 842 WhlGrndVlctyRtNnDrvn 1;
BA_REL_ "GenSigRxStartValue" BU_SG_REL_ EBOOST_OBD_PCE SG_ 842 WhlGrndVlctyRtNnDrvn "0";
BA_REL_ "GenSigSuprvResp" BU_SG_REL_ EBOOST_OBD_PCE SG_ 842 WhlGrndVlctyRtNnDrvn 1;
BA_REL_ "GenSigTimeoutMsg" BU_SG_REL_ EBOOST_OBD_PCE SG_ 842 WhlGrndVlctyRtNnDrvn 842;
BA_REL_ "GenSigTimeoutTime" BU_SG_REL_ EBOOST_OBD_PCE SG_ 842 WhlGrndVlctyRtNnDrvn 125;
BA_REL_ "GenSigVBitResp" BU_SG_REL_ SDM_PCE SG_ 842 WhlGrndVlctyRtNnDrvn 1;
BA_REL_ "GenSigSuprvResp" BU_SG_REL_ SDM_PCE SG_ 842 WhlGrndVlctyRtNnDrvn 1;
BA_REL_ "GenSigTimeoutTime" BU_SG_REL_ SDM_PCE SG_ 842 WhlGrndVlctyRtNnDrvn 250;
BA_REL_ "GenSigVBitResp" BU_SG_REL_ EPSb_PCE SG_ 842 WhlGrndVlctyRtNnDrvn 1;
BA_REL_ "GenSigSuprvResp" BU_SG_REL_ EPSb_PCE SG_ 842 WhlGrndVlctyRtNnDrvn 1;
BA_REL_ "GenSigTimeoutMsg" BU_SG_REL_ EPSb_PCE SG_ 842 WhlGrndVlctyRtNnDrvn 842;
BA_REL_ "GenSigTimeoutTime" BU_SG_REL_ EPSb_PCE SG_ 842 WhlGrndVlctyRtNnDrvn 250;
BA_REL_ "GenSigVBitResp" BU_SG_REL_ EPSa_PCE SG_ 842 WhlGrndVlctyRtNnDrvn 1;
BA_REL_ "GenSigSuprvResp" BU_SG_REL_ EPSa_PCE SG_ 842 WhlGrndVlctyRtNnDrvn 1;
BA_REL_ "GenSigTimeoutMsg" BU_SG_REL_ EPSa_PCE SG_ 842 WhlGrndVlctyRtNnDrvn 842;
BA_REL_ "GenSigTimeoutTime" BU_SG_REL_ EPSa_PCE SG_ 842 WhlGrndVlctyRtNnDrvn 250;
BA_REL_ "GenSigRxStartValue" BU_SG_REL_ EBOOST_OBD_PCE SG_ 842 WhlGrndVlctyLftNnDrvnV "Valid";
BA_REL_ "GenSigVBitResp" BU_SG_REL_ EBOOST_OBD_PCE SG_ 842 WhlGrndVlctyLftNnDrvn 1;
BA_REL_ "GenSigRxStartValue" BU_SG_REL_ EBOOST_OBD_PCE SG_ 842 WhlGrndVlctyLftNnDrvn "0";
BA_REL_ "GenSigSuprvResp" BU_SG_REL_ EBOOST_OBD_PCE SG_ 842 WhlGrndVlctyLftNnDrvn 1;
BA_REL_ "GenSigTimeoutMsg" BU_SG_REL_ EBOOST_OBD_PCE SG_ 842 WhlGrndVlctyLftNnDrvn 842;
BA_REL_ "GenSigTimeoutTime" BU_SG_REL_ EBOOST_OBD_PCE SG_ 842 WhlGrndVlctyLftNnDrvn 125;
BA_REL_ "GenSigVBitResp" BU_SG_REL_ SDM_PCE SG_ 842 WhlGrndVlctyLftNnDrvn 1;
BA_REL_ "GenSigSuprvResp" BU_SG_REL_ SDM_PCE SG_ 842 WhlGrndVlctyLftNnDrvn 1;
BA_REL_ "GenSigTimeoutTime" BU_SG_REL_ SDM_PCE SG_ 842 WhlGrndVlctyLftNnDrvn 250;
BA_REL_ "GenSigVBitResp" BU_SG_REL_ EPSb_PCE SG_ 842 WhlGrndVlctyLftNnDrvn 1;
BA_REL_ "GenSigSuprvResp" BU_SG_REL_ EPSb_PCE SG_ 842 WhlGrndVlctyLftNnDrvn 1;
BA_REL_ "GenSigTimeoutMsg" BU_SG_REL_ EPSb_PCE SG_ 842 WhlGrndVlctyLftNnDrvn 842;
BA_REL_ "GenSigTimeoutTime" BU_SG_REL_ EPSb_PCE SG_ 842 WhlGrndVlctyLftNnDrvn 250;
BA_REL_ "GenSigVBitResp" BU_SG_REL_ EPSa_PCE SG_ 842 WhlGrndVlctyLftNnDrvn 1;
BA_REL_ "GenSigSuprvResp" BU_SG_REL_ EPSa_PCE SG_ 842 WhlGrndVlctyLftNnDrvn 1;
BA_REL_ "GenSigTimeoutMsg" BU_SG_REL_ EPSa_PCE SG_ 842 WhlGrndVlctyLftNnDrvn 842;
BA_REL_ "GenSigTimeoutTime" BU_SG_REL_ EPSa_PCE SG_ 842 WhlGrndVlctyLftNnDrvn 250;
BA_REL_ "GenSigVBitResp" BU_SG_REL_ SDM_PCE SG_ 1001 VehSpdAvgNDrvn 1;
BA_REL_ "GenSigSuprvResp" BU_SG_REL_ SDM_PCE SG_ 1001 VehSpdAvgNDrvn 1;
BA_REL_ "GenSigTimeoutTime" BU_SG_REL_ SDM_PCE SG_ 1001 VehSpdAvgNDrvn 250;
BA_REL_ "GenSigVBitResp" BU_SG_REL_ EPSb_PCE SG_ 1001 VehSpdAvgNDrvn 1;
BA_REL_ "GenSigSuprvResp" BU_SG_REL_ EPSb_PCE SG_ 1001 VehSpdAvgNDrvn 1;
BA_REL_ "GenSigTimeoutMsg" BU_SG_REL_ EPSb_PCE SG_ 1001 VehSpdAvgNDrvn 1001;
BA_REL_ "GenSigTimeoutTime" BU_SG_REL_ EPSb_PCE SG_ 1001 VehSpdAvgNDrvn 250;
BA_REL_ "GenSigVBitResp" BU_SG_REL_ EPSa_PCE SG_ 1001 VehSpdAvgNDrvn 1;
BA_REL_ "GenSigSuprvResp" BU_SG_REL_ EPSa_PCE SG_ 1001 VehSpdAvgNDrvn 1;
BA_REL_ "GenSigTimeoutMsg" BU_SG_REL_ EPSa_PCE SG_ 1001 VehSpdAvgNDrvn 1001;
BA_REL_ "GenSigTimeoutTime" BU_SG_REL_ EPSa_PCE SG_ 1001 VehSpdAvgNDrvn 250;
BA_REL_ "GenSigSuprvResp" BU_SG_REL_ EPSb_PCE SG_ 1001 VehSpdAvgDrvnSrc 1;
BA_REL_ "GenSigTimeoutMsg" BU_SG_REL_ EPSb_PCE SG_ 1001 VehSpdAvgDrvnSrc 1001;
BA_REL_ "GenSigTimeoutTime" BU_SG_REL_ EPSb_PCE SG_ 1001 VehSpdAvgDrvnSrc 250;
BA_REL_ "GenSigSuprvResp" BU_SG_REL_ EPSa_PCE SG_ 1001 VehSpdAvgDrvnSrc 1;
BA_REL_ "GenSigTimeoutMsg" BU_SG_REL_ EPSa_PCE SG_ 1001 VehSpdAvgDrvnSrc 1001;
BA_REL_ "GenSigTimeoutTime" BU_SG_REL_ EPSa_PCE SG_ 1001 VehSpdAvgDrvnSrc 250;
BA_REL_ "GenSigVBitResp" BU_SG_REL_ SDM_PCE SG_ 1001 VehSpdAvgDrvn 1;
BA_REL_ "GenSigSuprvResp" BU_SG_REL_ SDM_PCE SG_ 1001 VehSpdAvgDrvn 1;
BA_REL_ "GenSigTimeoutTime" BU_SG_REL_ SDM_PCE SG_ 1001 VehSpdAvgDrvn 250;
BA_REL_ "GenSigVBitResp" BU_SG_REL_ EPSb_PCE SG_ 1001 VehSpdAvgDrvn 1;
BA_REL_ "GenSigSuprvResp" BU_SG_REL_ EPSb_PCE SG_ 1001 VehSpdAvgDrvn 1;
BA_REL_ "GenSigTimeoutMsg" BU_SG_REL_ EPSb_PCE SG_ 1001 VehSpdAvgDrvn 1001;
BA_REL_ "GenSigTimeoutTime" BU_SG_REL_ EPSb_PCE SG_ 1001 VehSpdAvgDrvn 250;
BA_REL_ "GenSigVBitResp" BU_SG_REL_ EPSa_PCE SG_ 1001 VehSpdAvgDrvn 1;
BA_REL_ "GenSigSuprvResp" BU_SG_REL_ EPSa_PCE SG_ 1001 VehSpdAvgDrvn 1;
BA_REL_ "GenSigTimeoutMsg" BU_SG_REL_ EPSa_PCE SG_ 1001 VehSpdAvgDrvn 1001;
BA_REL_ "GenSigTimeoutTime" BU_SG_REL_ EPSa_PCE SG_ 1001 VehSpdAvgDrvn 250;
BA_REL_ "GenSigRxStartValue" BU_SG_REL_ CMMb_PCE SG_ 197 WRSLNDWhlDisTpRC "0";
BA_REL_ "GenSigSuprvResp" BU_SG_REL_ CMMb_PCE SG_ 197 WRSLNDWhlDisTpRC 1;
BA_REL_ "GenSigTimeoutMsg" BU_SG_REL_ CMMb_PCE SG_ 197 WRSLNDWhlDisTpRC 197;
BA_REL_ "GenSigTimeoutTime" BU_SG_REL_ CMMb_PCE SG_ 197 WRSLNDWhlDisTpRC 30;
BA_REL_ "GenSigRxStartValue" BU_SG_REL_ CMMa_PCE SG_ 197 WRSLNDWhlDisTpRC "0";
BA_REL_ "GenSigSuprvResp" BU_SG_REL_ CMMa_PCE SG_ 197 WRSLNDWhlDisTpRC 1;
BA_REL_ "GenSigTimeoutMsg" BU_SG_REL_ CMMa_PCE SG_ 197 WRSLNDWhlDisTpRC 197;
BA_REL_ "GenSigTimeoutTime" BU_SG_REL_ CMMa_PCE SG_ 197 WRSLNDWhlDisTpRC 30;
BA_REL_ "GenSigRxStartValue" BU_SG_REL_ CMMb_PCE SG_ 197 WRSLNDWhlRotStRst "0";
BA_REL_ "GenSigSuprvResp" BU_SG_REL_ CMMb_PCE SG_ 197 WRSLNDWhlRotStRst 1;
BA_REL_ "GenSigTimeoutMsg" BU_SG_REL_ CMMb_PCE SG_ 197 WRSLNDWhlRotStRst 197;
BA_REL_ "GenSigTimeoutTime" BU_SG_REL_ CMMb_PCE SG_ 197 WRSLNDWhlRotStRst 30;
BA_REL_ "GenSigRxStartValue" BU_SG_REL_ CMMa_PCE SG_ 197 WRSLNDWhlRotStRst "0";
BA_REL_ "GenSigSuprvResp" BU_SG_REL_ CMMa_PCE SG_ 197 WRSLNDWhlRotStRst 1;
BA_REL_ "GenSigTimeoutMsg" BU_SG_REL_ CMMa_PCE SG_ 197 WRSLNDWhlRotStRst 197;
BA_REL_ "GenSigTimeoutTime" BU_SG_REL_ CMMa_PCE SG_ 197 WRSLNDWhlRotStRst 30;
BA_REL_ "GenSigRxStartValue" BU_SG_REL_ CMMb_PCE SG_ 197 WRSLNDWhlDistVal "0";
BA_REL_ "GenSigSuprvResp" BU_SG_REL_ CMMb_PCE SG_ 197 WRSLNDWhlDistVal 1;
BA_REL_ "GenSigTimeoutMsg" BU_SG_REL_ CMMb_PCE SG_ 197 WRSLNDWhlDistVal 197;
BA_REL_ "GenSigTimeoutTime" BU_SG_REL_ CMMb_PCE SG_ 197 WRSLNDWhlDistVal 30;
BA_REL_ "GenSigRxStartValue" BU_SG_REL_ CMMa_PCE SG_ 197 WRSLNDWhlDistVal "0";
BA_REL_ "GenSigSuprvResp" BU_SG_REL_ CMMa_PCE SG_ 197 WRSLNDWhlDistVal 1;
BA_REL_ "GenSigTimeoutMsg" BU_SG_REL_ CMMa_PCE SG_ 197 WRSLNDWhlDistVal 197;
BA_REL_ "GenSigTimeoutTime" BU_SG_REL_ CMMa_PCE SG_ 197 WRSLNDWhlDistVal 30;
BA_REL_ "GenSigRxStartValue" BU_SG_REL_ CMMb_PCE SG_ 197 WRSLNDWhlDistTstm "0";
BA_REL_ "GenSigSuprvResp" BU_SG_REL_ CMMb_PCE SG_ 197 WRSLNDWhlDistTstm 1;
BA_REL_ "GenSigTimeoutMsg" BU_SG_REL_ CMMb_PCE SG_ 197 WRSLNDWhlDistTstm 197;
BA_REL_ "GenSigTimeoutTime" BU_SG_REL_ CMMb_PCE SG_ 197 WRSLNDWhlDistTstm 30;
BA_REL_ "GenSigRxStartValue" BU_SG_REL_ CMMa_PCE SG_ 197 WRSLNDWhlDistTstm "0";
BA_REL_ "GenSigSuprvResp" BU_SG_REL_ CMMa_PCE SG_ 197 WRSLNDWhlDistTstm 1;
BA_REL_ "GenSigTimeoutMsg" BU_SG_REL_ CMMa_PCE SG_ 197 WRSLNDWhlDistTstm 197;
BA_REL_ "GenSigTimeoutTime" BU_SG_REL_ CMMa_PCE SG_ 197 WRSLNDWhlDistTstm 30;
BA_REL_ "GenSigRxStartValue" BU_SG_REL_ CMMb_PCE SG_ 197 WRSLNDWhlDistPCntr "0";
BA_REL_ "GenSigSuprvResp" BU_SG_REL_ CMMb_PCE SG_ 197 WRSLNDWhlDistPCntr 1;
BA_REL_ "GenSigTimeoutMsg" BU_SG_REL_ CMMb_PCE SG_ 197 WRSLNDWhlDistPCntr 197;
BA_REL_ "GenSigTimeoutTime" BU_SG_REL_ CMMb_PCE SG_ 197 WRSLNDWhlDistPCntr 30;
BA_REL_ "GenSigRxStartValue" BU_SG_REL_ CMMa_PCE SG_ 197 WRSLNDWhlDistPCntr "0";
BA_REL_ "GenSigSuprvResp" BU_SG_REL_ CMMa_PCE SG_ 197 WRSLNDWhlDistPCntr 1;
BA_REL_ "GenSigTimeoutMsg" BU_SG_REL_ CMMa_PCE SG_ 197 WRSLNDWhlDistPCntr 197;
BA_REL_ "GenSigTimeoutTime" BU_SG_REL_ CMMa_PCE SG_ 197 WRSLNDWhlDistPCntr 30;
BA_REL_ "GenSigRxStartValue" BU_SG_REL_ CMMb_PCE SG_ 197 WRSLNDSeqNum "0";
BA_REL_ "GenSigSuprvResp" BU_SG_REL_ CMMb_PCE SG_ 197 WRSLNDSeqNum 1;
BA_REL_ "GenSigTimeoutMsg" BU_SG_REL_ CMMb_PCE SG_ 197 WRSLNDSeqNum 197;
BA_REL_ "GenSigTimeoutTime" BU_SG_REL_ CMMb_PCE SG_ 197 WRSLNDSeqNum 30;
BA_REL_ "GenSigRxStartValue" BU_SG_REL_ CMMa_PCE SG_ 197 WRSLNDSeqNum "0";
BA_REL_ "GenSigSuprvResp" BU_SG_REL_ CMMa_PCE SG_ 197 WRSLNDSeqNum 1;
BA_REL_ "GenSigTimeoutMsg" BU_SG_REL_ CMMa_PCE SG_ 197 WRSLNDSeqNum 197;
BA_REL_ "GenSigTimeoutTime" BU_SG_REL_ CMMa_PCE SG_ 197 WRSLNDSeqNum 30;
BA_REL_ "GenSigRxStartValue" BU_SG_REL_ CMMb_PCE SG_ 197 WRSRNDWhlRotStRst "0";
BA_REL_ "GenSigSuprvResp" BU_SG_REL_ CMMb_PCE SG_ 197 WRSRNDWhlRotStRst 1;
BA_REL_ "GenSigTimeoutMsg" BU_SG_REL_ CMMb_PCE SG_ 197 WRSRNDWhlRotStRst 197;
BA_REL_ "GenSigTimeoutTime" BU_SG_REL_ CMMb_PCE SG_ 197 WRSRNDWhlRotStRst 30;
BA_REL_ "GenSigRxStartValue" BU_SG_REL_ CMMa_PCE SG_ 197 WRSRNDWhlRotStRst "0";
BA_REL_ "GenSigSuprvResp" BU_SG_REL_ CMMa_PCE SG_ 197 WRSRNDWhlRotStRst 1;
BA_REL_ "GenSigTimeoutMsg" BU_SG_REL_ CMMa_PCE SG_ 197 WRSRNDWhlRotStRst 197;
BA_REL_ "GenSigTimeoutTime" BU_SG_REL_ CMMa_PCE SG_ 197 WRSRNDWhlRotStRst 30;
BA_REL_ "GenSigRxStartValue" BU_SG_REL_ CMMb_PCE SG_ 197 WRSRNDWhlDisTpRC "0";
BA_REL_ "GenSigSuprvResp" BU_SG_REL_ CMMb_PCE SG_ 197 WRSRNDWhlDisTpRC 1;
BA_REL_ "GenSigTimeoutMsg" BU_SG_REL_ CMMb_PCE SG_ 197 WRSRNDWhlDisTpRC 197;
BA_REL_ "GenSigTimeoutTime" BU_SG_REL_ CMMb_PCE SG_ 197 WRSRNDWhlDisTpRC 30;
BA_REL_ "GenSigRxStartValue" BU_SG_REL_ CMMa_PCE SG_ 197 WRSRNDWhlDisTpRC "0";
BA_REL_ "GenSigSuprvResp" BU_SG_REL_ CMMa_PCE SG_ 197 WRSRNDWhlDisTpRC 1;
BA_REL_ "GenSigTimeoutMsg" BU_SG_REL_ CMMa_PCE SG_ 197 WRSRNDWhlDisTpRC 197;
BA_REL_ "GenSigTimeoutTime" BU_SG_REL_ CMMa_PCE SG_ 197 WRSRNDWhlDisTpRC 30;
BA_REL_ "GenSigRxStartValue" BU_SG_REL_ CMMb_PCE SG_ 197 WRSRNDWhlDistVal "0";
BA_REL_ "GenSigSuprvResp" BU_SG_REL_ CMMb_PCE SG_ 197 WRSRNDWhlDistVal 1;
BA_REL_ "GenSigTimeoutMsg" BU_SG_REL_ CMMb_PCE SG_ 197 WRSRNDWhlDistVal 197;
BA_REL_ "GenSigTimeoutTime" BU_SG_REL_ CMMb_PCE SG_ 197 WRSRNDWhlDistVal 30;
BA_REL_ "GenSigRxStartValue" BU_SG_REL_ CMMa_PCE SG_ 197 WRSRNDWhlDistVal "0";
BA_REL_ "GenSigSuprvResp" BU_SG_REL_ CMMa_PCE SG_ 197 WRSRNDWhlDistVal 1;
BA_REL_ "GenSigTimeoutMsg" BU_SG_REL_ CMMa_PCE SG_ 197 WRSRNDWhlDistVal 197;
BA_REL_ "GenSigTimeoutTime" BU_SG_REL_ CMMa_PCE SG_ 197 WRSRNDWhlDistVal 30;
BA_REL_ "GenSigRxStartValue" BU_SG_REL_ CMMb_PCE SG_ 197 WRSRNDWhlDistTstm "0";
BA_REL_ "GenSigSuprvResp" BU_SG_REL_ CMMb_PCE SG_ 197 WRSRNDWhlDistTstm 1;
BA_REL_ "GenSigTimeoutMsg" BU_SG_REL_ CMMb_PCE SG_ 197 WRSRNDWhlDistTstm 197;
BA_REL_ "GenSigTimeoutTime" BU_SG_REL_ CMMb_PCE SG_ 197 WRSRNDWhlDistTstm 30;
BA_REL_ "GenSigRxStartValue" BU_SG_REL_ CMMa_PCE SG_ 197 WRSRNDWhlDistTstm "0";
BA_REL_ "GenSigSuprvResp" BU_SG_REL_ CMMa_PCE SG_ 197 WRSRNDWhlDistTstm 1;
BA_REL_ "GenSigTimeoutMsg" BU_SG_REL_ CMMa_PCE SG_ 197 WRSRNDWhlDistTstm 197;
BA_REL_ "GenSigTimeoutTime" BU_SG_REL_ CMMa_PCE SG_ 197 WRSRNDWhlDistTstm 30;
BA_REL_ "GenSigRxStartValue" BU_SG_REL_ CMMb_PCE SG_ 197 WRSRNDWhlDistPCntr "0";
BA_REL_ "GenSigSuprvResp" BU_SG_REL_ CMMb_PCE SG_ 197 WRSRNDWhlDistPCntr 1;
BA_REL_ "GenSigTimeoutMsg" BU_SG_REL_ CMMb_PCE SG_ 197 WRSRNDWhlDistPCntr 197;
BA_REL_ "GenSigTimeoutTime" BU_SG_REL_ CMMb_PCE SG_ 197 WRSRNDWhlDistPCntr 30;
BA_REL_ "GenSigRxStartValue" BU_SG_REL_ CMMa_PCE SG_ 197 WRSRNDWhlDistPCntr "0";
BA_REL_ "GenSigSuprvResp" BU_SG_REL_ CMMa_PCE SG_ 197 WRSRNDWhlDistPCntr 1;
BA_REL_ "GenSigTimeoutMsg" BU_SG_REL_ CMMa_PCE SG_ 197 WRSRNDWhlDistPCntr 197;
BA_REL_ "GenSigTimeoutTime" BU_SG_REL_ CMMa_PCE SG_ 197 WRSRNDWhlDistPCntr 30;
BA_REL_ "GenSigRxStartValue" BU_SG_REL_ CMMb_PCE SG_ 197 WRSRNDSeqNum "0";
BA_REL_ "GenSigSuprvResp" BU_SG_REL_ CMMb_PCE SG_ 197 WRSRNDSeqNum 1;
BA_REL_ "GenSigTimeoutMsg" BU_SG_REL_ CMMb_PCE SG_ 197 WRSRNDSeqNum 197;
BA_REL_ "GenSigTimeoutTime" BU_SG_REL_ CMMb_PCE SG_ 197 WRSRNDSeqNum 30;
BA_REL_ "GenSigRxStartValue" BU_SG_REL_ CMMa_PCE SG_ 197 WRSRNDSeqNum "0";
BA_REL_ "GenSigSuprvResp" BU_SG_REL_ CMMa_PCE SG_ 197 WRSRNDSeqNum 1;
BA_REL_ "GenSigTimeoutMsg" BU_SG_REL_ CMMa_PCE SG_ 197 WRSRNDSeqNum 197;
BA_REL_ "GenSigTimeoutTime" BU_SG_REL_ CMMa_PCE SG_ 197 WRSRNDSeqNum 30;
BA_REL_ "GenSigVDAFailComment" BU_SG_REL_ EBOOST_OBD_PCE SG_ 289 SysPwrMd "System Power Mode VDA";
BA_REL_ "GenSigVDAFailResp" BU_SG_REL_ EBOOST_OBD_PCE SG_ 289 SysPwrMd 1;
BA_REL_ "GenSigSuprvResp" BU_SG_REL_ EBOOST_OBD_PCE SG_ 289 SysPwrMd 1;
BA_REL_ "GenSigTimeoutMsg" BU_SG_REL_ EBOOST_OBD_PCE SG_ 289 SysPwrMd 289;
BA_REL_ "GenSigTimeoutTime" BU_SG_REL_ EBOOST_OBD_PCE SG_ 289 SysPwrMd 250;
BA_REL_ "GenSigVDAFailComment" BU_SG_REL_ SDM_PCE SG_ 289 SysPwrMd "System Power Mode VDA";
BA_REL_ "GenSigVDAFailResp" BU_SG_REL_ SDM_PCE SG_ 289 SysPwrMd 1;
BA_REL_ "GenSigSuprvResp" BU_SG_REL_ SDM_PCE SG_ 289 SysPwrMd 1;
BA_REL_ "GenSigTimeoutMsg" BU_SG_REL_ SDM_PCE SG_ 289 SysPwrMd 289;
BA_REL_ "GenSigTimeoutTime" BU_SG_REL_ SDM_PCE SG_ 289 SysPwrMd 250;
BA_REL_ "GenSigSuprvResp" BU_SG_REL_ EBOOST_OBD_PCE SG_ 290 BkupPwrModeMstrVDA 1;
BA_REL_ "GenSigTimeoutMsg" BU_SG_REL_ EBOOST_OBD_PCE SG_ 290 BkupPwrModeMstrVDA 290;
BA_REL_ "GenSigTimeoutTime" BU_SG_REL_ EBOOST_OBD_PCE SG_ 290 BkupPwrModeMstrVDA 250;
BA_REL_ "GenSigSuprvResp" BU_SG_REL_ SDM_PCE SG_ 290 BkupPwrModeMstrVDA 1;
BA_REL_ "GenSigTimeoutMsg" BU_SG_REL_ SDM_PCE SG_ 290 BkupPwrModeMstrVDA 290;
BA_REL_ "GenSigTimeoutTime" BU_SG_REL_ SDM_PCE SG_ 290 BkupPwrModeMstrVDA 250;
BA_REL_ "GenSigSuprvResp" BU_SG_REL_ EBOOST_OBD_PCE SG_ 290 SysBkupPwrMdEn 1;
BA_REL_ "GenSigTimeoutMsg" BU_SG_REL_ EBOOST_OBD_PCE SG_ 290 SysBkupPwrMdEn 290;
BA_REL_ "GenSigTimeoutTime" BU_SG_REL_ EBOOST_OBD_PCE SG_ 290 SysBkupPwrMdEn 250;
BA_REL_ "GenSigSuprvResp" BU_SG_REL_ SDM_PCE SG_ 290 SysBkupPwrMdEn 1;
BA_REL_ "GenSigTimeoutMsg" BU_SG_REL_ SDM_PCE SG_ 290 SysBkupPwrMdEn 290;
BA_REL_ "GenSigTimeoutTime" BU_SG_REL_ SDM_PCE SG_ 290 SysBkupPwrMdEn 250;
BA_REL_ "GenSigVDAFailComment" BU_SG_REL_ EBOOST_OBD_PCE SG_ 290 SysBkUpPwrMd "Backup Power Mode Master VDA";
BA_REL_ "GenSigVDAFailResp" BU_SG_REL_ EBOOST_OBD_PCE SG_ 290 SysBkUpPwrMd 1;
BA_REL_ "GenSigSuprvResp" BU_SG_REL_ EBOOST_OBD_PCE SG_ 290 SysBkUpPwrMd 1;
BA_REL_ "GenSigTimeoutMsg" BU_SG_REL_ EBOOST_OBD_PCE SG_ 290 SysBkUpPwrMd 290;
BA_REL_ "GenSigTimeoutTime" BU_SG_REL_ EBOOST_OBD_PCE SG_ 290 SysBkUpPwrMd 250;
BA_REL_ "GenSigVDAFailComment" BU_SG_REL_ SDM_PCE SG_ 290 SysBkUpPwrMd "Backup Power Mode Master VDA";
BA_REL_ "GenSigVDAFailResp" BU_SG_REL_ SDM_PCE SG_ 290 SysBkUpPwrMd 1;
BA_REL_ "GenSigSuprvResp" BU_SG_REL_ SDM_PCE SG_ 290 SysBkUpPwrMd 1;
BA_REL_ "GenSigTimeoutMsg" BU_SG_REL_ SDM_PCE SG_ 290 SysBkUpPwrMd 290;
BA_REL_ "GenSigTimeoutTime" BU_SG_REL_ SDM_PCE SG_ 290 SysBkUpPwrMd 250;
BA_REL_ "GenSigRxStartValue" BU_SG_REL_ CMMb_PCE SG_ 485 StrAngSnsChksm "0";
BA_REL_ "GenSigRxStartValue" BU_SG_REL_ CMMa_PCE SG_ 485 StrAngSnsChksm "0";
BA_REL_ "GenSigRxStartValue" BU_SG_REL_ CMMb_PCE SG_ 485 StrWhAngGrdV "Valid";
BA_REL_ "GenSigRxStartValue" BU_SG_REL_ CMMa_PCE SG_ 485 StrWhAngGrdV "Valid";
BA_REL_ "GenSigRxStartValue" BU_SG_REL_ CMMb_PCE SG_ 485 StrWhAngGrdMsk "Don't Use Data";
BA_REL_ "GenSigRxStartValue" BU_SG_REL_ CMMa_PCE SG_ 485 StrWhAngGrdMsk "Don't Use Data";
BA_REL_ "GenSigRxStartValue" BU_SG_REL_ CMMb_PCE SG_ 485 StrWhAngMsk "Don't Use Data";
BA_REL_ "GenSigRxStartValue" BU_SG_REL_ CMMa_PCE SG_ 485 StrWhAngMsk "Don't Use Data";
BA_REL_ "GenSigRxStartValue" BU_SG_REL_ CMMb_PCE SG_ 485 StrWhlAngSenTyp "Type 1";
BA_REL_ "GenSigSuprvResp" BU_SG_REL_ CMMb_PCE SG_ 485 StrWhlAngSenTyp 1;
BA_REL_ "GenSigTimeoutMsg" BU_SG_REL_ CMMb_PCE SG_ 485 StrWhlAngSenTyp 485;
BA_REL_ "GenSigTimeoutTime" BU_SG_REL_ CMMb_PCE SG_ 485 StrWhlAngSenTyp 30;
BA_REL_ "GenSigRxStartValue" BU_SG_REL_ CMMa_PCE SG_ 485 StrWhlAngSenTyp "Type 1";
BA_REL_ "GenSigSuprvResp" BU_SG_REL_ CMMa_PCE SG_ 485 StrWhlAngSenTyp 1;
BA_REL_ "GenSigTimeoutMsg" BU_SG_REL_ CMMa_PCE SG_ 485 StrWhlAngSenTyp 485;
BA_REL_ "GenSigTimeoutTime" BU_SG_REL_ CMMa_PCE SG_ 485 StrWhlAngSenTyp 30;
BA_REL_ "GenSigRxStartValue" BU_SG_REL_ CMMb_PCE SG_ 485 StrWhlAngSenCalStat "Unknown";
BA_REL_ "GenSigSuprvResp" BU_SG_REL_ CMMb_PCE SG_ 485 StrWhlAngSenCalStat 1;
BA_REL_ "GenSigTimeoutMsg" BU_SG_REL_ CMMb_PCE SG_ 485 StrWhlAngSenCalStat 485;
BA_REL_ "GenSigTimeoutTime" BU_SG_REL_ CMMb_PCE SG_ 485 StrWhlAngSenCalStat 30;
BA_REL_ "GenSigRxStartValue" BU_SG_REL_ CMMa_PCE SG_ 485 StrWhlAngSenCalStat "Unknown";
BA_REL_ "GenSigSuprvResp" BU_SG_REL_ CMMa_PCE SG_ 485 StrWhlAngSenCalStat 1;
BA_REL_ "GenSigTimeoutMsg" BU_SG_REL_ CMMa_PCE SG_ 485 StrWhlAngSenCalStat 485;
BA_REL_ "GenSigTimeoutTime" BU_SG_REL_ CMMa_PCE SG_ 485 StrWhlAngSenCalStat 30;
BA_REL_ "GenSigVBitResp" BU_SG_REL_ CMMb_PCE SG_ 485 StrWhAngGrd 1;
BA_REL_ "GenSigRxStartValue" BU_SG_REL_ CMMb_PCE SG_ 485 StrWhAngGrd "0";
BA_REL_ "GenSigSuprvResp" BU_SG_REL_ CMMb_PCE SG_ 485 StrWhAngGrd 1;
BA_REL_ "GenSigTimeoutMsg" BU_SG_REL_ CMMb_PCE SG_ 485 StrWhAngGrd 485;
BA_REL_ "GenSigTimeoutTime" BU_SG_REL_ CMMb_PCE SG_ 485 StrWhAngGrd 30;
BA_REL_ "GenSigVBitResp" BU_SG_REL_ CMMa_PCE SG_ 485 StrWhAngGrd 1;
BA_REL_ "GenSigRxStartValue" BU_SG_REL_ CMMa_PCE SG_ 485 StrWhAngGrd "0";
BA_REL_ "GenSigSuprvResp" BU_SG_REL_ CMMa_PCE SG_ 485 StrWhAngGrd 1;
BA_REL_ "GenSigTimeoutMsg" BU_SG_REL_ CMMa_PCE SG_ 485 StrWhAngGrd 485;
BA_REL_ "GenSigTimeoutTime" BU_SG_REL_ CMMa_PCE SG_ 485 StrWhAngGrd 30;
BA_REL_ "GenSigVBitResp" BU_SG_REL_ SDM_PCE SG_ 485 StrWhAngGrd 1;
BA_REL_ "GenSigRxStartValue" BU_SG_REL_ CMMb_PCE SG_ 485 StWhlAngAliveRollCnt "0";
BA_REL_ "GenSigRxStartValue" BU_SG_REL_ CMMa_PCE SG_ 485 StWhlAngAliveRollCnt "0";
BA_REL_ "GenSigRxStartValue" BU_SG_REL_ CMMb_PCE SG_ 485 StrWhAngV "Valid";
BA_REL_ "GenSigRxStartValue" BU_SG_REL_ CMMa_PCE SG_ 485 StrWhAngV "Valid";
BA_REL_ "GenSigVBitResp" BU_SG_REL_ CMMb_PCE SG_ 485 StrWhAng 1;
BA_REL_ "GenSigRxStartValue" BU_SG_REL_ CMMb_PCE SG_ 485 StrWhAng "0";
BA_REL_ "GenSigSuprvResp" BU_SG_REL_ CMMb_PCE SG_ 485 StrWhAng 1;
BA_REL_ "GenSigTimeoutMsg" BU_SG_REL_ CMMb_PCE SG_ 485 StrWhAng 485;
BA_REL_ "GenSigTimeoutTime" BU_SG_REL_ CMMb_PCE SG_ 485 StrWhAng 30;
BA_REL_ "GenSigVBitResp" BU_SG_REL_ CMMa_PCE SG_ 485 StrWhAng 1;
BA_REL_ "GenSigRxStartValue" BU_SG_REL_ CMMa_PCE SG_ 485 StrWhAng "0";
BA_REL_ "GenSigSuprvResp" BU_SG_REL_ CMMa_PCE SG_ 485 StrWhAng 1;
BA_REL_ "GenSigTimeoutMsg" BU_SG_REL_ CMMa_PCE SG_ 485 StrWhAng 485;
BA_REL_ "GenSigTimeoutTime" BU_SG_REL_ CMMa_PCE SG_ 485 StrWhAng 30;
BA_REL_ "GenSigVBitResp" BU_SG_REL_ SDM_PCE SG_ 485 StrWhAng 1;
BA_REL_ "GenSigSuprvResp" BU_SG_REL_ SDM_PCE SG_ 485 StrWhAng 1;
BA_REL_ "GenSigTimeoutMsg" BU_SG_REL_ SDM_PCE SG_ 485 StrWhAng 485;
BA_REL_ "GenSigTimeoutTime" BU_SG_REL_ SDM_PCE SG_ 485 StrWhAng 250;
BA_REL_ "GenSigRxStartValue" BU_SG_REL_ CMMb_PCE SG_ 192 WRSCD_RNDrvnCkVa "0";
BA_REL_ "GenSigSuprvResp" BU_SG_REL_ CMMb_PCE SG_ 192 WRSCD_RNDrvnCkVa 1;
BA_REL_ "GenSigTimeoutMsg" BU_SG_REL_ CMMb_PCE SG_ 192 WRSCD_RNDrvnCkVa 192;
BA_REL_ "GenSigTimeoutTime" BU_SG_REL_ CMMb_PCE SG_ 192 WRSCD_RNDrvnCkVa 30;
BA_REL_ "GenSigRxStartValue" BU_SG_REL_ CMMa_PCE SG_ 192 WRSCD_RNDrvnCkVa "0";
BA_REL_ "GenSigSuprvResp" BU_SG_REL_ CMMa_PCE SG_ 192 WRSCD_RNDrvnCkVa 1;
BA_REL_ "GenSigTimeoutMsg" BU_SG_REL_ CMMa_PCE SG_ 192 WRSCD_RNDrvnCkVa 192;
BA_REL_ "GenSigTimeoutTime" BU_SG_REL_ CMMa_PCE SG_ 192 WRSCD_RNDrvnCkVa 30;
BA_REL_ "GenSigRxStartValue" BU_SG_REL_ CMMb_PCE SG_ 192 WRSCD_LfNDrvnCkVa "0";
BA_REL_ "GenSigSuprvResp" BU_SG_REL_ CMMb_PCE SG_ 192 WRSCD_LfNDrvnCkVa 1;
BA_REL_ "GenSigTimeoutMsg" BU_SG_REL_ CMMb_PCE SG_ 192 WRSCD_LfNDrvnCkVa 192;
BA_REL_ "GenSigTimeoutTime" BU_SG_REL_ CMMb_PCE SG_ 192 WRSCD_LfNDrvnCkVa 30;
BA_REL_ "GenSigRxStartValue" BU_SG_REL_ CMMa_PCE SG_ 192 WRSCD_LfNDrvnCkVa "0";
BA_REL_ "GenSigSuprvResp" BU_SG_REL_ CMMa_PCE SG_ 192 WRSCD_LfNDrvnCkVa 1;
BA_REL_ "GenSigTimeoutMsg" BU_SG_REL_ CMMa_PCE SG_ 192 WRSCD_LfNDrvnCkVa 192;
BA_REL_ "GenSigTimeoutTime" BU_SG_REL_ CMMa_PCE SG_ 192 WRSCD_LfNDrvnCkVa 30;
BA_REL_ "GenSigRxStartValue" BU_SG_REL_ CMMb_PCE SG_ 192 WRSCD_RDrvnCkVa "0";
BA_REL_ "GenSigSuprvResp" BU_SG_REL_ CMMb_PCE SG_ 192 WRSCD_RDrvnCkVa 1;
BA_REL_ "GenSigTimeoutMsg" BU_SG_REL_ CMMb_PCE SG_ 192 WRSCD_RDrvnCkVa 192;
BA_REL_ "GenSigTimeoutTime" BU_SG_REL_ CMMb_PCE SG_ 192 WRSCD_RDrvnCkVa 30;
BA_REL_ "GenSigRxStartValue" BU_SG_REL_ CMMa_PCE SG_ 192 WRSCD_RDrvnCkVa "0";
BA_REL_ "GenSigSuprvResp" BU_SG_REL_ CMMa_PCE SG_ 192 WRSCD_RDrvnCkVa 1;
BA_REL_ "GenSigTimeoutMsg" BU_SG_REL_ CMMa_PCE SG_ 192 WRSCD_RDrvnCkVa 192;
BA_REL_ "GenSigTimeoutTime" BU_SG_REL_ CMMa_PCE SG_ 192 WRSCD_RDrvnCkVa 30;
BA_REL_ "GenSigRxStartValue" BU_SG_REL_ CMMb_PCE SG_ 192 WRSCD_LfDrvnCkVa "0";
BA_REL_ "GenSigSuprvResp" BU_SG_REL_ CMMb_PCE SG_ 192 WRSCD_LfDrvnCkVa 1;
BA_REL_ "GenSigTimeoutMsg" BU_SG_REL_ CMMb_PCE SG_ 192 WRSCD_LfDrvnCkVa 192;
BA_REL_ "GenSigTimeoutTime" BU_SG_REL_ CMMb_PCE SG_ 192 WRSCD_LfDrvnCkVa 30;
BA_REL_ "GenSigRxStartValue" BU_SG_REL_ CMMa_PCE SG_ 192 WRSCD_LfDrvnCkVa "0";
BA_REL_ "GenSigSuprvResp" BU_SG_REL_ CMMa_PCE SG_ 192 WRSCD_LfDrvnCkVa 1;
BA_REL_ "GenSigTimeoutMsg" BU_SG_REL_ CMMa_PCE SG_ 192 WRSCD_LfDrvnCkVa 192;
BA_REL_ "GenSigTimeoutTime" BU_SG_REL_ CMMa_PCE SG_ 192 WRSCD_LfDrvnCkVa 30;
BA_REL_ "GenSigRxStartValue" BU_SG_REL_ CMMb_PCE SG_ 192 WRSCD_RtNDrvnSNm "0";
BA_REL_ "GenSigSuprvResp" BU_SG_REL_ CMMb_PCE SG_ 192 WRSCD_RtNDrvnSNm 1;
BA_REL_ "GenSigTimeoutMsg" BU_SG_REL_ CMMb_PCE SG_ 192 WRSCD_RtNDrvnSNm 192;
BA_REL_ "GenSigTimeoutTime" BU_SG_REL_ CMMb_PCE SG_ 192 WRSCD_RtNDrvnSNm 30;
BA_REL_ "GenSigRxStartValue" BU_SG_REL_ CMMa_PCE SG_ 192 WRSCD_RtNDrvnSNm "0";
BA_REL_ "GenSigSuprvResp" BU_SG_REL_ CMMa_PCE SG_ 192 WRSCD_RtNDrvnSNm 1;
BA_REL_ "GenSigTimeoutMsg" BU_SG_REL_ CMMa_PCE SG_ 192 WRSCD_RtNDrvnSNm 192;
BA_REL_ "GenSigTimeoutTime" BU_SG_REL_ CMMa_PCE SG_ 192 WRSCD_RtNDrvnSNm 30;
BA_REL_ "GenSigRxStartValue" BU_SG_REL_ CMMb_PCE SG_ 192 WRSCD_LftNDrvnSNm "0";
BA_REL_ "GenSigSuprvResp" BU_SG_REL_ CMMb_PCE SG_ 192 WRSCD_LftNDrvnSNm 1;
BA_REL_ "GenSigTimeoutMsg" BU_SG_REL_ CMMb_PCE SG_ 192 WRSCD_LftNDrvnSNm 192;
BA_REL_ "GenSigTimeoutTime" BU_SG_REL_ CMMb_PCE SG_ 192 WRSCD_LftNDrvnSNm 30;
BA_REL_ "GenSigRxStartValue" BU_SG_REL_ CMMa_PCE SG_ 192 WRSCD_LftNDrvnSNm "0";
BA_REL_ "GenSigSuprvResp" BU_SG_REL_ CMMa_PCE SG_ 192 WRSCD_LftNDrvnSNm 1;
BA_REL_ "GenSigTimeoutMsg" BU_SG_REL_ CMMa_PCE SG_ 192 WRSCD_LftNDrvnSNm 192;
BA_REL_ "GenSigTimeoutTime" BU_SG_REL_ CMMa_PCE SG_ 192 WRSCD_LftNDrvnSNm 30;
BA_REL_ "GenSigRxStartValue" BU_SG_REL_ CMMb_PCE SG_ 192 WRSCD_RtDrvnSqNm "0";
BA_REL_ "GenSigSuprvResp" BU_SG_REL_ CMMb_PCE SG_ 192 WRSCD_RtDrvnSqNm 1;
BA_REL_ "GenSigTimeoutMsg" BU_SG_REL_ CMMb_PCE SG_ 192 WRSCD_RtDrvnSqNm 192;
BA_REL_ "GenSigTimeoutTime" BU_SG_REL_ CMMb_PCE SG_ 192 WRSCD_RtDrvnSqNm 30;
BA_REL_ "GenSigRxStartValue" BU_SG_REL_ CMMa_PCE SG_ 192 WRSCD_RtDrvnSqNm "0";
BA_REL_ "GenSigSuprvResp" BU_SG_REL_ CMMa_PCE SG_ 192 WRSCD_RtDrvnSqNm 1;
BA_REL_ "GenSigTimeoutMsg" BU_SG_REL_ CMMa_PCE SG_ 192 WRSCD_RtDrvnSqNm 192;
BA_REL_ "GenSigTimeoutTime" BU_SG_REL_ CMMa_PCE SG_ 192 WRSCD_RtDrvnSqNm 30;
BA_REL_ "GenSigRxStartValue" BU_SG_REL_ CMMb_PCE SG_ 192 WRSCD_LftDrvnSqNm "0";
BA_REL_ "GenSigSuprvResp" BU_SG_REL_ CMMb_PCE SG_ 192 WRSCD_LftDrvnSqNm 1;
BA_REL_ "GenSigTimeoutMsg" BU_SG_REL_ CMMb_PCE SG_ 192 WRSCD_LftDrvnSqNm 192;
BA_REL_ "GenSigTimeoutTime" BU_SG_REL_ CMMb_PCE SG_ 192 WRSCD_LftDrvnSqNm 30;
BA_REL_ "GenSigRxStartValue" BU_SG_REL_ CMMa_PCE SG_ 192 WRSCD_LftDrvnSqNm "0";
BA_REL_ "GenSigSuprvResp" BU_SG_REL_ CMMa_PCE SG_ 192 WRSCD_LftDrvnSqNm 1;
BA_REL_ "GenSigTimeoutMsg" BU_SG_REL_ CMMa_PCE SG_ 192 WRSCD_LftDrvnSqNm 192;
BA_REL_ "GenSigTimeoutTime" BU_SG_REL_ CMMa_PCE SG_ 192 WRSCD_LftDrvnSqNm 30;
BA_REL_ "GenSigRxStartValue" BU_SG_REL_ CMMb_PCE SG_ 193 WRSLDWhlRotStatRst "0";
BA_REL_ "GenSigSuprvResp" BU_SG_REL_ CMMb_PCE SG_ 193 WRSLDWhlRotStatRst 1;
BA_REL_ "GenSigTimeoutMsg" BU_SG_REL_ CMMb_PCE SG_ 193 WRSLDWhlRotStatRst 193;
BA_REL_ "GenSigTimeoutTime" BU_SG_REL_ CMMb_PCE SG_ 193 WRSLDWhlRotStatRst 30;
BA_REL_ "GenSigRxStartValue" BU_SG_REL_ CMMa_PCE SG_ 193 WRSLDWhlRotStatRst "0";
BA_REL_ "GenSigSuprvResp" BU_SG_REL_ CMMa_PCE SG_ 193 WRSLDWhlRotStatRst 1;
BA_REL_ "GenSigTimeoutMsg" BU_SG_REL_ CMMa_PCE SG_ 193 WRSLDWhlRotStatRst 193;
BA_REL_ "GenSigTimeoutTime" BU_SG_REL_ CMMa_PCE SG_ 193 WRSLDWhlRotStatRst 30;
BA_REL_ "GenSigSuprvResp" BU_SG_REL_ SDM_PCE SG_ 193 WRSLDWhlRotStatRst 1;
BA_REL_ "GenSigTimeoutMsg" BU_SG_REL_ SDM_PCE SG_ 193 WRSLDWhlRotStatRst 193;
BA_REL_ "GenSigTimeoutTime" BU_SG_REL_ SDM_PCE SG_ 193 WRSLDWhlRotStatRst 250;
BA_REL_ "GenSigRxStartValue" BU_SG_REL_ CMMb_PCE SG_ 193 WRSLDWhlDisTpRC "0";
BA_REL_ "GenSigSuprvResp" BU_SG_REL_ CMMb_PCE SG_ 193 WRSLDWhlDisTpRC 1;
BA_REL_ "GenSigTimeoutMsg" BU_SG_REL_ CMMb_PCE SG_ 193 WRSLDWhlDisTpRC 193;
BA_REL_ "GenSigTimeoutTime" BU_SG_REL_ CMMb_PCE SG_ 193 WRSLDWhlDisTpRC 30;
BA_REL_ "GenSigRxStartValue" BU_SG_REL_ CMMa_PCE SG_ 193 WRSLDWhlDisTpRC "0";
BA_REL_ "GenSigSuprvResp" BU_SG_REL_ CMMa_PCE SG_ 193 WRSLDWhlDisTpRC 1;
BA_REL_ "GenSigTimeoutMsg" BU_SG_REL_ CMMa_PCE SG_ 193 WRSLDWhlDisTpRC 193;
BA_REL_ "GenSigTimeoutTime" BU_SG_REL_ CMMa_PCE SG_ 193 WRSLDWhlDisTpRC 30;
BA_REL_ "GenSigSuprvResp" BU_SG_REL_ SDM_PCE SG_ 193 WRSLDWhlDisTpRC 1;
BA_REL_ "GenSigTimeoutMsg" BU_SG_REL_ SDM_PCE SG_ 193 WRSLDWhlDisTpRC 193;
BA_REL_ "GenSigTimeoutTime" BU_SG_REL_ SDM_PCE SG_ 193 WRSLDWhlDisTpRC 250;
BA_REL_ "GenSigRxStartValue" BU_SG_REL_ CMMb_PCE SG_ 193 WRSLDSeqNum "0";
BA_REL_ "GenSigSuprvResp" BU_SG_REL_ CMMb_PCE SG_ 193 WRSLDSeqNum 1;
BA_REL_ "GenSigTimeoutMsg" BU_SG_REL_ CMMb_PCE SG_ 193 WRSLDSeqNum 193;
BA_REL_ "GenSigTimeoutTime" BU_SG_REL_ CMMb_PCE SG_ 193 WRSLDSeqNum 30;
BA_REL_ "GenSigRxStartValue" BU_SG_REL_ CMMa_PCE SG_ 193 WRSLDSeqNum "0";
BA_REL_ "GenSigSuprvResp" BU_SG_REL_ CMMa_PCE SG_ 193 WRSLDSeqNum 1;
BA_REL_ "GenSigTimeoutMsg" BU_SG_REL_ CMMa_PCE SG_ 193 WRSLDSeqNum 193;
BA_REL_ "GenSigTimeoutTime" BU_SG_REL_ CMMa_PCE SG_ 193 WRSLDSeqNum 30;
BA_REL_ "GenSigSuprvResp" BU_SG_REL_ SDM_PCE SG_ 193 WRSLDSeqNum 1;
BA_REL_ "GenSigTimeoutMsg" BU_SG_REL_ SDM_PCE SG_ 193 WRSLDSeqNum 193;
BA_REL_ "GenSigTimeoutTime" BU_SG_REL_ SDM_PCE SG_ 193 WRSLDSeqNum 250;
BA_REL_ "GenSigRxStartValue" BU_SG_REL_ CMMb_PCE SG_ 193 WRSLDWhlDistVal "0";
BA_REL_ "GenSigSuprvResp" BU_SG_REL_ CMMb_PCE SG_ 193 WRSLDWhlDistVal 1;
BA_REL_ "GenSigTimeoutMsg" BU_SG_REL_ CMMb_PCE SG_ 193 WRSLDWhlDistVal 193;
BA_REL_ "GenSigTimeoutTime" BU_SG_REL_ CMMb_PCE SG_ 193 WRSLDWhlDistVal 30;
BA_REL_ "GenSigRxStartValue" BU_SG_REL_ CMMa_PCE SG_ 193 WRSLDWhlDistVal "0";
BA_REL_ "GenSigSuprvResp" BU_SG_REL_ CMMa_PCE SG_ 193 WRSLDWhlDistVal 1;
BA_REL_ "GenSigTimeoutMsg" BU_SG_REL_ CMMa_PCE SG_ 193 WRSLDWhlDistVal 193;
BA_REL_ "GenSigTimeoutTime" BU_SG_REL_ CMMa_PCE SG_ 193 WRSLDWhlDistVal 30;
BA_REL_ "GenSigSuprvResp" BU_SG_REL_ SDM_PCE SG_ 193 WRSLDWhlDistVal 1;
BA_REL_ "GenSigTimeoutMsg" BU_SG_REL_ SDM_PCE SG_ 193 WRSLDWhlDistVal 193;
BA_REL_ "GenSigTimeoutTime" BU_SG_REL_ SDM_PCE SG_ 193 WRSLDWhlDistVal 250;
BA_REL_ "GenSigRxStartValue" BU_SG_REL_ CMMb_PCE SG_ 193 WRSLDWhlDistTmstm "0";
BA_REL_ "GenSigSuprvResp" BU_SG_REL_ CMMb_PCE SG_ 193 WRSLDWhlDistTmstm 1;
BA_REL_ "GenSigTimeoutMsg" BU_SG_REL_ CMMb_PCE SG_ 193 WRSLDWhlDistTmstm 193;
BA_REL_ "GenSigTimeoutTime" BU_SG_REL_ CMMb_PCE SG_ 193 WRSLDWhlDistTmstm 30;
BA_REL_ "GenSigRxStartValue" BU_SG_REL_ CMMa_PCE SG_ 193 WRSLDWhlDistTmstm "0";
BA_REL_ "GenSigSuprvResp" BU_SG_REL_ CMMa_PCE SG_ 193 WRSLDWhlDistTmstm 1;
BA_REL_ "GenSigTimeoutMsg" BU_SG_REL_ CMMa_PCE SG_ 193 WRSLDWhlDistTmstm 193;
BA_REL_ "GenSigTimeoutTime" BU_SG_REL_ CMMa_PCE SG_ 193 WRSLDWhlDistTmstm 30;
BA_REL_ "GenSigSuprvResp" BU_SG_REL_ SDM_PCE SG_ 193 WRSLDWhlDistTmstm 1;
BA_REL_ "GenSigTimeoutMsg" BU_SG_REL_ SDM_PCE SG_ 193 WRSLDWhlDistTmstm 193;
BA_REL_ "GenSigTimeoutTime" BU_SG_REL_ SDM_PCE SG_ 193 WRSLDWhlDistTmstm 250;
BA_REL_ "GenSigRxStartValue" BU_SG_REL_ CMMb_PCE SG_ 193 WRSLDWhlDistPlsCntr "0";
BA_REL_ "GenSigSuprvResp" BU_SG_REL_ CMMb_PCE SG_ 193 WRSLDWhlDistPlsCntr 1;
BA_REL_ "GenSigTimeoutMsg" BU_SG_REL_ CMMb_PCE SG_ 193 WRSLDWhlDistPlsCntr 193;
BA_REL_ "GenSigTimeoutTime" BU_SG_REL_ CMMb_PCE SG_ 193 WRSLDWhlDistPlsCntr 30;
BA_REL_ "GenSigRxStartValue" BU_SG_REL_ CMMa_PCE SG_ 193 WRSLDWhlDistPlsCntr "0";
BA_REL_ "GenSigSuprvResp" BU_SG_REL_ CMMa_PCE SG_ 193 WRSLDWhlDistPlsCntr 1;
BA_REL_ "GenSigTimeoutMsg" BU_SG_REL_ CMMa_PCE SG_ 193 WRSLDWhlDistPlsCntr 193;
BA_REL_ "GenSigTimeoutTime" BU_SG_REL_ CMMa_PCE SG_ 193 WRSLDWhlDistPlsCntr 30;
BA_REL_ "GenSigSuprvResp" BU_SG_REL_ SDM_PCE SG_ 193 WRSLDWhlDistPlsCntr 1;
BA_REL_ "GenSigTimeoutMsg" BU_SG_REL_ SDM_PCE SG_ 193 WRSLDWhlDistPlsCntr 193;
BA_REL_ "GenSigTimeoutTime" BU_SG_REL_ SDM_PCE SG_ 193 WRSLDWhlDistPlsCntr 250;
BA_REL_ "GenSigRxStartValue" BU_SG_REL_ CMMb_PCE SG_ 193 WRSRDWhlDisTpRC "0";
BA_REL_ "GenSigSuprvResp" BU_SG_REL_ CMMb_PCE SG_ 193 WRSRDWhlDisTpRC 1;
BA_REL_ "GenSigTimeoutMsg" BU_SG_REL_ CMMb_PCE SG_ 193 WRSRDWhlDisTpRC 193;
BA_REL_ "GenSigTimeoutTime" BU_SG_REL_ CMMb_PCE SG_ 193 WRSRDWhlDisTpRC 30;
BA_REL_ "GenSigRxStartValue" BU_SG_REL_ CMMa_PCE SG_ 193 WRSRDWhlDisTpRC "0";
BA_REL_ "GenSigSuprvResp" BU_SG_REL_ CMMa_PCE SG_ 193 WRSRDWhlDisTpRC 1;
BA_REL_ "GenSigTimeoutMsg" BU_SG_REL_ CMMa_PCE SG_ 193 WRSRDWhlDisTpRC 193;
BA_REL_ "GenSigTimeoutTime" BU_SG_REL_ CMMa_PCE SG_ 193 WRSRDWhlDisTpRC 30;
BA_REL_ "GenSigSuprvResp" BU_SG_REL_ SDM_PCE SG_ 193 WRSRDWhlDisTpRC 1;
BA_REL_ "GenSigTimeoutMsg" BU_SG_REL_ SDM_PCE SG_ 193 WRSRDWhlDisTpRC 193;
BA_REL_ "GenSigTimeoutTime" BU_SG_REL_ SDM_PCE SG_ 193 WRSRDWhlDisTpRC 250;
BA_REL_ "GenSigRxStartValue" BU_SG_REL_ CMMb_PCE SG_ 193 WRSRDSeqNum "0";
BA_REL_ "GenSigSuprvResp" BU_SG_REL_ CMMb_PCE SG_ 193 WRSRDSeqNum 1;
BA_REL_ "GenSigTimeoutMsg" BU_SG_REL_ CMMb_PCE SG_ 193 WRSRDSeqNum 193;
BA_REL_ "GenSigTimeoutTime" BU_SG_REL_ CMMb_PCE SG_ 193 WRSRDSeqNum 30;
BA_REL_ "GenSigRxStartValue" BU_SG_REL_ CMMa_PCE SG_ 193 WRSRDSeqNum "0";
BA_REL_ "GenSigSuprvResp" BU_SG_REL_ CMMa_PCE SG_ 193 WRSRDSeqNum 1;
BA_REL_ "GenSigTimeoutMsg" BU_SG_REL_ CMMa_PCE SG_ 193 WRSRDSeqNum 193;
BA_REL_ "GenSigTimeoutTime" BU_SG_REL_ CMMa_PCE SG_ 193 WRSRDSeqNum 30;
BA_REL_ "GenSigSuprvResp" BU_SG_REL_ SDM_PCE SG_ 193 WRSRDSeqNum 1;
BA_REL_ "GenSigTimeoutMsg" BU_SG_REL_ SDM_PCE SG_ 193 WRSRDSeqNum 193;
BA_REL_ "GenSigTimeoutTime" BU_SG_REL_ SDM_PCE SG_ 193 WRSRDSeqNum 250;
BA_REL_ "GenSigRxStartValue" BU_SG_REL_ CMMb_PCE SG_ 193 WRSRDWhlRotStatRst "0";
BA_REL_ "GenSigSuprvResp" BU_SG_REL_ CMMb_PCE SG_ 193 WRSRDWhlRotStatRst 1;
BA_REL_ "GenSigTimeoutMsg" BU_SG_REL_ CMMb_PCE SG_ 193 WRSRDWhlRotStatRst 193;
BA_REL_ "GenSigTimeoutTime" BU_SG_REL_ CMMb_PCE SG_ 193 WRSRDWhlRotStatRst 30;
BA_REL_ "GenSigRxStartValue" BU_SG_REL_ CMMa_PCE SG_ 193 WRSRDWhlRotStatRst "0";
BA_REL_ "GenSigSuprvResp" BU_SG_REL_ CMMa_PCE SG_ 193 WRSRDWhlRotStatRst 1;
BA_REL_ "GenSigTimeoutMsg" BU_SG_REL_ CMMa_PCE SG_ 193 WRSRDWhlRotStatRst 193;
BA_REL_ "GenSigTimeoutTime" BU_SG_REL_ CMMa_PCE SG_ 193 WRSRDWhlRotStatRst 30;
BA_REL_ "GenSigSuprvResp" BU_SG_REL_ SDM_PCE SG_ 193 WRSRDWhlRotStatRst 1;
BA_REL_ "GenSigTimeoutMsg" BU_SG_REL_ SDM_PCE SG_ 193 WRSRDWhlRotStatRst 193;
BA_REL_ "GenSigTimeoutTime" BU_SG_REL_ SDM_PCE SG_ 193 WRSRDWhlRotStatRst 250;
BA_REL_ "GenSigRxStartValue" BU_SG_REL_ CMMb_PCE SG_ 193 WRSRDWhlDistVal "0";
BA_REL_ "GenSigSuprvResp" BU_SG_REL_ CMMb_PCE SG_ 193 WRSRDWhlDistVal 1;
BA_REL_ "GenSigTimeoutMsg" BU_SG_REL_ CMMb_PCE SG_ 193 WRSRDWhlDistVal 193;
BA_REL_ "GenSigTimeoutTime" BU_SG_REL_ CMMb_PCE SG_ 193 WRSRDWhlDistVal 30;
BA_REL_ "GenSigRxStartValue" BU_SG_REL_ CMMa_PCE SG_ 193 WRSRDWhlDistVal "0";
BA_REL_ "GenSigSuprvResp" BU_SG_REL_ CMMa_PCE SG_ 193 WRSRDWhlDistVal 1;
BA_REL_ "GenSigTimeoutMsg" BU_SG_REL_ CMMa_PCE SG_ 193 WRSRDWhlDistVal 193;
BA_REL_ "GenSigTimeoutTime" BU_SG_REL_ CMMa_PCE SG_ 193 WRSRDWhlDistVal 30;
BA_REL_ "GenSigSuprvResp" BU_SG_REL_ SDM_PCE SG_ 193 WRSRDWhlDistVal 1;
BA_REL_ "GenSigTimeoutMsg" BU_SG_REL_ SDM_PCE SG_ 193 WRSRDWhlDistVal 193;
BA_REL_ "GenSigTimeoutTime" BU_SG_REL_ SDM_PCE SG_ 193 WRSRDWhlDistVal 250;
BA_REL_ "GenSigRxStartValue" BU_SG_REL_ CMMb_PCE SG_ 193 WRSRDWhlDistTmstm "0";
BA_REL_ "GenSigSuprvResp" BU_SG_REL_ CMMb_PCE SG_ 193 WRSRDWhlDistTmstm 1;
BA_REL_ "GenSigTimeoutMsg" BU_SG_REL_ CMMb_PCE SG_ 193 WRSRDWhlDistTmstm 193;
BA_REL_ "GenSigTimeoutTime" BU_SG_REL_ CMMb_PCE SG_ 193 WRSRDWhlDistTmstm 30;
BA_REL_ "GenSigRxStartValue" BU_SG_REL_ CMMa_PCE SG_ 193 WRSRDWhlDistTmstm "0";
BA_REL_ "GenSigSuprvResp" BU_SG_REL_ CMMa_PCE SG_ 193 WRSRDWhlDistTmstm 1;
BA_REL_ "GenSigTimeoutMsg" BU_SG_REL_ CMMa_PCE SG_ 193 WRSRDWhlDistTmstm 193;
BA_REL_ "GenSigTimeoutTime" BU_SG_REL_ CMMa_PCE SG_ 193 WRSRDWhlDistTmstm 30;
BA_REL_ "GenSigSuprvResp" BU_SG_REL_ SDM_PCE SG_ 193 WRSRDWhlDistTmstm 1;
BA_REL_ "GenSigTimeoutMsg" BU_SG_REL_ SDM_PCE SG_ 193 WRSRDWhlDistTmstm 193;
BA_REL_ "GenSigTimeoutTime" BU_SG_REL_ SDM_PCE SG_ 193 WRSRDWhlDistTmstm 250;
BA_REL_ "GenSigRxStartValue" BU_SG_REL_ CMMb_PCE SG_ 193 WRSRDWhlDistPlsCntr "0";
BA_REL_ "GenSigSuprvResp" BU_SG_REL_ CMMb_PCE SG_ 193 WRSRDWhlDistPlsCntr 1;
BA_REL_ "GenSigTimeoutMsg" BU_SG_REL_ CMMb_PCE SG_ 193 WRSRDWhlDistPlsCntr 193;
BA_REL_ "GenSigTimeoutTime" BU_SG_REL_ CMMb_PCE SG_ 193 WRSRDWhlDistPlsCntr 30;
BA_REL_ "GenSigRxStartValue" BU_SG_REL_ CMMa_PCE SG_ 193 WRSRDWhlDistPlsCntr "0";
BA_REL_ "GenSigSuprvResp" BU_SG_REL_ CMMa_PCE SG_ 193 WRSRDWhlDistPlsCntr 1;
BA_REL_ "GenSigTimeoutMsg" BU_SG_REL_ CMMa_PCE SG_ 193 WRSRDWhlDistPlsCntr 193;
BA_REL_ "GenSigTimeoutTime" BU_SG_REL_ CMMa_PCE SG_ 193 WRSRDWhlDistPlsCntr 30;
BA_REL_ "GenSigSuprvResp" BU_SG_REL_ SDM_PCE SG_ 193 WRSRDWhlDistPlsCntr 1;
BA_REL_ "GenSigTimeoutMsg" BU_SG_REL_ SDM_PCE SG_ 193 WRSRDWhlDistPlsCntr 193;
BA_REL_ "GenSigTimeoutTime" BU_SG_REL_ SDM_PCE SG_ 193 WRSRDWhlDistPlsCntr 250;
VAL_ 339 CoPRVBAtvRed 1 "true" 0 "false" ;
VAL_ 339 CoPCIBAtvRed 1 "true" 0 "false" ;
VAL_ 339 CPEPSWARR_ReqdState 2 "Active" 1 "Inactive" 0 "No Action" ;
VAL_ 339 CoPEPBReqRed 2 "Request Release" 1 "Request Apply" 0 "No Request" ;
VAL_ 339 CoPCntrlFailRed 1 "true" 0 "false" ;
VAL_ 339 CoPAutoBrkReqTypeRed 2 "Standstill Hold Request" 1 "Brake Torque Request" 0 "No Request" 3 "Brake Prefill" ;
VAL_ 201 EngTrqActExtRngV 1 "Invalid" 0 "Valid" ;
VAL_ 201 EngRunAtv 1 "true" 0 "false" ;
VAL_ 201 EngOffTmExtRngV 1 "Invalid" 0 "Valid" ;
VAL_ 201 EngVDA 1 "VirtualDeviceAvailable" 0 "VirtualDeviceUnavailable" ;
VAL_ 201 PT_CrnkAct 1 "true" 0 "false" ;
VAL_ 201 Eng12vStrtrMtrCmmdOn 1 "true" 0 "false" ;
VAL_ 201 EngSpdStat 3 "Invalid" 1 "Degraded Operation" 0 "Normal Operation" ;
VAL_ 201 EngRunng 1 "true" 0 "false" ;
VAL_ 201 EngOffTmVDA 1 "VirtualDeviceAvailable" 0 "VirtualDeviceUnavailable" ;
VAL_ 381 ABRS2_BcupESCDatInpSt 1 "Failed" 0 "Normal" ;
VAL_ 381 ABRS2_ACCAutBkRqPrBsSt 7 "Not Used 2" 6 "Not Used 1" 5 "Request Out Of Range" 4 "CAN Error" 3 "Failed" 2 "Limited" 1 "Active" 0 "Not Active" ;
VAL_ 381 ABRS2_SAAYawMtReqScBsSt 7 "Not Used 2" 6 "Not Used 1" 5 "Request Out Of Range" 4 "CAN Error" 3 "Failed" 2 "Limited" 1 "Active" 0 "Not Active" ;
VAL_ 381 StrAngSnsPolRat 0 "Not Passed" 1 "Passed" ;
VAL_ 381 ActVehAccelV 1 "Invalid" 0 "Valid" ;
VAL_ 381 LatAccSnsPolRat 0 "Not Passed" 1 "Passed" ;
VAL_ 530 ABSFld 1 "true" 0 "false" ;
VAL_ 530 BPDAPS_BkPDrvApPV 1 "Invalid" 0 "Valid" ;
VAL_ 530 ABSAtv 1 "true" 0 "false" ;
VAL_ 530 NotEventStat 2 "Pretensioner Deployment Event" 1 "Near Deployment Event" 0 "No Event" 3 "Airbag Deployment Event" ;
VAL_ 530 BrkAppSnsrHmPosLrnd 1 "true" 0 "false" ;
VAL_ 530 BrkPdlModTrvlV 1 "Invalid" 0 "Valid" ;
VAL_ 530 BrkPdlModTrvl 1 "true" 0 "false" ;
VAL_ 530 PrplsnSysAtv 1 "true" 0 "false" ;
VAL_ 565 BrkPdlDrvApplPresV 1 "Invalid" 0 "Valid" ;
VAL_ 565 ChsSysTrnsShfBhvRq 7 "Upshift" 6 "Downshift" 5 "Minimum Inertia" 4 "Immediate Mode" 3 "Inhibit Shift" 2 "Inhibit Upshift" 1 "Inhibit Downshift" 0 "No Action" ;
VAL_ 832 BrkPedTrvlAchvd 1 "true" 0 "false" ;
VAL_ 832 BrkPedTrvlAchvdV 1 "Invalid" 0 "Valid" ;
VAL_ 832 AccActPosV 1 "Invalid" 0 "Valid" ;
VAL_ 273 DgWhlBrkActvIntfTyp 0 "Not Active" 1 "Primary Brake Request" 2 "Secondary Brake Request" ;
VAL_ 272 ADIMCntrlFailed 1 "true" 0 "false" ;
VAL_ 272 ExtVehCtrlSts 3 "Invalid" 2 "Active" 1 "Authenticate" 0 "Intialize" ;
VAL_ 272 VehMdMngrSt 0 "Unknown" 1 "Manual" 2 "Autonomous Supervised" 3 "Supervisor Override" 4 "Autonomous Unsupervised" 5 "Failed" ;
VAL_ 272 AutoEPBReq 2 "Request Release" 1 "Request Apply" 0 "No Request" ;
VAL_ 272 AutoBrkSysRdcPerDet 1 "true" 0 "false" ;
VAL_ 272 AutoBrkReqType 2 "Standstill Hold Request" 1 "Brake Torque Request" 0 "No Request" 3 "Brake Prefill" ;
VAL_ 320 IMULonAccPriV 1 "Invalid" 0 "Valid" ;
VAL_ 320 IMUXAxisClbrtd 0 "Not Calibrated" 1 "Calibrated" ;
VAL_ 320 IMUXAxisOrntn 0 "Connector Forward" 1 "Connector Rearward" ;
VAL_ 320 IMUPriYawDrftTyp 0 "Base" 1 "Low Drift" ;
VAL_ 320 IMUDataMsk 1 "true" 0 "false" ;
VAL_ 320 IMUYawRtSecAval 1 "true" 0 "false" ;
VAL_ 320 IMULatAccSecAval 1 "true" 0 "false" ;
VAL_ 320 IMUYawRtSecV 1 "Invalid" 0 "Valid" ;
VAL_ 320 IMULatACCSecV 1 "Invalid" 0 "Valid" ;
VAL_ 304 IMULonAccPriAval 1 "true" 0 "false" ;
VAL_ 304 IMULonAccSecAval 1 "true" 0 "false" ;
VAL_ 304 IMULonAccSecV 1 "Invalid" 0 "Valid" ;
VAL_ 304 IMUYawRtPriV 1 "Invalid" 0 "Valid" ;
VAL_ 304 IMULatAccPrimV 1 "Invalid" 0 "Valid" ;
VAL_ 840 WhlRotDrctnlStRtDrvn 0 "Unknown" 1 "Forward" 2 "Reverse" 3 "Not Supported" 4 "Failed" 5 "Reserved 1" 6 "Reserved 2" 7 "Reserved 3" ;
VAL_ 840 WhlRotDrctnlStLftDrvn 0 "Unknown" 1 "Forward" 2 "Reverse" 3 "Not Supported" 4 "Failed" 5 "Reserved 1" 6 "Reserved 2" 7 "Reserved 3" ;
VAL_ 840 WhlGrndVlctyRtDrvnV 1 "Invalid" 0 "Valid" ;
VAL_ 840 WhlGrndVlctyLftDrvnV 1 "Invalid" 0 "Valid" ;
VAL_ 842 WhlRotDrctnlSRtNDrvn 0 "Unknown" 1 "Forward" 2 "Reverse" 3 "Not Supported" 4 "Failed" 5 "Reserved 1" 6 "Reserved 2" 7 "Reserved 3" ;
VAL_ 842 WhlRotDrctnlStLfNDrvn 0 "Unknown" 1 "Forward" 2 "Reverse" 3 "Not Supported" 4 "Failed" 5 "Reserved 1" 6 "Reserved 2" 7 "Reserved 3" ;
VAL_ 842 WhlGrndVlctyRtNnDrvnV 1 "Invalid" 0 "Valid" ;
VAL_ 842 WhlGrndVlctyLftNnDrvnV 1 "Invalid" 0 "Valid" ;
VAL_ 1001 VehSpdAvgNDrvnV 1 "Invalid" 0 "Valid" ;
VAL_ 1001 VehSpdAvgDrvnV 1 "Invalid" 0 "Valid" ;
VAL_ 1001 VehSpdAvgDrvnSrc 1 "Wheel Speed" 0 "Transmission Output Speed" ;
VAL_ 197 WRSLNDWhlRotStRst 1 "true" 0 "false" ;
VAL_ 197 WRSLNDWhlDistVal 1 "Invalid" 0 "Valid" ;
VAL_ 197 WRSRNDWhlRotStRst 1 "true" 0 "false" ;
VAL_ 197 WRSRNDWhlDistVal 1 "Invalid" 0 "Valid" ;
VAL_ 289 SysPwMdVDA 1 "VirtualDeviceAvailable" 0 "VirtualDeviceUnavailable" ;
VAL_ 289 TrStLgMdAtv 1 "true" 0 "false" ;
VAL_ 289 SysPwrMd 3 "Crank Request" 2 "Run" 1 "Accessory" 0 "Off" ;
VAL_ 290 BkupPwrModeMstrVDA 1 "VirtualDeviceAvailable" 0 "VirtualDeviceUnavailable" ;
VAL_ 290 SysBkupPwrMdEn 1 "true" 0 "false" ;
VAL_ 290 SysBkUpPwrMd 3 "Crank Request" 2 "Run" 1 "Accessory" 0 "Off" ;
VAL_ 485 StrWhAngGrdV 1 "Invalid" 0 "Valid" ;
VAL_ 485 StrWhAngGrdMsk 1 "Use Data" 0 "Don't Use Data" ;
VAL_ 485 StrWhAngMsk 1 "Use Data" 0 "Don't Use Data" ;
VAL_ 485 StrWhlAngSenTyp 0 "Type 1" 1 "Type 2" 2 "Type 3" 3 "Type 4" ;
VAL_ 485 StrWhlAngSenCalStat 2 "Calibrated" 1 "Estimated" 0 "Unknown" ;
VAL_ 485 StrWhAngV 1 "Invalid" 0 "Valid" ;
VAL_ 193 WRSLDWhlRotStatRst 1 "true" 0 "false" ;
VAL_ 193 WRSLDWhlDistVal 1 "Invalid" 0 "Valid" ;
VAL_ 193 WRSRDWhlRotStatRst 1 "true" 0 "false" ;
VAL_ 193 WRSRDWhlDistVal 1 "Invalid" 0 "Valid" ;
SIG_GROUP_ 339 CoPEPSWhlAngReqRed 1 : CPEPSWARR_TrgtAng CPEPSWARR_ReqdState;
SIG_GROUP_ 381 AutBrkReqStat2 1 : ABRS2_BcupESCDatInpSt ABRS2_ACCAutBkRqPrBsSt ABRS2_SAAYawMtReqScBsSt;
SIG_GROUP_ 530 BrkPdDrvAppPrsStat 1 : BPDAPS_BkPDrvApPV BPDAPS_BkPDrvApP;
SIG_GROUP_ 832 BrkPedInitTrvlAchvdStat 1 : BrkPedTrvlAchvd BrkPedTrvlAchvdV;
SIG_GROUP_ 197 WhlRotStatLftNDrvn 1 : WRSLNDWhlDisTpRC WRSLNDWhlRotStRst WRSLNDWhlDistVal WRSLNDWhlDistTstm WRSLNDWhlDistPCntr WRSLNDSeqNum;
SIG_GROUP_ 197 WhlRotStatRghtNDrvn 1 : WRSRNDWhlRotStRst WRSRNDWhlDisTpRC WRSRNDWhlDistVal WRSRNDWhlDistTstm WRSRNDWhlDistPCntr WRSRNDSeqNum;
SIG_GROUP_ 192 WhlRotatStatChkData 1 : WRSCD_RNDrvnCkVa WRSCD_LfNDrvnCkVa WRSCD_RDrvnCkVa WRSCD_LfDrvnCkVa WRSCD_RtNDrvnSNm WRSCD_LftNDrvnSNm WRSCD_RtDrvnSqNm WRSCD_LftDrvnSqNm;
SIG_GROUP_ 193 WhlRotatStatLftDrvn 1 : WRSLDWhlRotStatRst WRSLDWhlDisTpRC WRSLDSeqNum WRSLDWhlDistVal WRSLDWhlDistTmstm WRSLDWhlDistPlsCntr;
SIG_GROUP_ 193 WhlRotatStatRtDrvn 1 : WRSRDWhlDisTpRC WRSRDSeqNum WRSRDWhlRotStatRst WRSRDWhlDistVal WRSRDWhlDistTmstm WRSRDWhlDistPlsCntr;
